VERSION ""

NS_ :

BS_:

BU_: TCM HCM IPMA_ADAS PSCM ABS_ESC TCCM TCM_DSL PCM_HEV PCM ECM_HEVDSL ECM_HEV ECM_Diesel ECM SIMA_DLCS BCMD_IPDB VDM CMR_DSMC SOBDMC_HPCM CHCM GWM _delete AWD_DLCM GENERIC TSTR

BO_ 611 Driveline_Data_1: 8 PCM
 SG_ AwdTerrMdeChng_D_Rdy : 58|3@0+ (1,0) [0|7] "SED"  GWM
 SG_ AwdTerrMde_D_Actl : 50|3@0+ (1,0) [0|7] "SED"  GWM
 SG_ AwdSys_D_Stat : 27|2@0+ (1,0) [0|3] "SED"  GWM,ECM,ECM_Diesel,ECM_HEVDSL,PCM,PCM_HEV
 SG_ SelDrvMdeAwd_D_Stat : 33|2@0+ (1,0) [0|3] "SED"  GWM,ABS_ESC
 SG_ AwdStat_D_RqDsply : 63|5@0+ (1,0) [0|31] "SED"  PCM_HEV,PCM,ABS_ESC,AWD_DLCM,TCM,TCM_DSL,GWM
 SG_ AwdLck_D_Stat : 31|4@0+ (1,0) [0|15] "SED"  ABS_ESC,PSCM,TCM,TCM_DSL,GWM,PCM
 SG_ AwdSrvcRqd_B_Rq : 0|1@0+ (1,0) [0|1] "SED"  TCM,ABS_ESC,PCM,PCM_HEV,TCM_DSL,GWM
 SG_ AwdDrvMde_D_Stat : 38|3@0+ (1,0) [0|7] "SED"  GWM,PSCM
 SG_ NtrlTowAvail_B_Stat : 4|1@0+ (1,0) [0|1] "SED"  GWM
 SG_ AwdLck_Tq_Rq : 15|12@0+ (1,0) [0|4093] "Nm"  PCM_HEV,PCM,ABS_ESC,GWM,SOBDMC_HPCM
 SG_ TrnAout_Tq_RqMx : 47|13@0+ (1,-1250) [-1250|6941] "Nm"  GWM,ECM,ECM_Diesel,ECM_HEVDSL,PCM,PCM_HEV
 SG_ AwdOffRoadMode_D_Stats : 25|2@0+ (1,0) [0|3] "SED"  IPMA_ADAS,GWM,ABS_ESC
 SG_ AwdLoLamp_D_RqDsply : 35|2@0+ (1,0) [0|3] "SED"  GWM
 SG_ AwdHiLamp_D_RqDsply : 19|2@0+ (1,0) [0|3] "SED"  GWM,ABS_ESC
 SG_ AwdAutoLamp_D_RqDsply : 17|2@0+ (1,0) [0|3] "SED"  GWM,ABS_ESC
 SG_ Awd2wdLamp_D_RqDsply : 2|2@0+ (1,0) [0|3] "SED"  GWM
 SG_ AwdRnge_D_Actl : 7|3@0+ (1,0) [0|7] "SED"  TCM,ECM,ECM_Diesel,ECM_HEVDSL,PCM,PCM_HEV,TCM_DSL,ABS_ESC,PSCM,SOBDMC_HPCM,VDM,GWM,CHCM,AWD_DLCM,IPMA_ADAS

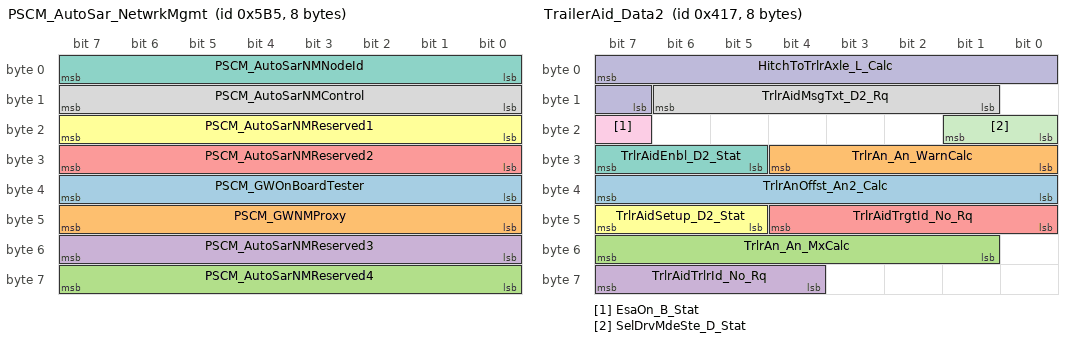
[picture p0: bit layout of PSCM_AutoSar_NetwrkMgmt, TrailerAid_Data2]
BO_ 1461 PSCM_AutoSar_NetwrkMgmt: 8 PSCM
 SG_ PSCM_GWOnBoardTester : 39|8@0+ (1,0) [0|255] "unitless"  HCM,GENERIC,ABS_ESC
 SG_ PSCM_GWNMProxy : 47|8@0+ (1,0) [0|255] "unitless"  HCM,GENERIC,ABS_ESC
 SG_ PSCM_AutoSarNMReserved4 : 63|8@0+ (1,0) [0|255] "unitless"  HCM,GENERIC,ABS_ESC
 SG_ PSCM_AutoSarNMReserved3 : 55|8@0+ (1,0) [0|255] "unitless"  HCM,GENERIC,ABS_ESC
 SG_ PSCM_AutoSarNMReserved2 : 31|8@0+ (1,0) [0|255] "unitless"  HCM,ABS_ESC,GENERIC
 SG_ PSCM_AutoSarNMReserved1 : 23|8@0+ (1,0) [0|255] "unitless"  HCM,ABS_ESC,GENERIC
 SG_ PSCM_AutoSarNMNodeId : 7|8@0+ (1,0) [0|255] "unitless"  HCM,ABS_ESC,GENERIC
 SG_ PSCM_AutoSarNMControl : 15|8@0+ (1,0) [0|255] "unitless"  HCM,ABS_ESC,GENERIC

BO_ 1047 TrailerAid_Data2: 8 PSCM
 SG_ TrlrAnOffst_An2_Calc : 39|8@0+ (0.5,-64) [-64|63.5] "degrees"  IPMA_ADAS
 SG_ TrlrAn_An_WarnCalc : 28|5@0+ (1,0) [0|31] "degrees"  IPMA_ADAS
 SG_ TrlrAn_An_MxCalc : 55|7@0+ (1,0) [0|127] "degrees"  IPMA_ADAS
 SG_ TrlrAidTrlrId_No_Rq : 63|4@0+ (1,0) [0|15] "unitless"  GWM
 SG_ TrlrAidTrgtId_No_Rq : 44|5@0+ (1,0) [0|31] "unitless"  IPMA_ADAS
 SG_ TrlrAidSetup_D2_Stat : 47|3@0+ (1,0) [0|7] "SED"  IPMA_ADAS
 SG_ TrlrAidEnbl_D2_Stat : 31|3@0+ (1,0) [0|7] "SED"  ECM_HEV,IPMA_ADAS,GWM,ECM,PCM,ABS_ESC,ECM_Diesel,ECM_HEVDSL,PCM_HEV
 SG_ TrlrAidMsgTxt_D2_Rq : 14|6@0+ (1,0) [0|63] "SED"  IPMA_ADAS,GWM,ABS_ESC
 SG_ EsaOn_B_Stat : 23|1@0+ (1,0) [0|1] "SED"  GWM
 SG_ HitchToTrlrAxle_L_Calc : 7|9@0+ (0.0254,0) [0|12.9794] "meter"  IPMA_ADAS
 SG_ SelDrvMdeSte_D_Stat : 17|2@0+ (1,0) [0|3] "SED"  ABS_ESC

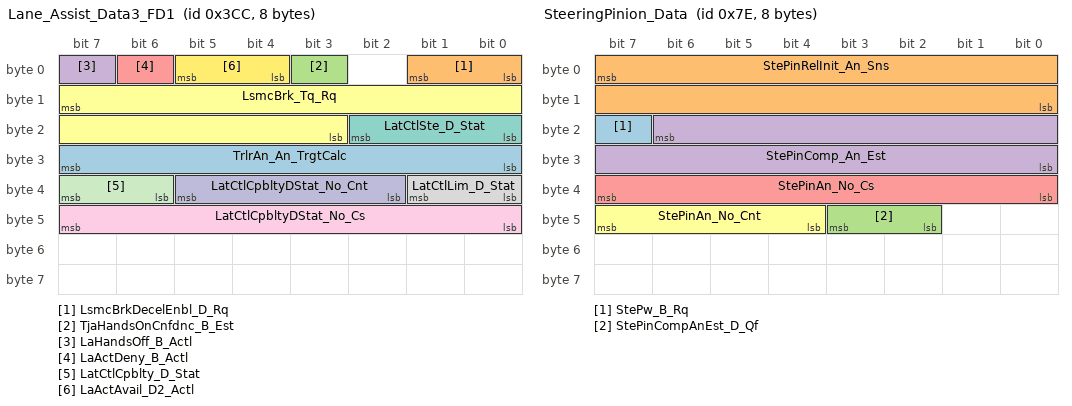
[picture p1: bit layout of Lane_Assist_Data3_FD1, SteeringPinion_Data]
BO_ 972 Lane_Assist_Data3_FD1: 8 PSCM
 SG_ TrlrAn_An_TrgtCalc : 31|8@0+ (1,-128) [-128|127] "degrees"  GWM,IPMA_ADAS
 SG_ LsmcBrkDecelEnbl_D_Rq : 1|2@0+ (1,0) [0|3] "SED"  GWM,ABS_ESC
 SG_ TjaHandsOnCnfdnc_B_Est : 3|1@0+ (1,0) [0|1] "SED"  GWM,IPMA_ADAS
 SG_ LaHandsOff_B_Actl : 7|1@0+ (1,0) [0|1] "SED"  IPMA_ADAS,GWM
 SG_ LaActDeny_B_Actl : 6|1@0+ (1,0) [0|1] "SED"  IPMA_ADAS,GWM
 SG_ LsmcBrk_Tq_Rq : 15|13@0+ (4,0) [0|32764] "Nm"  GWM,ABS_ESC
 SG_ LatCtlSte_D_Stat : 18|3@0+ (1,0) [0|7] "SED"  IPMA_ADAS,GWM
 SG_ LatCtlLim_D_Stat : 33|2@0+ (1,0) [0|3] "SED"  IPMA_ADAS,GWM
 SG_ LatCtlCpbltyDStat_No_Cs : 47|8@0+ (1,0) [0|255] "Unitless"  GWM,IPMA_ADAS
 SG_ LatCtlCpbltyDStat_No_Cnt : 37|4@0+ (1,0) [0|15] "Unitless"  GWM,IPMA_ADAS
 SG_ LatCtlCpblty_D_Stat : 39|2@0+ (1,0) [0|3] "SED"  GWM,IPMA_ADAS
 SG_ LaActAvail_D2_Actl : 5|2@0+ (1,0) [0|3] "SED"  IPMA_ADAS,GWM

BO_ 130 EPAS_INFO: 8 PSCM
 SG_ TrlrHitchLamp_D_Rqst : 24|1@0+ (1,0) [0|1] "SED"  IPMA_ADAS,GWM
 SG_ VehVTrlrAid_B_Rq : 25|1@0+ (1,0) [0|1] "SED"  ECM_HEV,ECM,ECM_Diesel,ECM_HEVDSL,PCM,PCM_HEV
 SG_ SteEffort_D_Stat : 52|3@0+ (1,0) [0|7] "SED"  GWM
 SG_ Veh_V_RqMxTrlrAid : 63|8@0+ (0.1,0) [0|25.5] "km/h"  ECM_HEV,ECM,ECM_Diesel,ECM_HEVDSL,PCM,PCM_HEV
 SG_ DrvSteActv_B_Stat : 10|1@0+ (1,0) [0|1] "SED"  ABS_ESC
 SG_ DrvSte_Tq_Actl : 47|8@0+ (0.0625,-8) [-8|7.8125] "Nm"  ABS_ESC
 SG_ SteMdule_D_Stat : 55|3@0+ (1,0) [0|7] "SED"  GWM
 SG_ SteMdule_U_Meas : 39|8@0+ (0.05,6) [6|18.7] "Volts"  GWM
 SG_ SteMdule_I_Est : 21|12@0+ (0.05,-64) [-64|140.7] "Amps"  GWM
 SG_ EPAS_Failure : 9|2@0+ (1,0) [0|3] "SED"  IPMA_ADAS,GWM
 SG_ SteeringColumnTorque : 7|8@0+ (0.0625,-8) [-8|7.8125] "Nm"  IPMA_ADAS,ABS_ESC
 SG_ SAPPAngleControlStat6 : 15|1@0+ (1,0) [0|1] "SED"  IPMA_ADAS
 SG_ SAPPAngleControlStat5 : 14|1@0+ (1,0) [0|1] "SED"  IPMA_ADAS
 SG_ SAPPAngleControlStat4 : 13|1@0+ (1,0) [0|1] "SED"  IPMA_ADAS
 SG_ SAPPAngleControlStat3 : 12|1@0+ (1,0) [0|1] "SED"  IPMA_ADAS
 SG_ SAPPAngleControlStat2 : 11|1@0+ (1,0) [0|1] "SED"  IPMA_ADAS
 SG_ SAPPAngleControlStat1 : 23|2@0+ (1,0) [0|3] "SED"  IPMA_ADAS

BO_ 126 SteeringPinion_Data: 8 PSCM
 SG_ StePw_B_Rq : 23|1@0+ (1,0) [0|1] "SED"  GWM,ECM,ECM_Diesel,ECM_HEV,ECM_HEVDSL,PCM,PCM_HEV
 SG_ StePinRelInit_An_Sns : 7|16@0+ (0.1,-3200) [-3200|3353.3] "degrees"  VDM,IPMA_ADAS,GWM,ECM,ECM_Diesel,ECM_HEV,ECM_HEVDSL,PCM,PCM_HEV,ABS_ESC,TCCM,AWD_DLCM
 SG_ StePinCompAnEst_D_Qf : 43|2@0+ (1,0) [0|3] "SED"  CMR_DSMC,TCM,VDM,SOBDMC_HPCM,HCM,IPMA_ADAS,TCM_DSL,ECM,ECM_Diesel,ECM_HEV,ECM_HEVDSL,PCM,PCM_HEV,ABS_ESC,TCCM,AWD_DLCM,GWM
 SG_ StePinComp_An_Est : 22|15@0+ (0.1,-1600) [-1600|1676.7] "degrees"  CMR_DSMC,TCM,VDM,SOBDMC_HPCM,HCM,IPMA_ADAS,TCM_DSL,ECM,ECM_Diesel,ECM_HEV,ECM_HEVDSL,PCM,PCM_HEV,ABS_ESC,TCCM,AWD_DLCM,GWM
 SG_ StePinAn_No_Cs : 39|8@0+ (1,0) [0|255] "Unitless"  VDM,ABS_ESC,TCCM,GWM,ECM,ECM_Diesel,ECM_HEVDSL,PCM,PCM_HEV,AWD_DLCM
 SG_ StePinAn_No_Cnt : 47|4@0+ (1,0) [0|15] "unitless"  VDM,TCCM,GWM,ECM,ECM_Diesel,ECM_HEVDSL,PCM,PCM_HEV,ABS_ESC,AWD_DLCM

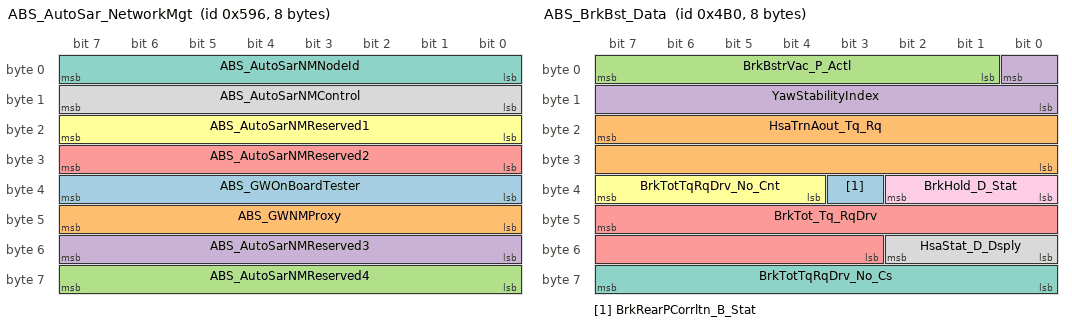
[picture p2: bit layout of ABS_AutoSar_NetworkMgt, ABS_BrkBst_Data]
BO_ 1430 ABS_AutoSar_NetworkMgt: 8 ABS_ESC
 SG_ ABS_GWOnBoardTester : 39|8@0+ (1,0) [0|255] "unitless"  HCM,GENERIC
 SG_ ABS_GWNMProxy : 47|8@0+ (1,0) [0|255] "unitless"  HCM,GENERIC
 SG_ ABS_AutoSarNMReserved4 : 63|8@0+ (1,0) [0|255] "unitless"  HCM,GENERIC
 SG_ ABS_AutoSarNMReserved3 : 55|8@0+ (1,0) [0|255] "unitless"  HCM,GENERIC
 SG_ ABS_AutoSarNMReserved2 : 31|8@0+ (1,0) [0|255] "unitless"  HCM,GENERIC
 SG_ ABS_AutoSarNMReserved1 : 23|8@0+ (1,0) [0|255] "unitless"  HCM,GENERIC
 SG_ ABS_AutoSarNMNodeId : 7|8@0+ (1,0) [0|255] "unitless"  HCM,GENERIC
 SG_ ABS_AutoSarNMControl : 15|8@0+ (1,0) [0|255] "unitless"  HCM,GENERIC

BO_ 1200 ABS_BrkBst_Data: 8 ABS_ESC
 SG_ BrkRearPCorrltn_B_Stat : 35|1@0+ (1,0) [0|1] "SED"  GWM
 SG_ HsaTrnAout_Tq_Rq : 23|16@0+ (4,-131072) [-131072|131060] "Nm"  TCM,TCM_DSL,GWM
 SG_ BrkBstrVac_P_Actl : 7|7@0+ (8,0) [0|1008] "Millibar"  ECM,ECM_Diesel,ECM_HEV,ECM_HEVDSL,PCM,PCM_HEV,GWM
 SG_ YawStabilityIndex : 0|9@0+ (1,-256) [-256|255] "%"  IPMA_ADAS,PSCM,GWM,VDM,CHCM
 SG_ BrkTot_Tq_RqDrv : 47|13@0+ (4,0) [0|32760] "Nm"  SOBDMC_HPCM,TCM,IPMA_ADAS,ECM,ECM_Diesel,ECM_HEV,ECM_HEVDSL,PCM,PCM_HEV,TCM_DSL,GWM,TCCM,PSCM,AWD_DLCM
 SG_ BrkTotTqRqDrv_No_Cnt : 39|4@0+ (1,0) [0|15] "unitless"  ECM,ECM_Diesel,ECM_HEV,ECM_HEVDSL,PCM,PCM_HEV,GWM
 SG_ BrkTotTqRqDrv_No_Cs : 63|8@0+ (1,0) [0|255] "unitless"  ECM,ECM_Diesel,ECM_HEV,ECM_HEVDSL,PCM,PCM_HEV,GWM
 SG_ HsaStat_D_Dsply : 50|3@0+ (1,0) [0|7] "SED"  GWM
 SG_ BrkHold_D_Stat : 34|3@0+ (1,0) [0|7] "SED"  ECM,ECM_Diesel,ECM_HEV,ECM_HEVDSL,IPMA_ADAS,PCM,PCM_HEV,SOBDMC_HPCM,GWM,TCM_DSL

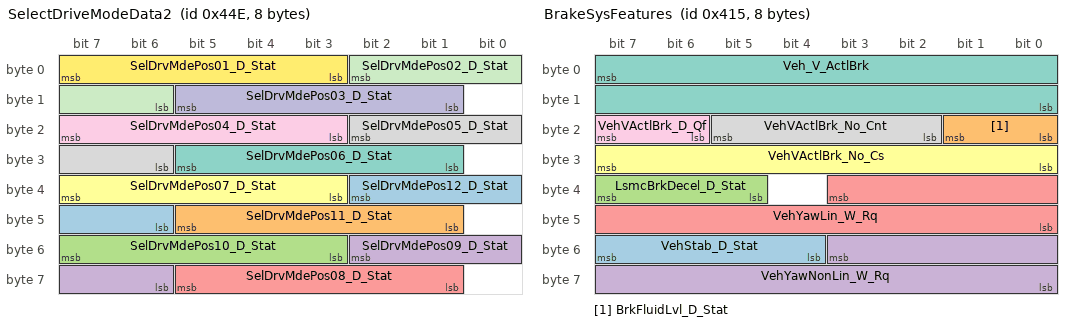
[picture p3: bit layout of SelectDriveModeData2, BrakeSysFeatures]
BO_ 1102 SelectDriveModeData2: 8 ABS_ESC
 SG_ SelDrvMdePos12_D_Stat : 34|5@0+ (1,0) [0|31] "SED"  GWM
 SG_ SelDrvMdePos11_D_Stat : 45|5@0+ (1,0) [0|31] "SED"  GWM
 SG_ SelDrvMdePos10_D_Stat : 55|5@0+ (1,0) [0|31] "SED"  GWM
 SG_ SelDrvMdePos09_D_Stat : 50|5@0+ (1,0) [0|31] "SED"  GWM
 SG_ SelDrvMdePos08_D_Stat : 61|5@0+ (1,0) [0|31] "SED"  GWM
 SG_ SelDrvMdePos07_D_Stat : 39|5@0+ (1,0) [0|31] "SED"  GWM
 SG_ SelDrvMdePos06_D_Stat : 29|5@0+ (1,0) [0|31] "SED"  GWM
 SG_ SelDrvMdePos05_D_Stat : 18|5@0+ (1,0) [0|31] "SED"  GWM
 SG_ SelDrvMdePos04_D_Stat : 23|5@0+ (1,0) [0|31] "SED"  GWM
 SG_ SelDrvMdePos03_D_Stat : 13|5@0+ (1,0) [0|31] "SED"  GWM
 SG_ SelDrvMdePos02_D_Stat : 2|5@0+ (1,0) [0|31] "SED"  GWM
 SG_ SelDrvMdePos01_D_Stat : 7|5@0+ (1,0) [0|31] "SED"  GWM

BO_ 1056 SelectDriveModeData: 8 ABS_ESC
 SG_ AutoEpbButtnOn_B_Stat : 48|1@0+ (1,0) [0|1] "SED"  GWM
 SG_ VehVActlBrk_No_Corr : 7|8@0+ (0.001,0.9) [0.9|1.153] "unitless"  ECM,ECM_Diesel,ECM_HEV,PCM,PCM_HEV,GWM
 SG_ AutoEpbMsgTxt_D_Rq : 58|3@0+ (1,0) [0|7] "SED"  GWM
 SG_ SelDrvMdePos12_B_Avail : 54|1@0+ (1,0) [0|1] "SED"  GWM
 SG_ SelDrvMdePos11_B_Avail : 55|1@0+ (1,0) [0|1] "SED"  GWM
 SG_ SelDrvMdePos10_B_Avail : 40|1@0+ (1,0) [0|1] "SED"  GWM
 SG_ SelDrvMdePos09_B_Avail : 41|1@0+ (1,0) [0|1] "SED"  GWM
 SG_ SelDrvMdePos08_B_Avail : 42|1@0+ (1,0) [0|1] "SED"  GWM
 SG_ SelDrvMdePos07_B_Avail : 43|1@0+ (1,0) [0|1] "SED"  GWM
 SG_ SelDrvMdePos06_B_Avail : 44|1@0+ (1,0) [0|1] "SED"  GWM
 SG_ SelDrvMdePos05_B_Avail : 45|1@0+ (1,0) [0|1] "SED"  GWM
 SG_ SelDrvMdePos04_B_Avail : 46|1@0+ (1,0) [0|1] "SED"  GWM
 SG_ SelDrvMdePos03_B_Avail : 47|1@0+ (1,0) [0|1] "SED"  GWM
 SG_ SelDrvMdePos02_B_Avail : 32|1@0+ (1,0) [0|1] "SED"  GWM
 SG_ SelDrvMdePos01_B_Avail : 24|1@0+ (1,0) [0|1] "SED"  GWM
 SG_ ActvDrvMde_D2_Stat : 53|5@0+ (1,0) [0|31] "SED"  IPMA_ADAS,GWM
 SG_ SelDrvMde_D2_Rq : 63|5@0+ (1,0) [0|31] "SED"  GWM
 SG_ SelDrvMdePt_D_Rq : 31|5@0+ (1,0) [0|31] "SED"  SOBDMC_HPCM,ECM,ECM_Diesel,ECM_HEV,ECM_HEVDSL,PCM,PCM_HEV,GWM,TCCM
 SG_ SelDrvMdeMsgTxt_D_Rq : 19|4@0+ (1,0) [0|15] "SED"  AWD_DLCM,GWM
 SG_ SelDrvMde_D_Stat : 26|2@0+ (1,0) [0|3] "SED"  GWM
 SG_ AwdMde_D_RqBrk : 35|3@0+ (1,0) [0|7] "SED"  GWM,TCCM
 SG_ AutoEpbDsply_D_Stat : 37|2@0+ (1,0) [0|3] "SED"  GWM
 SG_ SelDrvMdeMsgTxt2_D_Rq : 23|4@0+ (1,0) [0|15] "SED"  GWM
 SG_ SelDrvMdeHmi03_D_Rq : 12|5@0+ (1,0) [0|31] "SED"  GWM

BO_ 1054 BrakeSysFeatures_3: 8 ABS_ESC
 SG_ RbaBrk_D_Stat : 63|2@0+ (1,0) [0|3] "SED"  IPMA_ADAS,GWM
 SG_ SelDrvMdeChassis2_D_Rq : 45|5@0+ (1,0) [0|31] "SED"  PSCM,GWM
 SG_ BrkBstrLoLampOn_B_Rq : 24|1@0+ (1,0) [0|1] "SED"  GWM
 SG_ TrailCtl_D_Stat : 55|3@0+ (1,0) [0|7] "SED"  SOBDMC_HPCM,TCM,ECM,ECM_Diesel,ECM_HEV,ECM_HEVDSL,PCM,TCM_DSL,GWM,AWD_DLCM,TCCM
 SG_ TrailCtlMsgTxt_D_Rq : 52|4@0+ (1,0) [0|15] "SED"  GWM
 SG_ BrkPadMsgTxt_D_Rq : 31|2@0+ (1,0) [0|3] "SED"  GWM
 SG_ BrkBstrVac_D_Stat : 18|2@0+ (1,0) [0|3] "SED"  ECM_HEV,ECM,ECM_Diesel,ECM_HEVDSL,PCM,PCM_HEV,GWM
 SG_ DrvSlipCtlOffLamp_D_Rq : 23|2@0+ (1,0) [0|3] "SED"  GWM
 SG_ DrvSlipCtlMdeMsg_D_Rq : 13|5@0+ (1,0) [0|31] "SED"  GWM
 SG_ HdcOn_B_Ind : 16|1@0+ (1,0) [0|1] "SED"  GWM
 SG_ AutoHoldMsgTxt_D_Rq : 4|4@0+ (1,0) [0|15] "SED"  GWM
 SG_ CtaBrk_D_Stat : 47|2@0+ (1,0) [0|3] "SED"  GWM,IPMA_ADAS
 SG_ SelDrvMdeAwd_D_Rq : 29|5@0+ (1,0) [0|31] "SED"  ECM_HEV,TCCM,GWM,PCM,AWD_DLCM
 SG_ AutoHoldSwMde_B_Ind : 0|1@0+ (1,0) [0|1] "SED"  GWM
 SG_ AutoHoldMde_D_Ind : 15|2@0+ (1,0) [0|3] "SED"  GWM
 SG_ BrkMdeInhbt_B_RqDsply : 8|1@0+ (1,0) [0|1] "SED"  GWM
 SG_ BrkLineLck_D_Stat : 21|3@0+ (1,0) [0|7] "SED"  GWM,TCM,TCM_DSL
 SG_ SelDrvMdeChassis_D_Rq : 39|5@0+ (1,0) [0|31] "SED"  PSCM,GWM,VDM,CHCM
 SG_ ApaBrk_D_Stat : 34|2@0+ (1,0) [0|3] "SED"  ECM,ECM_Diesel,ECM_HEV,ECM_HEVDSL,IPMA_ADAS,PCM,PCM_HEV,GWM
 SG_ SelDrvMdeChassis3_D_Rq : 61|5@0+ (1,0) [0|31] "SED"  CHCM,GWM
 SG_ TrailOnePdlTqLm_B_Actl : 56|1@0+ (1,0) [0|1] "SED"  ECM_HEV,ECM_Diesel,PCM,GWM
 SG_ OnePdlDrvDeny_B_Stat : 40|1@0+ (1,0) [0|1] "SED"  ECM_HEV,PCM_HEV,GWM,ECM,PCM
 SG_ BrkDrvMde_D_Stat : 7|3@0+ (1,0) [0|7] "SED"  GWM
 SG_ AirDamUp_B_RqBrk : 32|1@0+ (1,0) [0|1] "SED"  ECM_Diesel,ECM_HEV,ECM_HEVDSL,PCM,PCM_HEV,GWM
 SG_ FrontDiffElckrOpen_B_Rq : 48|1@0+ (1,0) [0|1] "SED"  AWD_DLCM,GWM

BO_ 1046 BrakeSysFeatures_2: 8 ABS_ESC
 SG_ PrkBrkDynmc_D_Allw : 39|2@0+ (1,0) [0|3] "SED"  GWM
 SG_ BrkPrkBrkDynmc_B_Actl : 24|1@0+ (1,0) [0|1] "SED"  GWM
 SG_ ReserveTracCtlPtActv : 28|1@0+ (1,0) [0|1] "SED"  GENERIC,GWM
 SG_ HsaMde_D_Mem : 33|2@0+ (1,0) [0|3] "SED"  GWM
 SG_ BrkBstrVac_B_Rq : 27|1@0+ (1,0) [0|1] "Discrete"  ECM_HEV,SOBDMC_HPCM,ECM,ECM_Diesel,ECM_HEVDSL,PCM,PCM_HEV,GWM
 SG_ HdcMde_D_Actl : 31|3@0+ (1,0) [0|7] "SED"  SOBDMC_HPCM,TCM,ECM,ECM_Diesel,ECM_HEVDSL,PCM,PCM_HEV,TCM_DSL,GWM,AWD_DLCM
 SG_ RearDiffLck_Tq2_RqMx : 51|12@0+ (4,0) [0|16376] "Nm"  ECM,ECM_Diesel,ECM_HEV,ECM_HEVDSL,TCCM,GWM,PCM,AWD_DLCM
 SG_ TRLR_SWAY_EVNT_IN_PROG : 25|1@0+ (1,0) [0|1] "SED"  GWM
 SG_ TRLR_SWAY_CONFIG_STAT : 26|1@0+ (1,0) [0|1] "SED"  GWM
 SG_ TCMode : 15|1@0+ (1,0) [0|1] "SED"  SOBDMC_HPCM,TCM,IPMA_ADAS,ECM,ECM_Diesel,ECM_HEV,ECM_HEVDSL,PCM,PCM_HEV,TCM_DSL,PSCM,VDM,GWM,AWD_DLCM
 SG_ DrvSlipCtlLamp_D_Rq : 42|2@0+ (1,0) [0|3] "SED"  IPMA_ADAS,ECM,ECM_Diesel,ECM_HEV,ECM_HEVDSL,PCM,PCM_HEV,GWM,VDM,AWD_DLCM
 SG_ Abs_B_Falt : 5|1@0+ (1,0) [0|1] "SED"  TCM,SOBDMC_HPCM,ECM,ECM_Diesel,ECM_HEV,ECM_HEVDSL,PCM,PCM_HEV,TCM_DSL,GWM
 SG_ DrvSlipCtlMde_D_Ind : 44|2@0+ (1,0) [0|3] "SED"  TCM,SOBDMC_HPCM,IPMA_ADAS,ECM,ECM_Diesel,ECM_HEV,ECM_HEVDSL,PCM,PCM_HEV,TCM_DSL,PSCM,GWM,AWD_DLCM,TCCM
 SG_ DrvAntiLckLamp_D_Rq : 55|2@0+ (1,0) [0|3] "SED"  TCM,ECM,ECM_Diesel,ECM_HEV,ECM_HEVDSL,TCM_DSL,GWM,IPMA_ADAS
 SG_ BpedMove_No_Cnt : 3|4@0+ (1,0) [0|15] "Unitless"  SOBDMC_HPCM,ECM,ECM_Diesel,ECM_HEV,ECM_HEVDSL,PCM,PCM_HEV,GWM
 SG_ StabCtlBrk_B_Avail : 4|1@0+ (1,0) [0|1] "SED"  PCM,PCM_HEV,TCM,ECM,ECM_Diesel,ECM_HEV,ECM_HEVDSL,TCM_DSL,TCCM,GWM,VDM,CHCM,AWD_DLCM
 SG_ DrvHdcWarnInfo_D_Rq : 35|2@0+ (1,0) [0|3] "SED"  TCM,ECM,ECM_Diesel,ECM_HEV,ECM_HEVDSL,TCM_DSL,GWM
 SG_ DrvHdcMsg_D_Rq : 10|3@0+ (1,0) [0|7] "SED"  TCM,ECM,ECM_Diesel,ECM_HEV,ECM_HEVDSL,TCM_DSL,GWM
 SG_ DrvHdcLampInfo_D_Rq : 12|2@0+ (1,0) [0|3] "SED"  TCM,ECM,ECM_Diesel,ECM_HEV,ECM_HEVDSL,TCM_DSL,GWM
 SG_ BpedMove_D_Actl : 7|2@0+ (1,0) [0|3] "SED"  SOBDMC_HPCM,ECM,ECM_Diesel,ECM_HEV,ECM_HEVDSL,PCM,PCM_HEV,GWM
 SG_ ChimeBrk_B_Rq : 14|1@0+ (1,0) [0|1] "SED"  TCM,ECM,ECM_Diesel,ECM_HEV,ECM_HEVDSL,TCM_DSL,GWM
 SG_ BrkLamp_B_Rq : 13|1@0+ (1,0) [0|1] "SED"  TCM,ECM,ECM_Diesel,ECM_HEV,ECM_HEVDSL,TCM_DSL,GWM
 SG_ HILL_DESC_MC : 47|3@0+ (1,0) [0|7] "SED"  TCM,ECM,ECM_Diesel,ECM_HEV,ECM_HEVDSL,TCM_DSL,GWM
 SG_ BpedDiffLckTq_No_Cs : 23|8@0+ (1,0) [0|255] "Unitless"  SOBDMC_HPCM,GWM
 SG_ RearDiffElckrOpen_B_Rq : 40|1@0+ (1,0) [0|1] "SED"  SOBDMC_HPCM,GWM,AWD_DLCM,TCCM

BO_ 1045 BrakeSysFeatures: 8 ABS_ESC
 SG_ VehStab_D_Stat : 55|4@0+ (1,0) [0|15] "SED"  SOBDMC_HPCM,PCM_HEV,PCM,ECM,ECM_Diesel,ECM_HEV,ECM_HEVDSL,TCCM,GWM,HCM,AWD_DLCM,CHCM
 SG_ BrkFluidLvl_D_Stat : 17|2@0+ (1,0) [0|3] "SED"  GWM
 SG_ LsmcBrkDecel_D_Stat : 39|3@0+ (1,0) [0|7] "SED"  PSCM,GWM
 SG_ VehYawNonLin_W_Rq : 51|12@0+ (0.03663,-75) [-75|74.92659] "deg/s"  SOBDMC_HPCM,ECM,ECM_Diesel,ECM_HEV,ECM_HEVDSL,PCM,PCM_HEV,GWM,AWD_DLCM,CHCM
 SG_ VehYawLin_W_Rq : 35|12@0+ (0.03663,-75) [-75|74.92659] "deg/s"  SOBDMC_HPCM,ECM,ECM_Diesel,ECM_HEV,ECM_HEVDSL,PCM,PCM_HEV,GWM,AWD_DLCM,CHCM
 SG_ VehVActlBrk_No_Cs : 31|8@0+ (1,0) [0|255] "Unitless"  VDM,TCM,SOBDMC_HPCM,ECM,ECM_Diesel,ECM_HEV,ECM_HEVDSL,PCM,PCM_HEV,PSCM,TCM_DSL,GWM,CHCM,TCCM,AWD_DLCM,CMR_DSMC,IPMA_ADAS
 SG_ Veh_V_ActlBrk : 7|16@0+ (0.01,0) [0|655.35] "kph"  VDM,TCM,SOBDMC_HPCM,IPMA_ADAS,ECM,ECM_Diesel,ECM_HEV,ECM_HEVDSL,PCM,PCM_HEV,PSCM,TCM_DSL,GWM,TCCM,CHCM,AWD_DLCM,CMR_DSMC
 SG_ VehVActlBrk_No_Cnt : 21|4@0+ (1,0) [0|15] "Unitless"  VDM,TCM,SOBDMC_HPCM,ECM,ECM_Diesel,ECM_HEV,ECM_HEVDSL,PCM,PCM_HEV,PSCM,TCM_DSL,GWM,CHCM,TCCM,AWD_DLCM,CMR_DSMC,IPMA_ADAS
 SG_ VehVActlBrk_D_Qf : 23|2@0+ (1,0) [0|3] "SED"  TCM,SOBDMC_HPCM,IPMA_ADAS,ECM,ECM_Diesel,ECM_HEV,ECM_HEVDSL,PCM,PCM_HEV,PSCM,TCM_DSL,GWM,TCCM,CHCM,AWD_DLCM,CMR_DSMC,VDM

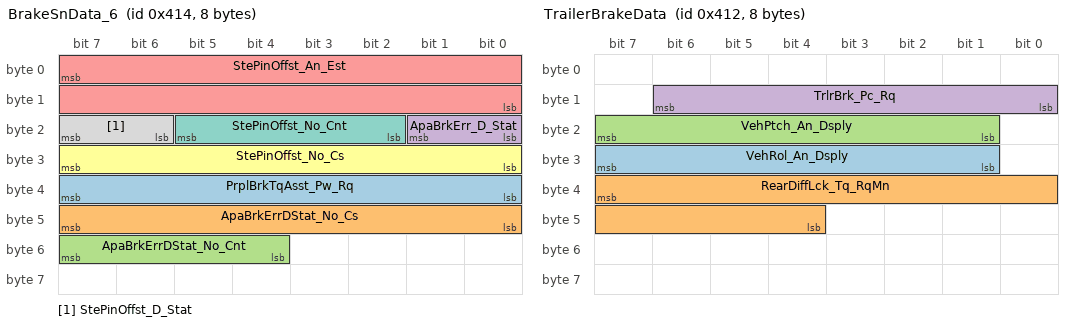
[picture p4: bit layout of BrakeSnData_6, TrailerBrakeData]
BO_ 1044 BrakeSnData_6: 8 ABS_ESC
 SG_ PrplBrkTqAsst_Pw_Rq : 39|8@0+ (100,0) [0|25500] "watts"  SOBDMC_HPCM,GWM
 SG_ ApaBrkErrDStat_No_Cs : 47|8@0+ (1,0) [0|255] "Unitless"  ECM_HEV,PCM,SOBDMC_HPCM,GWM
 SG_ ApaBrkErrDStat_No_Cnt : 55|4@0+ (1,0) [0|15] "Unitless"  ECM_HEV,PCM,SOBDMC_HPCM,GWM
 SG_ ApaBrkErr_D_Stat : 17|2@0+ (1,0) [0|3] "SED"  GWM,SOBDMC_HPCM,PCM,ECM_HEV
 SG_ StePinOffst_An_Est : 7|16@0+ (0.1,-3200) [-3200|3353.3] "degrees"  GWM,PSCM
 SG_ StePinOffst_No_Cs : 31|8@0+ (1,0) [0|255] "Unitless"  GWM,PSCM
 SG_ StePinOffst_No_Cnt : 21|4@0+ (1,0) [0|15] "unitless"  GWM,PSCM
 SG_ StePinOffst_D_Stat : 23|2@0+ (1,0) [0|3] "SED"  GWM,PSCM

BO_ 1042 TrailerBrakeData: 8 ABS_ESC
 SG_ VehRol_An_Dsply : 31|7@0+ (1,-64) [-64|61] "degrees"  GWM
 SG_ RearDiffLck_Tq_RqMn : 39|12@0+ (4,0) [0|16376] "Nm"  GWM,ECM,ECM_Diesel,ECM_HEV,ECM_HEVDSL,TCCM,PCM
 SG_ VehPtch_An_Dsply : 23|7@0+ (1,-64) [-64|61] "degrees"  GWM,TCCM
 SG_ TrlrBrk_Pc_Rq : 14|7@0+ (1,0) [0|127] "percent"  GWM

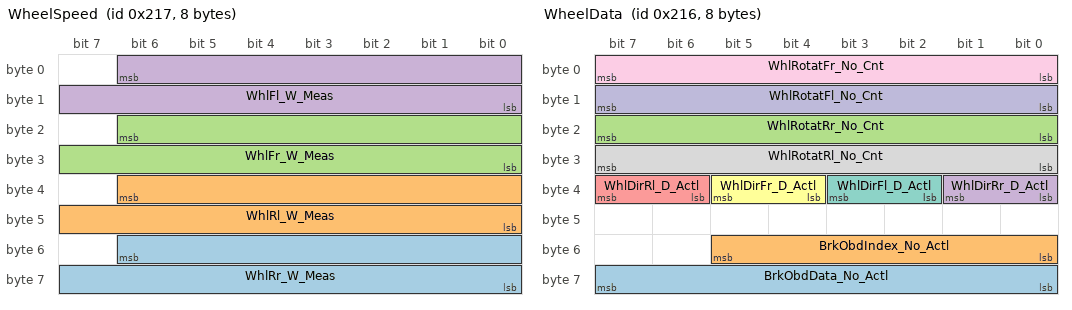
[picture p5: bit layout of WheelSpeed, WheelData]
BO_ 535 WheelSpeed: 8 ABS_ESC
 SG_ WhlRr_W_Meas : 54|15@0+ (0.01,0) [0|327.65] "rad/s"  TCM,CHCM,VDM,SOBDMC_HPCM,IPMA_ADAS,GWM,ECM,ECM_Diesel,ECM_HEV,ECM_HEVDSL,PCM,PCM_HEV,PSCM,TCCM,TCM_DSL,AWD_DLCM
 SG_ WhlRl_W_Meas : 38|15@0+ (0.01,0) [0|327.65] "rad/s"  TCM,CHCM,VDM,SOBDMC_HPCM,IPMA_ADAS,GWM,ECM,ECM_Diesel,ECM_HEV,ECM_HEVDSL,PCM,PCM_HEV,PSCM,TCCM,TCM_DSL,AWD_DLCM
 SG_ WhlFr_W_Meas : 22|15@0+ (0.01,0) [0|327.65] "rad/s"  TCM,CHCM,VDM,SOBDMC_HPCM,IPMA_ADAS,GWM,ECM,ECM_Diesel,ECM_HEV,ECM_HEVDSL,PCM,PCM_HEV,PSCM,TCCM,TCM_DSL,AWD_DLCM
 SG_ WhlFl_W_Meas : 6|15@0+ (0.01,0) [0|327.65] "rad/s"  TCM,CHCM,VDM,SOBDMC_HPCM,IPMA_ADAS,GWM,ECM,ECM_Diesel,ECM_HEV,ECM_HEVDSL,PCM,PCM_HEV,PSCM,TCCM,TCM_DSL,AWD_DLCM

BO_ 534 WheelData: 8 ABS_ESC
 SG_ BrkObdData_No_Actl : 63|8@0+ (1,0) [0|255] "unitless"  SOBDMC_HPCM,GWM
 SG_ BrkObdIndex_No_Actl : 53|6@0+ (1,0) [0|63] "unitless"  SOBDMC_HPCM,GWM
 SG_ WhlRotatRr_No_Cnt : 23|8@0+ (1,0) [0|255] "Unitless"  TCM,IPMA_ADAS,GWM,PSCM,ECM,ECM_Diesel,ECM_HEVDSL,TCM_DSL
 SG_ WhlDirRr_D_Actl : 33|2@0+ (1,0) [0|3] "SED"  TCM,CHCM,IPMA_ADAS,GWM,ECM,ECM_Diesel,ECM_HEVDSL,PCM,PCM_HEV,PSCM,TCM_DSL,ECM_HEV
 SG_ WhlDirRl_D_Actl : 39|2@0+ (1,0) [0|3] "SED"  TCM,CHCM,IPMA_ADAS,GWM,PSCM,ECM,ECM_Diesel,ECM_HEVDSL,PCM,PCM_HEV,TCM_DSL,ECM_HEV
 SG_ WhlDirFr_D_Actl : 37|2@0+ (1,0) [0|3] "SED"  TCM,CHCM,IPMA_ADAS,GWM,ECM,ECM_Diesel,ECM_HEVDSL,PCM,PCM_HEV,PSCM,TCM_DSL,ECM_HEV
 SG_ WhlDirFl_D_Actl : 35|2@0+ (1,0) [0|3] "SED"  TCM,CHCM,IPMA_ADAS,GWM,ECM,ECM_Diesel,ECM_HEVDSL,PCM,PCM_HEV,PSCM,TCM_DSL,ECM_HEV
 SG_ WhlRotatRl_No_Cnt : 31|8@0+ (1,0) [0|255] "Unitless"  TCM,IPMA_ADAS,GWM,PSCM,ECM,ECM_Diesel,ECM_HEVDSL,TCM_DSL
 SG_ WhlRotatFr_No_Cnt : 7|8@0+ (1,0) [0|255] "Unitless"  TCM,IPMA_ADAS,GWM,PSCM,ECM,ECM_Diesel,ECM_HEVDSL,TCM_DSL
 SG_ WhlRotatFl_No_Cnt : 15|8@0+ (1,0) [0|255] "Unitless"  TCM,IPMA_ADAS,GWM,PSCM,ECM,ECM_Diesel,ECM_HEVDSL,TCM_DSL

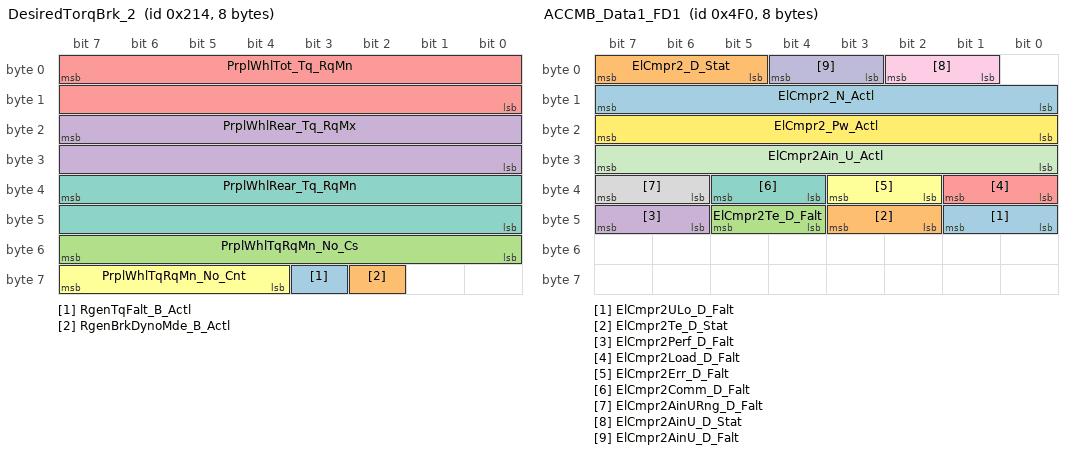
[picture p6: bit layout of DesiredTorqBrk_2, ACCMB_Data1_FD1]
BO_ 532 DesiredTorqBrk_2: 8 ABS_ESC
 SG_ RgenTqFalt_B_Actl : 59|1@0+ (1,0) [0|1] "SED"  SOBDMC_HPCM,GWM,PCM_HEV,ECM_HEVDSL
 SG_ RgenBrkDynoMde_B_Actl : 58|1@0+ (1,0) [0|1] "SED"  ECM_HEV,SOBDMC_HPCM,GWM,PCM_HEV
 SG_ PrplWhlTqRqMn_No_Cs : 55|8@0+ (1,0) [0|255] "Unitless"  SOBDMC_HPCM,GWM,ECM,ECM_Diesel,ECM_HEV,ECM_HEVDSL,PCM,PCM_HEV
 SG_ PrplWhlRear_Tq_RqMx : 23|16@0+ (4,-131072) [-131072|131068] "Nm"  GWM,ECM,ECM_Diesel,ECM_HEVDSL,PCM,PCM_HEV
 SG_ PrplWhlTot_Tq_RqMn : 7|16@0+ (4,-131072) [-131072|131068] "Nm"  SOBDMC_HPCM,GWM,ECM,ECM_Diesel,ECM_HEV,ECM_HEVDSL,PCM,PCM_HEV,AWD_DLCM
 SG_ PrplWhlTqRqMn_No_Cnt : 63|4@0+ (1,0) [0|15] "Unitless"  SOBDMC_HPCM,GWM,ECM,ECM_Diesel,ECM_HEV,ECM_HEVDSL,PCM,PCM_HEV
 SG_ PrplWhlRear_Tq_RqMn : 39|16@0+ (4,-131072) [-131072|131068] "Nm"  SOBDMC_HPCM,GWM,ECM,ECM_Diesel,ECM_HEVDSL,PCM,PCM_HEV

BO_ 1264 ACCMB_Data1_FD1: 8 ACCMB
 SG_ ElCmpr2ULo_D_Falt : 41|2@0+ (1,0) [0|3] "SED"  SOBDMC_HPCM
 SG_ ElCmpr2Te_D_Stat : 43|2@0+ (1,0) [0|3] "SED"  SOBDMC_HPCM
 SG_ ElCmpr2Te_D_Falt : 45|2@0+ (1,0) [0|3] "SED"  SOBDMC_HPCM
 SG_ ElCmpr2Perf_D_Falt : 47|2@0+ (1,0) [0|3] "SED"  SOBDMC_HPCM
 SG_ ElCmpr2Load_D_Falt : 33|2@0+ (1,0) [0|3] "SED"  SOBDMC_HPCM
 SG_ ElCmpr2Err_D_Falt : 35|2@0+ (1,0) [0|3] "SED"  SOBDMC_HPCM
 SG_ ElCmpr2Comm_D_Falt : 37|2@0+ (1,0) [0|3] "SED"  SOBDMC_HPCM
 SG_ ElCmpr2AinURng_D_Falt : 39|2@0+ (1,0) [0|3] "SED"  SOBDMC_HPCM
 SG_ ElCmpr2AinU_D_Stat : 2|2@0+ (1,0) [0|3] "SED"  SOBDMC_HPCM
 SG_ ElCmpr2AinU_D_Falt : 4|2@0+ (1,0) [0|3] "SED"  SOBDMC_HPCM
 SG_ ElCmpr2Ain_U_Actl : 31|8@0+ (2,0) [0|510] "volt"  SOBDMC_HPCM
 SG_ ElCmpr2_Pw_Actl : 23|8@0+ (40,0) [0|10160] "watts"  SOBDMC_HPCM
 SG_ ElCmpr2_N_Actl : 15|8@0+ (50,0) [0|12700] "RPM"  SOBDMC_HPCM
 SG_ ElCmpr2_D_Stat : 7|3@0+ (1,0) [0|7] "SED"  SOBDMC_HPCM

BO_ 531 DesiredTorqBrk: 8 ABS_ESC
 SG_ PrkBrkMsgTxt_D_Rq : 36|4@0+ (1,0) [0|15] "SED"  ECM,ECM_Diesel,ECM_HEV,ECM_HEVDSL,TCM,TCM_DSL,GWM
 SG_ VehStop_D_Stat : 28|2@0+ (1,0) [0|3] "SED"  IPMA_ADAS,GWM
 SG_ TracCtlPtActv_B_Actl : 31|1@0+ (1,0) [0|1] "SED"  SOBDMC_HPCM,TCM,IPMA_ADAS,TCCM,ECM,ECM_Diesel,ECM_HEV,ECM_HEVDSL,PCM,PCM_HEV,TCM_DSL,VDM,AWD_DLCM,GWM
 SG_ LscmbbMntr_B_Err : 17|1@0+ (1,0) [0|1] "SED"  GWM
 SG_ LscmbbBrkDis_B_Actl : 19|1@0+ (1,0) [0|1] "SED"  GWM
 SG_ LscmbbDeny_B_ActlBrk : 18|1@0+ (1,0) [0|1] "SED"  SOBDMC_HPCM,ECM,ECM_Diesel,ECM_HEVDSL,PCM,PCM_HEV,GWM
 SG_ VehicleStationary : 39|1@0+ (1,0) [0|1] "SED"  GWM,AWD_DLCM
 SG_ LscmbbBrkDecel_B_Actl : 20|1@0+ (1,0) [0|1] "SED"  GWM
 SG_ AbsActv_B_Actl : 45|1@0+ (1,0) [0|1] "SED"  TCM,SOBDMC_HPCM,IPMA_ADAS,ECM,ECM_Diesel,ECM_HEV,ECM_HEVDSL,PCM,PCM_HEV,TCM_DSL,PSCM,GWM,VDM,AWD_DLCM
 SG_ StabCtlBrkActv_B_Actl : 23|1@0+ (1,0) [0|1] "SED"  SOBDMC_HPCM,TCM,IPMA_ADAS,ECM_HEV,ECM_HEVDSL,PCM,PCM_HEV,TCM_DSL,PSCM,TCCM,ECM,ECM_Diesel,VDM,CHCM,GWM,AWD_DLCM
 SG_ CmbbBrkPrchg_B_Actl : 59|1@0+ (1,0) [0|1] "SED"  TCM,IPMA_ADAS,ECM,ECM_Diesel,ECM_HEV,ECM_HEVDSL,TCM_DSL,GWM
 SG_ CmbbBrkDecel_B_Actl : 58|1@0+ (1,0) [0|1] "SED"  TCM,IPMA_ADAS,ECM,ECM_Diesel,ECM_HEV,ECM_HEVDSL,TCM_DSL,GWM
 SG_ CmbbBaSensInc_B_Actl : 57|1@0+ (1,0) [0|1] "SED"  TCM,IPMA_ADAS,ECM,ECM_Diesel,ECM_HEV,ECM_HEVDSL,TCM_DSL,GWM
 SG_ AccBrkWarm_B_Actl : 63|1@0+ (1,0) [0|1] "SED"  TCM,IPMA_ADAS,ECM,ECM_Diesel,ECM_HEV,ECM_HEVDSL,TCM_DSL,GWM
 SG_ AccBrkTotTqMn_B_Actl : 62|1@0+ (1,0) [0|1] "SED"  TCM,IPMA_ADAS,ECM,ECM_Diesel,ECM_HEV,ECM_HEVDSL,TCM_DSL,GWM
 SG_ AccBrkPrchgActv_B_Actl : 61|1@0+ (1,0) [0|1] "SED"  TCM,IPMA_ADAS,ECM,ECM_Diesel,ECM_HEV,ECM_HEVDSL,TCM_DSL,GWM
 SG_ AccBrkDis_B_Actl : 44|1@0+ (1,0) [0|1] "SED"  TCM,IPMA_ADAS,ECM,ECM_Diesel,ECM_HEV,ECM_HEVDSL,TCM_DSL,GWM
 SG_ AccBrkDeny_B_Actl : 42|1@0+ (1,0) [0|1] "SED"  TCM,IPMA_ADAS,ECM,ECM_Diesel,ECM_HEV,ECM_HEVDSL,PCM,PCM_HEV,TCM_DSL,GWM
 SG_ AccBrkActv_B_Actl : 43|1@0+ (1,0) [0|1] "SED"  TCM,IPMA_ADAS,ECM,ECM_Diesel,ECM_HEV,ECM_HEVDSL,TCM_DSL,GWM
 SG_ PrplDrgCtlActv_B_Actl : 46|1@0+ (1,0) [0|1] "SED"  TCM,SOBDMC_HPCM,ECM,ECM_Diesel,ECM_HEV,ECM_HEVDSL,PCM,PCM_HEV,TCM_DSL,GWM
 SG_ PrplWhlTot_Tq_RqMx : 7|16@0+ (4,-131072) [-131072|131068] "Nm"  TCM,SOBDMC_HPCM,ECM,ECM_Diesel,ECM_HEV,ECM_HEVDSL,PCM,PCM_HEV,TCM_DSL,TCCM,GWM,AWD_DLCM
 SG_ LscmbbBaSensInc_B_Actl : 21|1@0+ (1,0) [0|1] "SED"  GWM
 SG_ CmbbBrkDis_B_Actl : 56|1@0+ (1,0) [0|1] "SED"  TCM,IPMA_ADAS,PSCM,ECM,ECM_Diesel,ECM_HEV,ECM_HEVDSL,TCM_DSL,GWM
 SG_ CmbbDeny_B_ActlBrk : 60|1@0+ (1,0) [0|1] "SED"  TCM,SOBDMC_HPCM,IPMA_ADAS,PSCM,ECM,ECM_Diesel,ECM_HEV,ECM_HEVDSL,GENERIC,PCM,PCM_HEV,TCM_DSL,GWM
 SG_ CcDis_B_Cmd : 47|1@0+ (1,0) [0|1] "SED"  TCM,ECM,ECM_Diesel,ECM_HEV,ECM_HEVDSL,PCM,PCM_HEV,TCM_DSL,GWM
 SG_ VehLongOvrGnd_A_Est : 41|10@0+ (0.035,-17.9) [-17.9|17.835] "m/s^2"  IPMA_ADAS,ECM,ECM_Diesel,ECM_HEV,ECM_HEVDSL,TCCM,GWM,SOBDMC_HPCM,VDM
 SG_ LscmbBrkPrchg_B_Actl : 16|1@0+ (1,0) [0|1] "SED"  GWM
 SG_ AccStopActv_B_ActlBrk : 22|1@0+ (1,0) [0|1] "SED"  TCM,IPMA_ADAS,ECM,ECM_Diesel,ECM_HEV,ECM_HEVDSL,PCM,PCM_HEV,TCM_DSL,GWM
 SG_ AccDis_B_ActlEpb : 32|1@0+ (1,0) [0|1] "SED"  TCM,IPMA_ADAS,ECM,ECM_Diesel,ECM_HEV,ECM_HEVDSL,TCM_DSL,GWM
 SG_ PrkBrkStatus : 26|3@0+ (1,0) [0|7] "SED"  TCM,SOBDMC_HPCM,IPMA_ADAS,ECM,ECM_Diesel,ECM_HEV,ECM_HEVDSL,PCM,PCM_HEV,TCM_DSL,GWM,AWD_DLCM
 SG_ PrkBrkYwLamp_D_Rq : 38|2@0+ (1,0) [0|3] "SED"  GWM,TCM_DSL,TCM,ECM_HEVDSL,ECM_HEV,ECM_Diesel,ECM
 SG_ PrkBrkRedLamp_D_Rq : 30|2@0+ (1,0) [0|3] "SED"  ECM,ECM_Diesel,ECM_HEV,ECM_HEVDSL,TCM,TCM_DSL,GWM

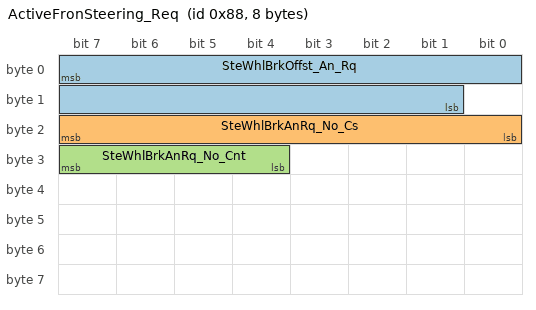
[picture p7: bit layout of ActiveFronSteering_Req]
BO_ 136 ActiveFronSteering_Req: 8 ABS_ESC
 SG_ SteWhlBrkOffst_An_Rq : 7|15@0+ (0.1,-1600) [-1600|1676.5] "degrees"  GWM
 SG_ SteWhlBrkAnRq_No_Cs : 23|8@0+ (1,0) [0|255] "Unitless"  GWM
 SG_ SteWhlBrkAnRq_No_Cnt : 31|4@0+ (1,0) [0|15] "Unitless"  GWM

BO_TX_BU_ 611 : AWD_DLCM,TCCM,SOBDMC_HPCM,ECM_HEV,ECM_Diesel,ECM,PCM;
BO_TX_BU_ 972 : GWM,PSCM;
BO_TX_BU_ 126 : GWM,PSCM;
CM_ BO_ 611 "Used on Applications with 4x4 supplied by Motorola.";
CM_ SG_ 611 AwdStat_D_RqDsply "Signal not transmitted on programs that do not have AWD.";
CM_ SG_ 611 AwdSrvcRqd_B_Rq "Signal not transmitted on programs that do not have AWD.";
CM_ SG_ 611 AwdLck_Tq_Rq "Signal not transmitted on programs that do not have AWD.";
CM_ BO_ 130 "drecker 10/23/09 Need SAPP in sync w/Strg Torque for proper PAM interpretation, else fault msg's displayed FP@20ms IPC needs EPAS_Failure for msg to driver.  Not map w/Lane Assist FP@30s FP), save bandwidth if feature not on vehicle ";
CM_ SG_ 130 VehVTrlrAid_B_Rq "VR session start- req. limit blower speed no more than X volts.  CC restriction on time msg. will be honored.Double Event msg1st event to request limit, 2nd event to release limit, No msg. CC Grammar v7.xls";
CM_ SG_ 130 SteMdule_U_Meas "DCR 1745  to update Tx from GWM to EP100ms. SteMdule_I_Est & SteMdule_U_Meas are used by BMS system & filtered. The filter uses standard periodic rate & changing to EP would adversely affect the filter.(jweinfur)";
CM_ SG_ 130 SteMdule_I_Est "DCR 1745  to update Tx from GWM to EP100ms. SteMdule_I_Est & SteMdule_U_Meas are used by BMS system & filtered. The filter uses standard periodic rate & changing to EP would adversely affect the filter.(jweinfur)";
CM_ SG_ 126 StePinRelInit_An_Sns "SASM will transmit these signals on vehicles with SASM and without PSCM.  SCCM will not Tx this signal when SASM is present.";
CM_ SG_ 126 StePinAn_No_Cs "Signal not transmitted on gas variants.";
CM_ SG_ 1200 BrkTot_Tq_RqDrv "DCR 1836 to update Tx from GWM to EP100ms rejected due MPS6 TCM requires BrkTot_Tq_RqDrv at 20ms (bshu1).";
CM_ SG_ 1046 TCMode "Signal data set to 0x0 for ABS only vehicle option content";
CM_ SG_ 1046 DrvAntiLckLamp_D_Rq "update value table v8.34, not align w/GSDB, need etracker.  ABS & IPC implemented as updated.";
CM_ SG_ 1044 StePinOffst_An_Est "SASM will transmit these signals on vehicles with SASM and without PSCM.  SCCM will not Tx this signal when SASM is present.";
CM_ SG_ 1044 StePinOffst_No_Cs "Signal not transmitted on gas variants.";
CM_ SG_ 534 BrkObdData_No_Actl "Signal not transmitted on gas, diesel and HEV.  Only supported on PHEV.";
CM_ SG_ 534 BrkObdIndex_No_Actl "Signal not transmitted on gas, diesel and HEV.  Only supported on PHEV.";
CM_ SG_ 534 WhlRotatRr_No_Cnt "DCR 1833 to update Tx from GWM to EP100ms. Wheel Count signals are used by complex algorithm to determine Tire Pressure by Location & can't change from 20msec. (jweinfur)";
CM_ SG_ 534 WhlRotatRl_No_Cnt "DCR 1833 to update Tx from GWM to EP100ms. Wheel Count signals are used by complex algorithm to determine Tire Pressure by Location & can't change from 20msec. (jweinfur)";
CM_ SG_ 534 WhlRotatFr_No_Cnt "DCR 1833 to update Tx from GWM to EP100ms. Wheel Count signals are used by complex algorithm to determine Tire Pressure by Location & can't change from 20msec. (jweinfur)";
CM_ SG_ 534 WhlRotatFl_No_Cnt "DCR 1833 to update Tx from GWM to EP100ms. Wheel Count signals are used by complex algorithm to determine Tire Pressure by Location & can't change from 20msec. (jweinfur)";
CM_ BO_ 532 "IC is NOT to use data in this message for displays, Used data from 415 instead.";
CM_ BO_ 531 "When PBM is present use 0x41B for PrkMsgTxt_D_Rq, PrkBrkRedLamp_D_Rq, PrkBrkYwLamp_D_Rq source signals otherwise ABS will source from 0x213.";
BA_DEF_ BO_  "VFrameFormat" ENUM  "StandardCAN","ExtendedCAN","reserved","reserved","reserved","reserved","reserved","reserved","reserved","reserved","reserved","reserved","reserved","reserved","StandardCAN_FD","ExtendedCAN_FD";
BA_DEF_ SG_  "GenSigSendType" ENUM  "Cyclic","OnWrite","vector_leerstring","OnChange","vector_leerstring","IfActive","vector_leerstring","NoSigSendType";
BA_DEF_ SG_  "GenSigInactiveValue" INT 0 100000;
BA_DEF_ SG_  "WakeupSignal" ENUM  "No","Yes";
BA_DEF_ SG_  "UsedOnPgmDBC" ENUM  "No","Yes";
BA_DEF_ SG_  "GenSigStartValueInteger" INT 0 1000000000;
BA_DEF_ SG_  "ContentDependant" ENUM  "No","Yes";
BA_DEF_ SG_  "MetaData" ENUM  "No","Yes";
BA_DEF_ SG_  "GenSigStartValue" HEX 0 268435455;
BA_DEF_ SG_  "U_CX727_MY2021_Rx" ENUM  "No","Yes";
BA_DEF_ SG_  "U_P702_MY2021_Rx" ENUM  "No","Yes";
BA_DEF_ SG_  "U_T6_MCA_MY2020_Rx" ENUM  "No","Yes";
BA_DEF_ SG_  "ECGUsedRxSignal" ENUM  "No","Yes";
BA_DEF_ SG_  "U_CD542_MY2021_Rx" ENUM  "No","Yes";
BA_DEF_ SG_  "U_U55X_MY2022_Rx" ENUM  "No","Yes";
BA_DEF_ SG_  "U_CD764_MY2022_Rx" ENUM  "No","Yes";
BA_DEF_ SG_  "U_CDX706_MY2023_Rx" ENUM  "No","Yes";
BA_DEF_ SG_  "U_CX727_MY2021_Tx" ENUM  "No","Yes";
BA_DEF_ SG_  "U_P702_MY2021_Tx" ENUM  "No","Yes";
BA_DEF_ SG_  "U_T6_MCA_MY2020_Tx" ENUM  "No","Yes";
BA_DEF_ SG_  "ECGUsedTxSignal" ENUM  "No","Yes";
BA_DEF_ SG_  "U_CD542_MY2021_Tx" ENUM  "No","Yes";
BA_DEF_ SG_  "U_U55X_MY2022_Tx" ENUM  "No","Yes";
BA_DEF_ SG_  "U_CD764_MY2022_Tx" ENUM  "No","Yes";
BA_DEF_ SG_  "U_CDX706_MY2023_Tx" ENUM  "No","Yes";
BA_DEF_ BO_  "GenMsgILSupport" ENUM  "No","Yes";
BA_DEF_ BO_  "DiagResponse" ENUM  "No","Yes";
BA_DEF_ BO_  "DiagRequest" ENUM  "No","Yes";
BA_DEF_ BO_  "TpTxIndex" INT 0 536870911;
BA_DEF_ BO_  "DiagState" ENUM  "No","Yes";
BA_DEF_ BO_  "TpApplType" STRING ;
BA_DEF_ BO_  "NmAsrMessage" ENUM  "No","Yes";
BA_DEF_ BO_  "ProgBWConditional" STRING ;
BA_DEF_ BO_  "SCP_AuthInfoTxLength" INT 0 512;
BA_DEF_ BO_  "SCP_FreshnessValueTxLength" INT 0 512;
BA_DEF_ BO_  "SCP_FreshnessValueLength" INT 0 512;
BA_DEF_ BO_  "OvtpPushApplication" ENUM  "FALSE","TRUE";
BA_DEF_ BO_  "GenMsgSendType" ENUM  "FixedPeriodic","Event","EnabledPeriodic","NotUsed","NotUsed","EventPeriodic","NotUsed","NotUsed","NoMsgSendType";
BA_DEF_ BO_  "GenMsgCycleTime" INT 0 100000;
BA_DEF_ BO_  "GenMsgDelayTime" INT 0 1000;
BA_DEF_ BO_  "GenMsgNrOfRepetition" INT 0 100;
BA_DEF_ BO_  "GenMsgStartDelayTime" INT 0 10000;
BA_DEF_ BO_  "EventRateOfChange" INT 10 10000;
BA_DEF_ BO_  "FrameGatewayId" HEX 0 1407;
BA_DEF_ BO_  "NetworkInitialization" ENUM  "No","Yes";
BA_DEF_ BO_  "FrameGatewayNetwork" STRING ;
BA_DEF_ BO_  "FrameRouting" STRING ;
BA_DEF_DEF_  "VFrameFormat" "ExtendedCAN_FD";
BA_DEF_DEF_  "GenSigSendType" "NoSigSendType";
BA_DEF_DEF_  "GenSigInactiveValue" 0;
BA_DEF_DEF_  "WakeupSignal" "No";
BA_DEF_DEF_  "UsedOnPgmDBC" "Yes";
BA_DEF_DEF_  "GenSigStartValueInteger" 0;
BA_DEF_DEF_  "ContentDependant" "No";
BA_DEF_DEF_  "MetaData" "No";
BA_DEF_DEF_  "GenSigStartValue" 0;
BA_DEF_DEF_  "U_CX727_MY2021_Rx" "No";
BA_DEF_DEF_  "U_P702_MY2021_Rx" "No";
BA_DEF_DEF_  "U_T6_MCA_MY2020_Rx" "No";
BA_DEF_DEF_  "ECGUsedRxSignal" "No";
BA_DEF_DEF_  "U_CD542_MY2021_Rx" "No";
BA_DEF_DEF_  "U_U55X_MY2022_Rx" "No";
BA_DEF_DEF_  "U_CD764_MY2022_Rx" "No";
BA_DEF_DEF_  "U_CDX706_MY2023_Rx" "No";
BA_DEF_DEF_  "U_CX727_MY2021_Tx" "No";
BA_DEF_DEF_  "U_P702_MY2021_Tx" "No";
BA_DEF_DEF_  "U_T6_MCA_MY2020_Tx" "No";
BA_DEF_DEF_  "ECGUsedTxSignal" "No";
BA_DEF_DEF_  "U_CD542_MY2021_Tx" "No";
BA_DEF_DEF_  "U_U55X_MY2022_Tx" "No";
BA_DEF_DEF_  "U_CD764_MY2022_Tx" "No";
BA_DEF_DEF_  "U_CDX706_MY2023_Tx" "No";
BA_DEF_DEF_  "GenMsgILSupport" "Yes";
BA_DEF_DEF_  "DiagResponse" "No";
BA_DEF_DEF_  "DiagRequest" "No";
BA_DEF_DEF_  "TpTxIndex" 0;
BA_DEF_DEF_  "DiagState" "No";
BA_DEF_DEF_  "TpApplType" "";
BA_DEF_DEF_  "NmAsrMessage" "No";
BA_DEF_DEF_  "ProgBWConditional" "NONE";
BA_DEF_DEF_  "SCP_AuthInfoTxLength" 53;
BA_DEF_DEF_  "SCP_FreshnessValueTxLength" 11;
BA_DEF_DEF_  "SCP_FreshnessValueLength" 64;
BA_DEF_DEF_  "OvtpPushApplication" "FALSE";
BA_DEF_DEF_  "GenMsgSendType" "NoMsgSendType";
BA_DEF_DEF_  "GenMsgCycleTime" 0;
BA_DEF_DEF_  "GenMsgDelayTime" 20;
BA_DEF_DEF_  "GenMsgNrOfRepetition" 1;
BA_DEF_DEF_  "GenMsgStartDelayTime" 0;
BA_DEF_DEF_  "EventRateOfChange" 10000;
BA_DEF_DEF_  "FrameGatewayId" 0;
BA_DEF_DEF_  "NetworkInitialization" "Yes";
BA_DEF_DEF_  "FrameGatewayNetwork" "NONE";
BA_DEF_DEF_  "FrameRouting" "";
BA_ "GenMsgSendType" BO_ 1264 0;
BA_ "GenMsgCycleTime" BO_ 1264 200;
BA_ "GenMsgSendType" BO_ 611 0;
BA_ "GenMsgCycleTime" BO_ 611 100;
BA_ "VFrameFormat" BO_ 611 14;
BA_ "GenMsgILSupport" BO_ 1461 0;
BA_ "NmAsrMessage" BO_ 1461 1;
BA_ "GenMsgSendType" BO_ 1461 0;
BA_ "GenMsgCycleTime" BO_ 1461 1000;
BA_ "NetworkInitialization" BO_ 1461 0;
BA_ "VFrameFormat" BO_ 1461 14;
BA_ "GenMsgSendType" BO_ 1047 5;
BA_ "GenMsgCycleTime" BO_ 1047 1000;
BA_ "VFrameFormat" BO_ 1047 14;
BA_ "GenMsgSendType" BO_ 972 0;
BA_ "GenMsgCycleTime" BO_ 972 30;
BA_ "GenMsgDelayTime" BO_ 972 10;
BA_ "VFrameFormat" BO_ 972 14;
BA_ "GenMsgSendType" BO_ 130 0;
BA_ "GenMsgCycleTime" BO_ 130 20;
BA_ "GenMsgDelayTime" BO_ 130 10;
BA_ "VFrameFormat" BO_ 130 14;
BA_ "GenMsgSendType" BO_ 126 0;
BA_ "GenMsgCycleTime" BO_ 126 10;
BA_ "GenMsgDelayTime" BO_ 126 0;
BA_ "VFrameFormat" BO_ 126 14;
BA_ "GenMsgILSupport" BO_ 1430 0;
BA_ "NmAsrMessage" BO_ 1430 1;
BA_ "GenMsgSendType" BO_ 1430 0;
BA_ "GenMsgCycleTime" BO_ 1430 1000;
BA_ "NetworkInitialization" BO_ 1430 0;
BA_ "VFrameFormat" BO_ 1430 14;
BA_ "GenMsgSendType" BO_ 1200 0;
BA_ "GenMsgCycleTime" BO_ 1200 20;
BA_ "GenMsgDelayTime" BO_ 1200 10;
BA_ "VFrameFormat" BO_ 1200 14;
BA_ "GenMsgSendType" BO_ 1102 5;
BA_ "GenMsgCycleTime" BO_ 1102 100000;
BA_ "GenMsgStartDelayTime" BO_ 1102 1130;
BA_ "VFrameFormat" BO_ 1102 14;
BA_ "GenMsgSendType" BO_ 1056 5;
BA_ "GenMsgCycleTime" BO_ 1056 1000;
BA_ "VFrameFormat" BO_ 1056 14;
BA_ "GenMsgSendType" BO_ 1054 5;
BA_ "GenMsgCycleTime" BO_ 1054 1000;
BA_ "VFrameFormat" BO_ 1054 14;
BA_ "GenMsgSendType" BO_ 1046 0;
BA_ "GenMsgCycleTime" BO_ 1046 100;
BA_ "VFrameFormat" BO_ 1046 14;
BA_ "GenMsgSendType" BO_ 1045 0;
BA_ "GenMsgCycleTime" BO_ 1045 20;
BA_ "GenMsgDelayTime" BO_ 1045 10;
BA_ "VFrameFormat" BO_ 1045 14;
BA_ "GenMsgSendType" BO_ 1044 0;
BA_ "GenMsgCycleTime" BO_ 1044 100;
BA_ "VFrameFormat" BO_ 1044 14;
BA_ "GenMsgSendType" BO_ 1042 0;
BA_ "GenMsgCycleTime" BO_ 1042 50;
BA_ "VFrameFormat" BO_ 1042 14;
BA_ "GenMsgSendType" BO_ 535 0;
BA_ "GenMsgCycleTime" BO_ 535 10;
BA_ "GenMsgDelayTime" BO_ 535 0;
BA_ "VFrameFormat" BO_ 535 14;
BA_ "GenMsgSendType" BO_ 534 0;
BA_ "GenMsgCycleTime" BO_ 534 20;
BA_ "GenMsgDelayTime" BO_ 534 10;
BA_ "VFrameFormat" BO_ 534 14;
BA_ "GenMsgSendType" BO_ 532 0;
BA_ "GenMsgCycleTime" BO_ 532 20;
BA_ "GenMsgDelayTime" BO_ 532 10;
BA_ "VFrameFormat" BO_ 532 14;
BA_ "FrameGatewayId" BO_ 1264 1264;
BA_ "FrameGatewayNetwork" BO_ 1264 "HS1_CAN";
BA_ "FrameRouting" BO_ 1264 "HS1_CAN,0x4F0;";
BA_ "VFrameFormat" BO_ 1264 14;
BA_ "GenMsgSendType" BO_ 531 0;
BA_ "GenMsgCycleTime" BO_ 531 20;
BA_ "GenMsgDelayTime" BO_ 531 10;
BA_ "VFrameFormat" BO_ 531 14;
BA_ "GenMsgSendType" BO_ 136 0;
BA_ "GenMsgCycleTime" BO_ 136 10;
BA_ "GenMsgDelayTime" BO_ 136 0;
BA_ "VFrameFormat" BO_ 136 14;
BA_ "U_T6_MCA_MY2020_Tx" SG_ 611 AwdTerrMdeChng_D_Rdy 1;
BA_ "U_T6_MCA_MY2020_Tx" SG_ 611 AwdTerrMde_D_Actl 1;
BA_ "U_P702_MY2021_Rx" SG_ 611 AwdSys_D_Stat 1;
BA_ "U_T6_MCA_MY2020_Rx" SG_ 611 AwdSys_D_Stat 1;
BA_ "U_U55X_MY2022_Rx" SG_ 611 AwdSys_D_Stat 1;
BA_ "U_CDX706_MY2023_Rx" SG_ 611 AwdSys_D_Stat 1;
BA_ "U_P702_MY2021_Tx" SG_ 611 AwdSys_D_Stat 1;
BA_ "U_T6_MCA_MY2020_Tx" SG_ 611 AwdSys_D_Stat 1;
BA_ "U_U55X_MY2022_Tx" SG_ 611 AwdSys_D_Stat 1;
BA_ "U_T6_MCA_MY2020_Rx" SG_ 611 SelDrvMdeAwd_D_Stat 1;
BA_ "U_P702_MY2021_Tx" SG_ 611 SelDrvMdeAwd_D_Stat 1;
BA_ "U_T6_MCA_MY2020_Tx" SG_ 611 SelDrvMdeAwd_D_Stat 1;
BA_ "ContentDependant" SG_ 611 AwdStat_D_RqDsply 1;
BA_ "U_P702_MY2021_Rx" SG_ 611 AwdStat_D_RqDsply 1;
BA_ "U_T6_MCA_MY2020_Rx" SG_ 611 AwdStat_D_RqDsply 1;
BA_ "U_U55X_MY2022_Rx" SG_ 611 AwdStat_D_RqDsply 1;
BA_ "U_CDX706_MY2023_Rx" SG_ 611 AwdStat_D_RqDsply 1;
BA_ "U_CX727_MY2021_Tx" SG_ 611 AwdStat_D_RqDsply 1;
BA_ "U_P702_MY2021_Tx" SG_ 611 AwdStat_D_RqDsply 1;
BA_ "U_T6_MCA_MY2020_Tx" SG_ 611 AwdStat_D_RqDsply 1;
BA_ "U_U55X_MY2022_Tx" SG_ 611 AwdStat_D_RqDsply 1;
BA_ "U_CX727_MY2021_Rx" SG_ 611 AwdLck_D_Stat 1;
BA_ "U_P702_MY2021_Rx" SG_ 611 AwdLck_D_Stat 1;
BA_ "U_T6_MCA_MY2020_Rx" SG_ 611 AwdLck_D_Stat 1;
BA_ "U_CD542_MY2021_Rx" SG_ 611 AwdLck_D_Stat 1;
BA_ "U_U55X_MY2022_Rx" SG_ 611 AwdLck_D_Stat 1;
BA_ "U_CD764_MY2022_Rx" SG_ 611 AwdLck_D_Stat 1;
BA_ "U_CDX706_MY2023_Rx" SG_ 611 AwdLck_D_Stat 1;
BA_ "U_CX727_MY2021_Tx" SG_ 611 AwdLck_D_Stat 1;
BA_ "U_P702_MY2021_Tx" SG_ 611 AwdLck_D_Stat 1;
BA_ "U_T6_MCA_MY2020_Tx" SG_ 611 AwdLck_D_Stat 1;
BA_ "U_U55X_MY2022_Tx" SG_ 611 AwdLck_D_Stat 1;
BA_ "ContentDependant" SG_ 611 AwdSrvcRqd_B_Rq 1;
BA_ "U_P702_MY2021_Rx" SG_ 611 AwdSrvcRqd_B_Rq 1;
BA_ "U_T6_MCA_MY2020_Rx" SG_ 611 AwdSrvcRqd_B_Rq 1;
BA_ "U_U55X_MY2022_Rx" SG_ 611 AwdSrvcRqd_B_Rq 1;
BA_ "U_CDX706_MY2023_Rx" SG_ 611 AwdSrvcRqd_B_Rq 1;
BA_ "U_CX727_MY2021_Tx" SG_ 611 AwdSrvcRqd_B_Rq 1;
BA_ "U_P702_MY2021_Tx" SG_ 611 AwdSrvcRqd_B_Rq 1;
BA_ "U_T6_MCA_MY2020_Tx" SG_ 611 AwdSrvcRqd_B_Rq 1;
BA_ "U_U55X_MY2022_Tx" SG_ 611 AwdSrvcRqd_B_Rq 1;
BA_ "U_P702_MY2021_Tx" SG_ 611 NtrlTowAvail_B_Stat 1;
BA_ "U_T6_MCA_MY2020_Tx" SG_ 611 NtrlTowAvail_B_Stat 1;
BA_ "U_U55X_MY2022_Tx" SG_ 611 NtrlTowAvail_B_Stat 1;
BA_ "ContentDependant" SG_ 611 AwdLck_Tq_Rq 1;
BA_ "U_P702_MY2021_Rx" SG_ 611 AwdLck_Tq_Rq 1;
BA_ "U_T6_MCA_MY2020_Rx" SG_ 611 AwdLck_Tq_Rq 1;
BA_ "U_U55X_MY2022_Rx" SG_ 611 AwdLck_Tq_Rq 1;
BA_ "U_CDX706_MY2023_Rx" SG_ 611 AwdLck_Tq_Rq 1;
BA_ "U_CX727_MY2021_Tx" SG_ 611 AwdLck_Tq_Rq 1;
BA_ "U_P702_MY2021_Tx" SG_ 611 AwdLck_Tq_Rq 1;
BA_ "U_T6_MCA_MY2020_Tx" SG_ 611 AwdLck_Tq_Rq 1;
BA_ "U_U55X_MY2022_Tx" SG_ 611 AwdLck_Tq_Rq 1;
BA_ "GenSigStartValueInteger" SG_ 611 TrnAout_Tq_RqMx 8191;
BA_ "GenSigStartValue" SG_ 611 TrnAout_Tq_RqMx 8191;
BA_ "U_P702_MY2021_Rx" SG_ 611 TrnAout_Tq_RqMx 1;
BA_ "U_T6_MCA_MY2020_Rx" SG_ 611 TrnAout_Tq_RqMx 1;
BA_ "U_U55X_MY2022_Rx" SG_ 611 TrnAout_Tq_RqMx 1;
BA_ "U_CDX706_MY2023_Rx" SG_ 611 TrnAout_Tq_RqMx 1;
BA_ "U_P702_MY2021_Tx" SG_ 611 TrnAout_Tq_RqMx 1;
BA_ "U_U55X_MY2022_Tx" SG_ 611 TrnAout_Tq_RqMx 1;
BA_ "U_T6_MCA_MY2020_Rx" SG_ 611 AwdOffRoadMode_D_Stats 1;
BA_ "U_CD542_MY2021_Rx" SG_ 611 AwdOffRoadMode_D_Stats 1;
BA_ "U_U55X_MY2022_Rx" SG_ 611 AwdOffRoadMode_D_Stats 1;
BA_ "U_CD764_MY2022_Rx" SG_ 611 AwdOffRoadMode_D_Stats 1;
BA_ "U_CDX706_MY2023_Rx" SG_ 611 AwdOffRoadMode_D_Stats 1;
BA_ "U_P702_MY2021_Tx" SG_ 611 AwdOffRoadMode_D_Stats 1;
BA_ "U_T6_MCA_MY2020_Tx" SG_ 611 AwdOffRoadMode_D_Stats 1;
BA_ "U_U55X_MY2022_Tx" SG_ 611 AwdOffRoadMode_D_Stats 1;
BA_ "U_P702_MY2021_Tx" SG_ 611 AwdLoLamp_D_RqDsply 1;
BA_ "U_T6_MCA_MY2020_Tx" SG_ 611 AwdLoLamp_D_RqDsply 1;
BA_ "U_U55X_MY2022_Tx" SG_ 611 AwdLoLamp_D_RqDsply 1;
BA_ "U_P702_MY2021_Rx" SG_ 611 AwdHiLamp_D_RqDsply 1;
BA_ "U_T6_MCA_MY2020_Rx" SG_ 611 AwdHiLamp_D_RqDsply 1;
BA_ "U_U55X_MY2022_Rx" SG_ 611 AwdHiLamp_D_RqDsply 1;
BA_ "U_CDX706_MY2023_Rx" SG_ 611 AwdHiLamp_D_RqDsply 1;
BA_ "U_P702_MY2021_Tx" SG_ 611 AwdHiLamp_D_RqDsply 1;
BA_ "U_T6_MCA_MY2020_Tx" SG_ 611 AwdHiLamp_D_RqDsply 1;
BA_ "U_U55X_MY2022_Tx" SG_ 611 AwdHiLamp_D_RqDsply 1;
BA_ "U_P702_MY2021_Rx" SG_ 611 AwdAutoLamp_D_RqDsply 1;
BA_ "U_T6_MCA_MY2020_Rx" SG_ 611 AwdAutoLamp_D_RqDsply 1;
BA_ "U_U55X_MY2022_Rx" SG_ 611 AwdAutoLamp_D_RqDsply 1;
BA_ "U_CDX706_MY2023_Rx" SG_ 611 AwdAutoLamp_D_RqDsply 1;
BA_ "U_P702_MY2021_Tx" SG_ 611 AwdAutoLamp_D_RqDsply 1;
BA_ "U_T6_MCA_MY2020_Tx" SG_ 611 AwdAutoLamp_D_RqDsply 1;
BA_ "U_U55X_MY2022_Tx" SG_ 611 AwdAutoLamp_D_RqDsply 1;
BA_ "U_P702_MY2021_Tx" SG_ 611 Awd2wdLamp_D_RqDsply 1;
BA_ "U_T6_MCA_MY2020_Tx" SG_ 611 Awd2wdLamp_D_RqDsply 1;
BA_ "U_U55X_MY2022_Tx" SG_ 611 Awd2wdLamp_D_RqDsply 1;
BA_ "GenSigStartValueInteger" SG_ 611 AwdRnge_D_Actl 7;
BA_ "GenSigStartValue" SG_ 611 AwdRnge_D_Actl 7;
BA_ "U_P702_MY2021_Rx" SG_ 611 AwdRnge_D_Actl 1;
BA_ "U_T6_MCA_MY2020_Rx" SG_ 611 AwdRnge_D_Actl 1;
BA_ "ECGUsedRxSignal" SG_ 611 AwdRnge_D_Actl 1;
BA_ "U_CD542_MY2021_Rx" SG_ 611 AwdRnge_D_Actl 1;
BA_ "U_U55X_MY2022_Rx" SG_ 611 AwdRnge_D_Actl 1;
BA_ "U_CD764_MY2022_Rx" SG_ 611 AwdRnge_D_Actl 1;
BA_ "U_CDX706_MY2023_Rx" SG_ 611 AwdRnge_D_Actl 1;
BA_ "U_P702_MY2021_Tx" SG_ 611 AwdRnge_D_Actl 1;
BA_ "U_T6_MCA_MY2020_Tx" SG_ 611 AwdRnge_D_Actl 1;
BA_ "U_U55X_MY2022_Tx" SG_ 611 AwdRnge_D_Actl 1;
BA_ "GenSigStartValueInteger" SG_ 1461 PSCM_GWOnBoardTester 255;
BA_ "ContentDependant" SG_ 1461 PSCM_GWOnBoardTester 1;
BA_ "GenSigStartValue" SG_ 1461 PSCM_GWOnBoardTester 255;
BA_ "U_P702_MY2021_Rx" SG_ 1461 PSCM_GWOnBoardTester 1;
BA_ "U_T6_MCA_MY2020_Rx" SG_ 1461 PSCM_GWOnBoardTester 1;
BA_ "U_CD542_MY2021_Rx" SG_ 1461 PSCM_GWOnBoardTester 1;
BA_ "U_U55X_MY2022_Rx" SG_ 1461 PSCM_GWOnBoardTester 1;
BA_ "U_CD764_MY2022_Rx" SG_ 1461 PSCM_GWOnBoardTester 1;
BA_ "U_CDX706_MY2023_Rx" SG_ 1461 PSCM_GWOnBoardTester 1;
BA_ "U_CX727_MY2021_Tx" SG_ 1461 PSCM_GWOnBoardTester 1;
BA_ "U_P702_MY2021_Tx" SG_ 1461 PSCM_GWOnBoardTester 1;
BA_ "U_T6_MCA_MY2020_Tx" SG_ 1461 PSCM_GWOnBoardTester 1;
BA_ "U_CD542_MY2021_Tx" SG_ 1461 PSCM_GWOnBoardTester 1;
BA_ "U_U55X_MY2022_Tx" SG_ 1461 PSCM_GWOnBoardTester 1;
BA_ "U_CD764_MY2022_Tx" SG_ 1461 PSCM_GWOnBoardTester 1;
BA_ "U_CDX706_MY2023_Tx" SG_ 1461 PSCM_GWOnBoardTester 1;
BA_ "GenSigStartValueInteger" SG_ 1461 PSCM_GWNMProxy 255;
BA_ "ContentDependant" SG_ 1461 PSCM_GWNMProxy 1;
BA_ "GenSigStartValue" SG_ 1461 PSCM_GWNMProxy 255;
BA_ "U_P702_MY2021_Rx" SG_ 1461 PSCM_GWNMProxy 1;
BA_ "U_T6_MCA_MY2020_Rx" SG_ 1461 PSCM_GWNMProxy 1;
BA_ "U_CD542_MY2021_Rx" SG_ 1461 PSCM_GWNMProxy 1;
BA_ "U_U55X_MY2022_Rx" SG_ 1461 PSCM_GWNMProxy 1;
BA_ "U_CD764_MY2022_Rx" SG_ 1461 PSCM_GWNMProxy 1;
BA_ "U_CDX706_MY2023_Rx" SG_ 1461 PSCM_GWNMProxy 1;
BA_ "U_CX727_MY2021_Tx" SG_ 1461 PSCM_GWNMProxy 1;
BA_ "U_P702_MY2021_Tx" SG_ 1461 PSCM_GWNMProxy 1;
BA_ "U_T6_MCA_MY2020_Tx" SG_ 1461 PSCM_GWNMProxy 1;
BA_ "U_CD542_MY2021_Tx" SG_ 1461 PSCM_GWNMProxy 1;
BA_ "U_U55X_MY2022_Tx" SG_ 1461 PSCM_GWNMProxy 1;
BA_ "U_CD764_MY2022_Tx" SG_ 1461 PSCM_GWNMProxy 1;
BA_ "U_CDX706_MY2023_Tx" SG_ 1461 PSCM_GWNMProxy 1;
BA_ "GenSigStartValueInteger" SG_ 1461 PSCM_AutoSarNMReserved4 255;
BA_ "ContentDependant" SG_ 1461 PSCM_AutoSarNMReserved4 1;
BA_ "GenSigStartValue" SG_ 1461 PSCM_AutoSarNMReserved4 255;
BA_ "U_P702_MY2021_Rx" SG_ 1461 PSCM_AutoSarNMReserved4 1;
BA_ "U_T6_MCA_MY2020_Rx" SG_ 1461 PSCM_AutoSarNMReserved4 1;
BA_ "U_CD542_MY2021_Rx" SG_ 1461 PSCM_AutoSarNMReserved4 1;
BA_ "U_U55X_MY2022_Rx" SG_ 1461 PSCM_AutoSarNMReserved4 1;
BA_ "U_CD764_MY2022_Rx" SG_ 1461 PSCM_AutoSarNMReserved4 1;
BA_ "U_CDX706_MY2023_Rx" SG_ 1461 PSCM_AutoSarNMReserved4 1;
BA_ "U_CX727_MY2021_Tx" SG_ 1461 PSCM_AutoSarNMReserved4 1;
BA_ "U_P702_MY2021_Tx" SG_ 1461 PSCM_AutoSarNMReserved4 1;
BA_ "U_T6_MCA_MY2020_Tx" SG_ 1461 PSCM_AutoSarNMReserved4 1;
BA_ "U_CD542_MY2021_Tx" SG_ 1461 PSCM_AutoSarNMReserved4 1;
BA_ "U_U55X_MY2022_Tx" SG_ 1461 PSCM_AutoSarNMReserved4 1;
BA_ "U_CD764_MY2022_Tx" SG_ 1461 PSCM_AutoSarNMReserved4 1;
BA_ "U_CDX706_MY2023_Tx" SG_ 1461 PSCM_AutoSarNMReserved4 1;
BA_ "GenSigStartValueInteger" SG_ 1461 PSCM_AutoSarNMReserved3 255;
BA_ "ContentDependant" SG_ 1461 PSCM_AutoSarNMReserved3 1;
BA_ "GenSigStartValue" SG_ 1461 PSCM_AutoSarNMReserved3 255;
BA_ "U_P702_MY2021_Rx" SG_ 1461 PSCM_AutoSarNMReserved3 1;
BA_ "U_T6_MCA_MY2020_Rx" SG_ 1461 PSCM_AutoSarNMReserved3 1;
BA_ "U_CD542_MY2021_Rx" SG_ 1461 PSCM_AutoSarNMReserved3 1;
BA_ "U_U55X_MY2022_Rx" SG_ 1461 PSCM_AutoSarNMReserved3 1;
BA_ "U_CD764_MY2022_Rx" SG_ 1461 PSCM_AutoSarNMReserved3 1;
BA_ "U_CDX706_MY2023_Rx" SG_ 1461 PSCM_AutoSarNMReserved3 1;
BA_ "U_CX727_MY2021_Tx" SG_ 1461 PSCM_AutoSarNMReserved3 1;
BA_ "U_P702_MY2021_Tx" SG_ 1461 PSCM_AutoSarNMReserved3 1;
BA_ "U_T6_MCA_MY2020_Tx" SG_ 1461 PSCM_AutoSarNMReserved3 1;
BA_ "U_CD542_MY2021_Tx" SG_ 1461 PSCM_AutoSarNMReserved3 1;
BA_ "U_U55X_MY2022_Tx" SG_ 1461 PSCM_AutoSarNMReserved3 1;
BA_ "U_CD764_MY2022_Tx" SG_ 1461 PSCM_AutoSarNMReserved3 1;
BA_ "U_CDX706_MY2023_Tx" SG_ 1461 PSCM_AutoSarNMReserved3 1;
BA_ "GenSigStartValueInteger" SG_ 1461 PSCM_AutoSarNMReserved2 255;
BA_ "ContentDependant" SG_ 1461 PSCM_AutoSarNMReserved2 1;
BA_ "GenSigStartValue" SG_ 1461 PSCM_AutoSarNMReserved2 255;
BA_ "U_T6_MCA_MY2020_Rx" SG_ 1461 PSCM_AutoSarNMReserved2 1;
BA_ "U_CD542_MY2021_Rx" SG_ 1461 PSCM_AutoSarNMReserved2 1;
BA_ "U_U55X_MY2022_Rx" SG_ 1461 PSCM_AutoSarNMReserved2 1;
BA_ "U_CD764_MY2022_Rx" SG_ 1461 PSCM_AutoSarNMReserved2 1;
BA_ "U_CDX706_MY2023_Rx" SG_ 1461 PSCM_AutoSarNMReserved2 1;
BA_ "U_CX727_MY2021_Tx" SG_ 1461 PSCM_AutoSarNMReserved2 1;
BA_ "U_P702_MY2021_Tx" SG_ 1461 PSCM_AutoSarNMReserved2 1;
BA_ "U_T6_MCA_MY2020_Tx" SG_ 1461 PSCM_AutoSarNMReserved2 1;
BA_ "U_CD542_MY2021_Tx" SG_ 1461 PSCM_AutoSarNMReserved2 1;
BA_ "U_U55X_MY2022_Tx" SG_ 1461 PSCM_AutoSarNMReserved2 1;
BA_ "U_CD764_MY2022_Tx" SG_ 1461 PSCM_AutoSarNMReserved2 1;
BA_ "U_CDX706_MY2023_Tx" SG_ 1461 PSCM_AutoSarNMReserved2 1;
BA_ "GenSigStartValueInteger" SG_ 1461 PSCM_AutoSarNMReserved1 255;
BA_ "ContentDependant" SG_ 1461 PSCM_AutoSarNMReserved1 1;
BA_ "GenSigStartValue" SG_ 1461 PSCM_AutoSarNMReserved1 255;
BA_ "U_T6_MCA_MY2020_Rx" SG_ 1461 PSCM_AutoSarNMReserved1 1;
BA_ "U_CD542_MY2021_Rx" SG_ 1461 PSCM_AutoSarNMReserved1 1;
BA_ "U_U55X_MY2022_Rx" SG_ 1461 PSCM_AutoSarNMReserved1 1;
BA_ "U_CD764_MY2022_Rx" SG_ 1461 PSCM_AutoSarNMReserved1 1;
BA_ "U_CDX706_MY2023_Rx" SG_ 1461 PSCM_AutoSarNMReserved1 1;
BA_ "U_CX727_MY2021_Tx" SG_ 1461 PSCM_AutoSarNMReserved1 1;
BA_ "U_P702_MY2021_Tx" SG_ 1461 PSCM_AutoSarNMReserved1 1;
BA_ "U_T6_MCA_MY2020_Tx" SG_ 1461 PSCM_AutoSarNMReserved1 1;
BA_ "U_CD542_MY2021_Tx" SG_ 1461 PSCM_AutoSarNMReserved1 1;
BA_ "U_U55X_MY2022_Tx" SG_ 1461 PSCM_AutoSarNMReserved1 1;
BA_ "U_CD764_MY2022_Tx" SG_ 1461 PSCM_AutoSarNMReserved1 1;
BA_ "U_CDX706_MY2023_Tx" SG_ 1461 PSCM_AutoSarNMReserved1 1;
BA_ "GenSigStartValueInteger" SG_ 1461 PSCM_AutoSarNMNodeId 181;
BA_ "ContentDependant" SG_ 1461 PSCM_AutoSarNMNodeId 1;
BA_ "GenSigStartValue" SG_ 1461 PSCM_AutoSarNMNodeId 181;
BA_ "U_T6_MCA_MY2020_Rx" SG_ 1461 PSCM_AutoSarNMNodeId 1;
BA_ "U_CD542_MY2021_Rx" SG_ 1461 PSCM_AutoSarNMNodeId 1;
BA_ "U_U55X_MY2022_Rx" SG_ 1461 PSCM_AutoSarNMNodeId 1;
BA_ "U_CD764_MY2022_Rx" SG_ 1461 PSCM_AutoSarNMNodeId 1;
BA_ "U_CDX706_MY2023_Rx" SG_ 1461 PSCM_AutoSarNMNodeId 1;
BA_ "U_CX727_MY2021_Tx" SG_ 1461 PSCM_AutoSarNMNodeId 1;
BA_ "U_P702_MY2021_Tx" SG_ 1461 PSCM_AutoSarNMNodeId 1;
BA_ "U_T6_MCA_MY2020_Tx" SG_ 1461 PSCM_AutoSarNMNodeId 1;
BA_ "U_CD542_MY2021_Tx" SG_ 1461 PSCM_AutoSarNMNodeId 1;
BA_ "U_U55X_MY2022_Tx" SG_ 1461 PSCM_AutoSarNMNodeId 1;
BA_ "U_CD764_MY2022_Tx" SG_ 1461 PSCM_AutoSarNMNodeId 1;
BA_ "U_CDX706_MY2023_Tx" SG_ 1461 PSCM_AutoSarNMNodeId 1;
BA_ "ContentDependant" SG_ 1461 PSCM_AutoSarNMControl 1;
BA_ "U_T6_MCA_MY2020_Rx" SG_ 1461 PSCM_AutoSarNMControl 1;
BA_ "U_CD542_MY2021_Rx" SG_ 1461 PSCM_AutoSarNMControl 1;
BA_ "U_U55X_MY2022_Rx" SG_ 1461 PSCM_AutoSarNMControl 1;
BA_ "U_CD764_MY2022_Rx" SG_ 1461 PSCM_AutoSarNMControl 1;
BA_ "U_CDX706_MY2023_Rx" SG_ 1461 PSCM_AutoSarNMControl 1;
BA_ "U_CX727_MY2021_Tx" SG_ 1461 PSCM_AutoSarNMControl 1;
BA_ "U_P702_MY2021_Tx" SG_ 1461 PSCM_AutoSarNMControl 1;
BA_ "U_T6_MCA_MY2020_Tx" SG_ 1461 PSCM_AutoSarNMControl 1;
BA_ "U_CD542_MY2021_Tx" SG_ 1461 PSCM_AutoSarNMControl 1;
BA_ "U_U55X_MY2022_Tx" SG_ 1461 PSCM_AutoSarNMControl 1;
BA_ "U_CD764_MY2022_Tx" SG_ 1461 PSCM_AutoSarNMControl 1;
BA_ "U_CDX706_MY2023_Tx" SG_ 1461 PSCM_AutoSarNMControl 1;
BA_ "GenSigStartValueInteger" SG_ 1047 TrlrAnOffst_An2_Calc 128;
BA_ "U_T6_MCA_MY2020_Rx" SG_ 1047 TrlrAnOffst_An2_Calc 1;
BA_ "U_CD542_MY2021_Rx" SG_ 1047 TrlrAnOffst_An2_Calc 1;
BA_ "U_U55X_MY2022_Rx" SG_ 1047 TrlrAnOffst_An2_Calc 1;
BA_ "U_CD764_MY2022_Rx" SG_ 1047 TrlrAnOffst_An2_Calc 1;
BA_ "U_CDX706_MY2023_Rx" SG_ 1047 TrlrAnOffst_An2_Calc 1;
BA_ "U_P702_MY2021_Tx" SG_ 1047 TrlrAnOffst_An2_Calc 1;
BA_ "U_T6_MCA_MY2020_Tx" SG_ 1047 TrlrAnOffst_An2_Calc 1;
BA_ "U_T6_MCA_MY2020_Rx" SG_ 1047 TrlrAn_An_WarnCalc 1;
BA_ "U_CD542_MY2021_Rx" SG_ 1047 TrlrAn_An_WarnCalc 1;
BA_ "U_U55X_MY2022_Rx" SG_ 1047 TrlrAn_An_WarnCalc 1;
BA_ "U_CD764_MY2022_Rx" SG_ 1047 TrlrAn_An_WarnCalc 1;
BA_ "U_CDX706_MY2023_Rx" SG_ 1047 TrlrAn_An_WarnCalc 1;
BA_ "U_P702_MY2021_Tx" SG_ 1047 TrlrAn_An_WarnCalc 1;
BA_ "U_T6_MCA_MY2020_Tx" SG_ 1047 TrlrAn_An_WarnCalc 1;
BA_ "U_T6_MCA_MY2020_Rx" SG_ 1047 TrlrAn_An_MxCalc 1;
BA_ "U_CD542_MY2021_Rx" SG_ 1047 TrlrAn_An_MxCalc 1;
BA_ "U_U55X_MY2022_Rx" SG_ 1047 TrlrAn_An_MxCalc 1;
BA_ "U_CD764_MY2022_Rx" SG_ 1047 TrlrAn_An_MxCalc 1;
BA_ "U_CDX706_MY2023_Rx" SG_ 1047 TrlrAn_An_MxCalc 1;
BA_ "U_P702_MY2021_Tx" SG_ 1047 TrlrAn_An_MxCalc 1;
BA_ "U_T6_MCA_MY2020_Tx" SG_ 1047 TrlrAn_An_MxCalc 1;
BA_ "U_P702_MY2021_Tx" SG_ 1047 TrlrAidTrlrId_No_Rq 1;
BA_ "U_T6_MCA_MY2020_Tx" SG_ 1047 TrlrAidTrlrId_No_Rq 1;
BA_ "U_T6_MCA_MY2020_Rx" SG_ 1047 TrlrAidTrgtId_No_Rq 1;
BA_ "U_CD542_MY2021_Rx" SG_ 1047 TrlrAidTrgtId_No_Rq 1;
BA_ "U_U55X_MY2022_Rx" SG_ 1047 TrlrAidTrgtId_No_Rq 1;
BA_ "U_CD764_MY2022_Rx" SG_ 1047 TrlrAidTrgtId_No_Rq 1;
BA_ "U_CDX706_MY2023_Rx" SG_ 1047 TrlrAidTrgtId_No_Rq 1;
BA_ "U_P702_MY2021_Tx" SG_ 1047 TrlrAidTrgtId_No_Rq 1;
BA_ "U_T6_MCA_MY2020_Tx" SG_ 1047 TrlrAidTrgtId_No_Rq 1;
BA_ "U_T6_MCA_MY2020_Rx" SG_ 1047 TrlrAidSetup_D2_Stat 1;
BA_ "U_CD542_MY2021_Rx" SG_ 1047 TrlrAidSetup_D2_Stat 1;
BA_ "U_U55X_MY2022_Rx" SG_ 1047 TrlrAidSetup_D2_Stat 1;
BA_ "U_CD764_MY2022_Rx" SG_ 1047 TrlrAidSetup_D2_Stat 1;
BA_ "U_CDX706_MY2023_Rx" SG_ 1047 TrlrAidSetup_D2_Stat 1;
BA_ "U_P702_MY2021_Tx" SG_ 1047 TrlrAidSetup_D2_Stat 1;
BA_ "U_T6_MCA_MY2020_Tx" SG_ 1047 TrlrAidSetup_D2_Stat 1;
BA_ "GenSigSendType" SG_ 1047 TrlrAidEnbl_D2_Stat 3;
BA_ "U_P702_MY2021_Rx" SG_ 1047 TrlrAidEnbl_D2_Stat 1;
BA_ "U_T6_MCA_MY2020_Rx" SG_ 1047 TrlrAidEnbl_D2_Stat 1;
BA_ "U_CD542_MY2021_Rx" SG_ 1047 TrlrAidEnbl_D2_Stat 1;
BA_ "U_U55X_MY2022_Rx" SG_ 1047 TrlrAidEnbl_D2_Stat 1;
BA_ "U_CD764_MY2022_Rx" SG_ 1047 TrlrAidEnbl_D2_Stat 1;
BA_ "U_CDX706_MY2023_Rx" SG_ 1047 TrlrAidEnbl_D2_Stat 1;
BA_ "U_P702_MY2021_Tx" SG_ 1047 TrlrAidEnbl_D2_Stat 1;
BA_ "U_T6_MCA_MY2020_Tx" SG_ 1047 TrlrAidEnbl_D2_Stat 1;
BA_ "GenSigSendType" SG_ 1047 TrlrAidMsgTxt_D2_Rq 3;
BA_ "U_P702_MY2021_Rx" SG_ 1047 TrlrAidMsgTxt_D2_Rq 1;
BA_ "U_T6_MCA_MY2020_Rx" SG_ 1047 TrlrAidMsgTxt_D2_Rq 1;
BA_ "U_CD542_MY2021_Rx" SG_ 1047 TrlrAidMsgTxt_D2_Rq 1;
BA_ "U_U55X_MY2022_Rx" SG_ 1047 TrlrAidMsgTxt_D2_Rq 1;
BA_ "U_CD764_MY2022_Rx" SG_ 1047 TrlrAidMsgTxt_D2_Rq 1;
BA_ "U_CDX706_MY2023_Rx" SG_ 1047 TrlrAidMsgTxt_D2_Rq 1;
BA_ "U_P702_MY2021_Tx" SG_ 1047 TrlrAidMsgTxt_D2_Rq 1;
BA_ "U_T6_MCA_MY2020_Tx" SG_ 1047 TrlrAidMsgTxt_D2_Rq 1;
BA_ "GenSigSendType" SG_ 1047 EsaOn_B_Stat 3;
BA_ "GenSigStartValueInteger" SG_ 1047 EsaOn_B_Stat 1;
BA_ "GenSigStartValue" SG_ 1047 EsaOn_B_Stat 1;
BA_ "U_CX727_MY2021_Tx" SG_ 1047 EsaOn_B_Stat 1;
BA_ "U_P702_MY2021_Tx" SG_ 1047 EsaOn_B_Stat 1;
BA_ "U_T6_MCA_MY2020_Tx" SG_ 1047 EsaOn_B_Stat 1;
BA_ "U_CD542_MY2021_Tx" SG_ 1047 EsaOn_B_Stat 1;
BA_ "U_CD764_MY2022_Tx" SG_ 1047 EsaOn_B_Stat 1;
BA_ "U_CDX706_MY2023_Tx" SG_ 1047 EsaOn_B_Stat 1;
BA_ "U_T6_MCA_MY2020_Rx" SG_ 1047 HitchToTrlrAxle_L_Calc 1;
BA_ "U_CD542_MY2021_Rx" SG_ 1047 HitchToTrlrAxle_L_Calc 1;
BA_ "U_U55X_MY2022_Rx" SG_ 1047 HitchToTrlrAxle_L_Calc 1;
BA_ "U_CD764_MY2022_Rx" SG_ 1047 HitchToTrlrAxle_L_Calc 1;
BA_ "U_CDX706_MY2023_Rx" SG_ 1047 HitchToTrlrAxle_L_Calc 1;
BA_ "U_P702_MY2021_Tx" SG_ 1047 HitchToTrlrAxle_L_Calc 1;
BA_ "U_T6_MCA_MY2020_Tx" SG_ 1047 HitchToTrlrAxle_L_Calc 1;
BA_ "GenSigSendType" SG_ 1047 SelDrvMdeSte_D_Stat 3;
BA_ "U_CX727_MY2021_Rx" SG_ 1047 SelDrvMdeSte_D_Stat 1;
BA_ "U_P702_MY2021_Rx" SG_ 1047 SelDrvMdeSte_D_Stat 1;
BA_ "U_T6_MCA_MY2020_Rx" SG_ 1047 SelDrvMdeSte_D_Stat 1;
BA_ "U_CD542_MY2021_Rx" SG_ 1047 SelDrvMdeSte_D_Stat 1;
BA_ "U_U55X_MY2022_Rx" SG_ 1047 SelDrvMdeSte_D_Stat 1;
BA_ "U_CD764_MY2022_Rx" SG_ 1047 SelDrvMdeSte_D_Stat 1;
BA_ "U_CDX706_MY2023_Rx" SG_ 1047 SelDrvMdeSte_D_Stat 1;
BA_ "U_CX727_MY2021_Tx" SG_ 1047 SelDrvMdeSte_D_Stat 1;
BA_ "U_P702_MY2021_Tx" SG_ 1047 SelDrvMdeSte_D_Stat 1;
BA_ "U_T6_MCA_MY2020_Tx" SG_ 1047 SelDrvMdeSte_D_Stat 1;
BA_ "U_CD542_MY2021_Tx" SG_ 1047 SelDrvMdeSte_D_Stat 1;
BA_ "U_CD764_MY2022_Tx" SG_ 1047 SelDrvMdeSte_D_Stat 1;
BA_ "U_CDX706_MY2023_Tx" SG_ 1047 SelDrvMdeSte_D_Stat 1;
BA_ "GenSigStartValueInteger" SG_ 972 TrlrAn_An_TrgtCalc 128;
BA_ "U_T6_MCA_MY2020_Rx" SG_ 972 TrlrAn_An_TrgtCalc 1;
BA_ "U_CD542_MY2021_Rx" SG_ 972 TrlrAn_An_TrgtCalc 1;
BA_ "U_U55X_MY2022_Rx" SG_ 972 TrlrAn_An_TrgtCalc 1;
BA_ "U_CD764_MY2022_Rx" SG_ 972 TrlrAn_An_TrgtCalc 1;
BA_ "U_CDX706_MY2023_Rx" SG_ 972 TrlrAn_An_TrgtCalc 1;
BA_ "U_P702_MY2021_Tx" SG_ 972 TrlrAn_An_TrgtCalc 1;
BA_ "U_T6_MCA_MY2020_Tx" SG_ 972 TrlrAn_An_TrgtCalc 1;
BA_ "U_U55X_MY2022_Tx" SG_ 972 TrlrAn_An_TrgtCalc 1;
BA_ "U_P702_MY2021_Rx" SG_ 972 LsmcBrkDecelEnbl_D_Rq 1;
BA_ "U_T6_MCA_MY2020_Rx" SG_ 972 LsmcBrkDecelEnbl_D_Rq 1;
BA_ "U_U55X_MY2022_Rx" SG_ 972 LsmcBrkDecelEnbl_D_Rq 1;
BA_ "U_P702_MY2021_Tx" SG_ 972 LsmcBrkDecelEnbl_D_Rq 1;
BA_ "U_T6_MCA_MY2020_Tx" SG_ 972 LsmcBrkDecelEnbl_D_Rq 1;
BA_ "U_U55X_MY2022_Tx" SG_ 972 LsmcBrkDecelEnbl_D_Rq 1;
BA_ "GenSigStartValueInteger" SG_ 972 TjaHandsOnCnfdnc_B_Est 1;
BA_ "GenSigStartValue" SG_ 972 TjaHandsOnCnfdnc_B_Est 1;
BA_ "U_T6_MCA_MY2020_Rx" SG_ 972 TjaHandsOnCnfdnc_B_Est 1;
BA_ "U_CD542_MY2021_Rx" SG_ 972 TjaHandsOnCnfdnc_B_Est 1;
BA_ "U_U55X_MY2022_Rx" SG_ 972 TjaHandsOnCnfdnc_B_Est 1;
BA_ "U_CD764_MY2022_Rx" SG_ 972 TjaHandsOnCnfdnc_B_Est 1;
BA_ "U_CDX706_MY2023_Rx" SG_ 972 TjaHandsOnCnfdnc_B_Est 1;
BA_ "U_CX727_MY2021_Tx" SG_ 972 TjaHandsOnCnfdnc_B_Est 1;
BA_ "U_P702_MY2021_Tx" SG_ 972 TjaHandsOnCnfdnc_B_Est 1;
BA_ "U_T6_MCA_MY2020_Tx" SG_ 972 TjaHandsOnCnfdnc_B_Est 1;
BA_ "U_CD542_MY2021_Tx" SG_ 972 TjaHandsOnCnfdnc_B_Est 1;
BA_ "U_U55X_MY2022_Tx" SG_ 972 TjaHandsOnCnfdnc_B_Est 1;
BA_ "U_CD764_MY2022_Tx" SG_ 972 TjaHandsOnCnfdnc_B_Est 1;
BA_ "U_CDX706_MY2023_Tx" SG_ 972 TjaHandsOnCnfdnc_B_Est 1;
BA_ "GenSigStartValueInteger" SG_ 972 LaHandsOff_B_Actl 1;
BA_ "GenSigStartValue" SG_ 972 LaHandsOff_B_Actl 1;
BA_ "U_T6_MCA_MY2020_Rx" SG_ 972 LaHandsOff_B_Actl 1;
BA_ "U_CD542_MY2021_Rx" SG_ 972 LaHandsOff_B_Actl 1;
BA_ "U_U55X_MY2022_Rx" SG_ 972 LaHandsOff_B_Actl 1;
BA_ "U_CD764_MY2022_Rx" SG_ 972 LaHandsOff_B_Actl 1;
BA_ "U_CDX706_MY2023_Rx" SG_ 972 LaHandsOff_B_Actl 1;
BA_ "U_CX727_MY2021_Tx" SG_ 972 LaHandsOff_B_Actl 1;
BA_ "U_P702_MY2021_Tx" SG_ 972 LaHandsOff_B_Actl 1;
BA_ "U_T6_MCA_MY2020_Tx" SG_ 972 LaHandsOff_B_Actl 1;
BA_ "U_CD542_MY2021_Tx" SG_ 972 LaHandsOff_B_Actl 1;
BA_ "U_U55X_MY2022_Tx" SG_ 972 LaHandsOff_B_Actl 1;
BA_ "U_CD764_MY2022_Tx" SG_ 972 LaHandsOff_B_Actl 1;
BA_ "U_CDX706_MY2023_Tx" SG_ 972 LaHandsOff_B_Actl 1;
BA_ "U_T6_MCA_MY2020_Rx" SG_ 972 LaActDeny_B_Actl 1;
BA_ "U_CD542_MY2021_Rx" SG_ 972 LaActDeny_B_Actl 1;
BA_ "U_U55X_MY2022_Rx" SG_ 972 LaActDeny_B_Actl 1;
BA_ "U_CD764_MY2022_Rx" SG_ 972 LaActDeny_B_Actl 1;
BA_ "U_CDX706_MY2023_Rx" SG_ 972 LaActDeny_B_Actl 1;
BA_ "U_CX727_MY2021_Tx" SG_ 972 LaActDeny_B_Actl 1;
BA_ "U_P702_MY2021_Tx" SG_ 972 LaActDeny_B_Actl 1;
BA_ "U_T6_MCA_MY2020_Tx" SG_ 972 LaActDeny_B_Actl 1;
BA_ "U_CD542_MY2021_Tx" SG_ 972 LaActDeny_B_Actl 1;
BA_ "U_U55X_MY2022_Tx" SG_ 972 LaActDeny_B_Actl 1;
BA_ "U_CD764_MY2022_Tx" SG_ 972 LaActDeny_B_Actl 1;
BA_ "U_CDX706_MY2023_Tx" SG_ 972 LaActDeny_B_Actl 1;
BA_ "U_P702_MY2021_Rx" SG_ 972 LsmcBrk_Tq_Rq 1;
BA_ "U_T6_MCA_MY2020_Rx" SG_ 972 LsmcBrk_Tq_Rq 1;
BA_ "U_U55X_MY2022_Rx" SG_ 972 LsmcBrk_Tq_Rq 1;
BA_ "U_P702_MY2021_Tx" SG_ 972 LsmcBrk_Tq_Rq 1;
BA_ "U_T6_MCA_MY2020_Tx" SG_ 972 LsmcBrk_Tq_Rq 1;
BA_ "U_U55X_MY2022_Tx" SG_ 972 LsmcBrk_Tq_Rq 1;
BA_ "U_T6_MCA_MY2020_Rx" SG_ 972 LatCtlSte_D_Stat 1;
BA_ "U_CD542_MY2021_Rx" SG_ 972 LatCtlSte_D_Stat 1;
BA_ "U_U55X_MY2022_Rx" SG_ 972 LatCtlSte_D_Stat 1;
BA_ "U_CD764_MY2022_Rx" SG_ 972 LatCtlSte_D_Stat 1;
BA_ "U_CDX706_MY2023_Rx" SG_ 972 LatCtlSte_D_Stat 1;
BA_ "U_T6_MCA_MY2020_Tx" SG_ 972 LatCtlSte_D_Stat 1;
BA_ "U_CD542_MY2021_Tx" SG_ 972 LatCtlSte_D_Stat 1;
BA_ "U_U55X_MY2022_Tx" SG_ 972 LatCtlSte_D_Stat 1;
BA_ "U_CD764_MY2022_Tx" SG_ 972 LatCtlSte_D_Stat 1;
BA_ "U_CDX706_MY2023_Tx" SG_ 972 LatCtlSte_D_Stat 1;
BA_ "U_T6_MCA_MY2020_Rx" SG_ 972 LatCtlLim_D_Stat 1;
BA_ "U_CD542_MY2021_Rx" SG_ 972 LatCtlLim_D_Stat 1;
BA_ "U_U55X_MY2022_Rx" SG_ 972 LatCtlLim_D_Stat 1;
BA_ "U_CD764_MY2022_Rx" SG_ 972 LatCtlLim_D_Stat 1;
BA_ "U_CDX706_MY2023_Rx" SG_ 972 LatCtlLim_D_Stat 1;
BA_ "U_T6_MCA_MY2020_Tx" SG_ 972 LatCtlLim_D_Stat 1;
BA_ "U_CD542_MY2021_Tx" SG_ 972 LatCtlLim_D_Stat 1;
BA_ "U_U55X_MY2022_Tx" SG_ 972 LatCtlLim_D_Stat 1;
BA_ "U_CD764_MY2022_Tx" SG_ 972 LatCtlLim_D_Stat 1;
BA_ "U_CDX706_MY2023_Tx" SG_ 972 LatCtlLim_D_Stat 1;
BA_ "MetaData" SG_ 972 LatCtlCpbltyDStat_No_Cs 1;
BA_ "U_T6_MCA_MY2020_Rx" SG_ 972 LatCtlCpbltyDStat_No_Cs 1;
BA_ "U_CD542_MY2021_Rx" SG_ 972 LatCtlCpbltyDStat_No_Cs 1;
BA_ "U_U55X_MY2022_Rx" SG_ 972 LatCtlCpbltyDStat_No_Cs 1;
BA_ "U_CD764_MY2022_Rx" SG_ 972 LatCtlCpbltyDStat_No_Cs 1;
BA_ "U_CDX706_MY2023_Rx" SG_ 972 LatCtlCpbltyDStat_No_Cs 1;
BA_ "U_T6_MCA_MY2020_Tx" SG_ 972 LatCtlCpbltyDStat_No_Cs 1;
BA_ "U_U55X_MY2022_Tx" SG_ 972 LatCtlCpbltyDStat_No_Cs 1;
BA_ "U_CD764_MY2022_Tx" SG_ 972 LatCtlCpbltyDStat_No_Cs 1;
BA_ "U_CDX706_MY2023_Tx" SG_ 972 LatCtlCpbltyDStat_No_Cs 1;
BA_ "MetaData" SG_ 972 LatCtlCpbltyDStat_No_Cnt 1;
BA_ "U_T6_MCA_MY2020_Rx" SG_ 972 LatCtlCpbltyDStat_No_Cnt 1;
BA_ "U_CD542_MY2021_Rx" SG_ 972 LatCtlCpbltyDStat_No_Cnt 1;
BA_ "U_U55X_MY2022_Rx" SG_ 972 LatCtlCpbltyDStat_No_Cnt 1;
BA_ "U_CD764_MY2022_Rx" SG_ 972 LatCtlCpbltyDStat_No_Cnt 1;
BA_ "U_CDX706_MY2023_Rx" SG_ 972 LatCtlCpbltyDStat_No_Cnt 1;
BA_ "U_T6_MCA_MY2020_Tx" SG_ 972 LatCtlCpbltyDStat_No_Cnt 1;
BA_ "U_U55X_MY2022_Tx" SG_ 972 LatCtlCpbltyDStat_No_Cnt 1;
BA_ "U_CD764_MY2022_Tx" SG_ 972 LatCtlCpbltyDStat_No_Cnt 1;
BA_ "U_CDX706_MY2023_Tx" SG_ 972 LatCtlCpbltyDStat_No_Cnt 1;
BA_ "U_T6_MCA_MY2020_Rx" SG_ 972 LatCtlCpblty_D_Stat 1;
BA_ "U_CD542_MY2021_Rx" SG_ 972 LatCtlCpblty_D_Stat 1;
BA_ "U_U55X_MY2022_Rx" SG_ 972 LatCtlCpblty_D_Stat 1;
BA_ "U_CD764_MY2022_Rx" SG_ 972 LatCtlCpblty_D_Stat 1;
BA_ "U_CDX706_MY2023_Rx" SG_ 972 LatCtlCpblty_D_Stat 1;
BA_ "U_T6_MCA_MY2020_Tx" SG_ 972 LatCtlCpblty_D_Stat 1;
BA_ "U_U55X_MY2022_Tx" SG_ 972 LatCtlCpblty_D_Stat 1;
BA_ "U_CD764_MY2022_Tx" SG_ 972 LatCtlCpblty_D_Stat 1;
BA_ "U_CDX706_MY2023_Tx" SG_ 972 LatCtlCpblty_D_Stat 1;
BA_ "U_CDX706_MY2023_Rx" SG_ 972 LaActAvail_D2_Actl 1;
BA_ "U_CDX706_MY2023_Tx" SG_ 972 LaActAvail_D2_Actl 1;
BA_ "U_T6_MCA_MY2020_Rx" SG_ 130 TrlrHitchLamp_D_Rqst 1;
BA_ "U_CD542_MY2021_Rx" SG_ 130 TrlrHitchLamp_D_Rqst 1;
BA_ "U_U55X_MY2022_Rx" SG_ 130 TrlrHitchLamp_D_Rqst 1;
BA_ "U_CD764_MY2022_Rx" SG_ 130 TrlrHitchLamp_D_Rqst 1;
BA_ "U_CDX706_MY2023_Rx" SG_ 130 TrlrHitchLamp_D_Rqst 1;
BA_ "U_P702_MY2021_Tx" SG_ 130 TrlrHitchLamp_D_Rqst 1;
BA_ "U_T6_MCA_MY2020_Tx" SG_ 130 TrlrHitchLamp_D_Rqst 1;
BA_ "U_U55X_MY2022_Tx" SG_ 130 TrlrHitchLamp_D_Rqst 1;
BA_ "U_P702_MY2021_Rx" SG_ 130 VehVTrlrAid_B_Rq 1;
BA_ "U_T6_MCA_MY2020_Rx" SG_ 130 VehVTrlrAid_B_Rq 1;
BA_ "U_U55X_MY2022_Rx" SG_ 130 VehVTrlrAid_B_Rq 1;
BA_ "U_P702_MY2021_Tx" SG_ 130 VehVTrlrAid_B_Rq 1;
BA_ "U_T6_MCA_MY2020_Tx" SG_ 130 VehVTrlrAid_B_Rq 1;
BA_ "U_U55X_MY2022_Tx" SG_ 130 VehVTrlrAid_B_Rq 1;
BA_ "U_U55X_MY2022_Tx" SG_ 130 SteEffort_D_Stat 1;
BA_ "GenSigStartValueInteger" SG_ 130 Veh_V_RqMxTrlrAid 255;
BA_ "GenSigStartValue" SG_ 130 Veh_V_RqMxTrlrAid 255;
BA_ "U_P702_MY2021_Rx" SG_ 130 Veh_V_RqMxTrlrAid 1;
BA_ "U_T6_MCA_MY2020_Rx" SG_ 130 Veh_V_RqMxTrlrAid 1;
BA_ "U_U55X_MY2022_Rx" SG_ 130 Veh_V_RqMxTrlrAid 1;
BA_ "U_P702_MY2021_Tx" SG_ 130 Veh_V_RqMxTrlrAid 1;
BA_ "U_T6_MCA_MY2020_Tx" SG_ 130 Veh_V_RqMxTrlrAid 1;
BA_ "U_U55X_MY2022_Tx" SG_ 130 Veh_V_RqMxTrlrAid 1;
BA_ "U_P702_MY2021_Rx" SG_ 130 DrvSteActv_B_Stat 1;
BA_ "U_T6_MCA_MY2020_Rx" SG_ 130 DrvSteActv_B_Stat 1;
BA_ "U_U55X_MY2022_Rx" SG_ 130 DrvSteActv_B_Stat 1;
BA_ "U_CDX706_MY2023_Rx" SG_ 130 DrvSteActv_B_Stat 1;
BA_ "U_P702_MY2021_Tx" SG_ 130 DrvSteActv_B_Stat 1;
BA_ "U_T6_MCA_MY2020_Tx" SG_ 130 DrvSteActv_B_Stat 1;
BA_ "U_U55X_MY2022_Tx" SG_ 130 DrvSteActv_B_Stat 1;
BA_ "GenSigStartValueInteger" SG_ 130 DrvSte_Tq_Actl 128;
BA_ "U_P702_MY2021_Rx" SG_ 130 DrvSte_Tq_Actl 1;
BA_ "U_T6_MCA_MY2020_Rx" SG_ 130 DrvSte_Tq_Actl 1;
BA_ "U_U55X_MY2022_Rx" SG_ 130 DrvSte_Tq_Actl 1;
BA_ "U_CDX706_MY2023_Rx" SG_ 130 DrvSte_Tq_Actl 1;
BA_ "U_P702_MY2021_Tx" SG_ 130 DrvSte_Tq_Actl 1;
BA_ "U_T6_MCA_MY2020_Tx" SG_ 130 DrvSte_Tq_Actl 1;
BA_ "U_U55X_MY2022_Tx" SG_ 130 DrvSte_Tq_Actl 1;
BA_ "U_CX727_MY2021_Tx" SG_ 130 SteMdule_D_Stat 1;
BA_ "U_P702_MY2021_Tx" SG_ 130 SteMdule_D_Stat 1;
BA_ "U_T6_MCA_MY2020_Tx" SG_ 130 SteMdule_D_Stat 1;
BA_ "U_CD542_MY2021_Tx" SG_ 130 SteMdule_D_Stat 1;
BA_ "U_U55X_MY2022_Tx" SG_ 130 SteMdule_D_Stat 1;
BA_ "U_CD764_MY2022_Tx" SG_ 130 SteMdule_D_Stat 1;
BA_ "U_CDX706_MY2023_Tx" SG_ 130 SteMdule_D_Stat 1;
BA_ "GenSigStartValueInteger" SG_ 130 SteMdule_U_Meas 255;
BA_ "GenSigStartValue" SG_ 130 SteMdule_U_Meas 255;
BA_ "U_CX727_MY2021_Tx" SG_ 130 SteMdule_U_Meas 1;
BA_ "U_P702_MY2021_Tx" SG_ 130 SteMdule_U_Meas 1;
BA_ "U_T6_MCA_MY2020_Tx" SG_ 130 SteMdule_U_Meas 1;
BA_ "U_CD542_MY2021_Tx" SG_ 130 SteMdule_U_Meas 1;
BA_ "U_U55X_MY2022_Tx" SG_ 130 SteMdule_U_Meas 1;
BA_ "U_CD764_MY2022_Tx" SG_ 130 SteMdule_U_Meas 1;
BA_ "U_CDX706_MY2023_Tx" SG_ 130 SteMdule_U_Meas 1;
BA_ "GenSigStartValueInteger" SG_ 130 SteMdule_I_Est 4095;
BA_ "GenSigStartValue" SG_ 130 SteMdule_I_Est 4095;
BA_ "U_CX727_MY2021_Tx" SG_ 130 SteMdule_I_Est 1;
BA_ "U_P702_MY2021_Tx" SG_ 130 SteMdule_I_Est 1;
BA_ "U_T6_MCA_MY2020_Tx" SG_ 130 SteMdule_I_Est 1;
BA_ "U_CD542_MY2021_Tx" SG_ 130 SteMdule_I_Est 1;
BA_ "U_U55X_MY2022_Tx" SG_ 130 SteMdule_I_Est 1;
BA_ "U_CD764_MY2022_Tx" SG_ 130 SteMdule_I_Est 1;
BA_ "U_CDX706_MY2023_Tx" SG_ 130 SteMdule_I_Est 1;
BA_ "U_T6_MCA_MY2020_Rx" SG_ 130 EPAS_Failure 1;
BA_ "U_CD542_MY2021_Rx" SG_ 130 EPAS_Failure 1;
BA_ "U_U55X_MY2022_Rx" SG_ 130 EPAS_Failure 1;
BA_ "U_CD764_MY2022_Rx" SG_ 130 EPAS_Failure 1;
BA_ "U_CDX706_MY2023_Rx" SG_ 130 EPAS_Failure 1;
BA_ "U_CX727_MY2021_Tx" SG_ 130 EPAS_Failure 1;
BA_ "U_P702_MY2021_Tx" SG_ 130 EPAS_Failure 1;
BA_ "U_T6_MCA_MY2020_Tx" SG_ 130 EPAS_Failure 1;
BA_ "U_CD542_MY2021_Tx" SG_ 130 EPAS_Failure 1;
BA_ "U_U55X_MY2022_Tx" SG_ 130 EPAS_Failure 1;
BA_ "U_CD764_MY2022_Tx" SG_ 130 EPAS_Failure 1;
BA_ "U_CDX706_MY2023_Tx" SG_ 130 EPAS_Failure 1;
BA_ "GenSigStartValueInteger" SG_ 130 SteeringColumnTorque 254;
BA_ "GenSigStartValue" SG_ 130 SteeringColumnTorque 254;
BA_ "U_CX727_MY2021_Rx" SG_ 130 SteeringColumnTorque 1;
BA_ "U_P702_MY2021_Rx" SG_ 130 SteeringColumnTorque 1;
BA_ "U_T6_MCA_MY2020_Rx" SG_ 130 SteeringColumnTorque 1;
BA_ "U_CD542_MY2021_Rx" SG_ 130 SteeringColumnTorque 1;
BA_ "U_U55X_MY2022_Rx" SG_ 130 SteeringColumnTorque 1;
BA_ "U_CD764_MY2022_Rx" SG_ 130 SteeringColumnTorque 1;
BA_ "U_CDX706_MY2023_Rx" SG_ 130 SteeringColumnTorque 1;
BA_ "U_CX727_MY2021_Tx" SG_ 130 SteeringColumnTorque 1;
BA_ "U_P702_MY2021_Tx" SG_ 130 SteeringColumnTorque 1;
BA_ "U_T6_MCA_MY2020_Tx" SG_ 130 SteeringColumnTorque 1;
BA_ "U_CD542_MY2021_Tx" SG_ 130 SteeringColumnTorque 1;
BA_ "U_U55X_MY2022_Tx" SG_ 130 SteeringColumnTorque 1;
BA_ "U_CD764_MY2022_Tx" SG_ 130 SteeringColumnTorque 1;
BA_ "U_CDX706_MY2023_Tx" SG_ 130 SteeringColumnTorque 1;
BA_ "U_T6_MCA_MY2020_Rx" SG_ 130 SAPPAngleControlStat6 1;
BA_ "U_CD542_MY2021_Rx" SG_ 130 SAPPAngleControlStat6 1;
BA_ "U_U55X_MY2022_Rx" SG_ 130 SAPPAngleControlStat6 1;
BA_ "U_CD764_MY2022_Rx" SG_ 130 SAPPAngleControlStat6 1;
BA_ "U_CDX706_MY2023_Rx" SG_ 130 SAPPAngleControlStat6 1;
BA_ "U_CX727_MY2021_Tx" SG_ 130 SAPPAngleControlStat6 1;
BA_ "U_P702_MY2021_Tx" SG_ 130 SAPPAngleControlStat6 1;
BA_ "U_T6_MCA_MY2020_Tx" SG_ 130 SAPPAngleControlStat6 1;
BA_ "U_CD542_MY2021_Tx" SG_ 130 SAPPAngleControlStat6 1;
BA_ "U_U55X_MY2022_Tx" SG_ 130 SAPPAngleControlStat6 1;
BA_ "U_CD764_MY2022_Tx" SG_ 130 SAPPAngleControlStat6 1;
BA_ "U_CDX706_MY2023_Tx" SG_ 130 SAPPAngleControlStat6 1;
BA_ "U_T6_MCA_MY2020_Rx" SG_ 130 SAPPAngleControlStat5 1;
BA_ "U_CD542_MY2021_Rx" SG_ 130 SAPPAngleControlStat5 1;
BA_ "U_U55X_MY2022_Rx" SG_ 130 SAPPAngleControlStat5 1;
BA_ "U_CD764_MY2022_Rx" SG_ 130 SAPPAngleControlStat5 1;
BA_ "U_CDX706_MY2023_Rx" SG_ 130 SAPPAngleControlStat5 1;
BA_ "U_CX727_MY2021_Tx" SG_ 130 SAPPAngleControlStat5 1;
BA_ "U_P702_MY2021_Tx" SG_ 130 SAPPAngleControlStat5 1;
BA_ "U_T6_MCA_MY2020_Tx" SG_ 130 SAPPAngleControlStat5 1;
BA_ "U_CD542_MY2021_Tx" SG_ 130 SAPPAngleControlStat5 1;
BA_ "U_U55X_MY2022_Tx" SG_ 130 SAPPAngleControlStat5 1;
BA_ "U_CD764_MY2022_Tx" SG_ 130 SAPPAngleControlStat5 1;
BA_ "U_CDX706_MY2023_Tx" SG_ 130 SAPPAngleControlStat5 1;
BA_ "U_T6_MCA_MY2020_Rx" SG_ 130 SAPPAngleControlStat4 1;
BA_ "U_CD542_MY2021_Rx" SG_ 130 SAPPAngleControlStat4 1;
BA_ "U_U55X_MY2022_Rx" SG_ 130 SAPPAngleControlStat4 1;
BA_ "U_CD764_MY2022_Rx" SG_ 130 SAPPAngleControlStat4 1;
BA_ "U_CDX706_MY2023_Rx" SG_ 130 SAPPAngleControlStat4 1;
BA_ "U_CX727_MY2021_Tx" SG_ 130 SAPPAngleControlStat4 1;
BA_ "U_P702_MY2021_Tx" SG_ 130 SAPPAngleControlStat4 1;
BA_ "U_T6_MCA_MY2020_Tx" SG_ 130 SAPPAngleControlStat4 1;
BA_ "U_CD542_MY2021_Tx" SG_ 130 SAPPAngleControlStat4 1;
BA_ "U_U55X_MY2022_Tx" SG_ 130 SAPPAngleControlStat4 1;
BA_ "U_CD764_MY2022_Tx" SG_ 130 SAPPAngleControlStat4 1;
BA_ "U_CDX706_MY2023_Tx" SG_ 130 SAPPAngleControlStat4 1;
BA_ "U_T6_MCA_MY2020_Rx" SG_ 130 SAPPAngleControlStat3 1;
BA_ "U_CD542_MY2021_Rx" SG_ 130 SAPPAngleControlStat3 1;
BA_ "U_U55X_MY2022_Rx" SG_ 130 SAPPAngleControlStat3 1;
BA_ "U_CD764_MY2022_Rx" SG_ 130 SAPPAngleControlStat3 1;
BA_ "U_CDX706_MY2023_Rx" SG_ 130 SAPPAngleControlStat3 1;
BA_ "U_CX727_MY2021_Tx" SG_ 130 SAPPAngleControlStat3 1;
BA_ "U_P702_MY2021_Tx" SG_ 130 SAPPAngleControlStat3 1;
BA_ "U_T6_MCA_MY2020_Tx" SG_ 130 SAPPAngleControlStat3 1;
BA_ "U_CD542_MY2021_Tx" SG_ 130 SAPPAngleControlStat3 1;
BA_ "U_U55X_MY2022_Tx" SG_ 130 SAPPAngleControlStat3 1;
BA_ "U_CD764_MY2022_Tx" SG_ 130 SAPPAngleControlStat3 1;
BA_ "U_CDX706_MY2023_Tx" SG_ 130 SAPPAngleControlStat3 1;
BA_ "U_T6_MCA_MY2020_Rx" SG_ 130 SAPPAngleControlStat2 1;
BA_ "U_CD542_MY2021_Rx" SG_ 130 SAPPAngleControlStat2 1;
BA_ "U_U55X_MY2022_Rx" SG_ 130 SAPPAngleControlStat2 1;
BA_ "U_CD764_MY2022_Rx" SG_ 130 SAPPAngleControlStat2 1;
BA_ "U_CDX706_MY2023_Rx" SG_ 130 SAPPAngleControlStat2 1;
BA_ "U_CX727_MY2021_Tx" SG_ 130 SAPPAngleControlStat2 1;
BA_ "U_P702_MY2021_Tx" SG_ 130 SAPPAngleControlStat2 1;
BA_ "U_T6_MCA_MY2020_Tx" SG_ 130 SAPPAngleControlStat2 1;
BA_ "U_CD542_MY2021_Tx" SG_ 130 SAPPAngleControlStat2 1;
BA_ "U_U55X_MY2022_Tx" SG_ 130 SAPPAngleControlStat2 1;
BA_ "U_CD764_MY2022_Tx" SG_ 130 SAPPAngleControlStat2 1;
BA_ "U_CDX706_MY2023_Tx" SG_ 130 SAPPAngleControlStat2 1;
BA_ "U_T6_MCA_MY2020_Rx" SG_ 130 SAPPAngleControlStat1 1;
BA_ "U_CD542_MY2021_Rx" SG_ 130 SAPPAngleControlStat1 1;
BA_ "U_U55X_MY2022_Rx" SG_ 130 SAPPAngleControlStat1 1;
BA_ "U_CD764_MY2022_Rx" SG_ 130 SAPPAngleControlStat1 1;
BA_ "U_CDX706_MY2023_Rx" SG_ 130 SAPPAngleControlStat1 1;
BA_ "U_CX727_MY2021_Tx" SG_ 130 SAPPAngleControlStat1 1;
BA_ "U_P702_MY2021_Tx" SG_ 130 SAPPAngleControlStat1 1;
BA_ "U_T6_MCA_MY2020_Tx" SG_ 130 SAPPAngleControlStat1 1;
BA_ "U_CD542_MY2021_Tx" SG_ 130 SAPPAngleControlStat1 1;
BA_ "U_U55X_MY2022_Tx" SG_ 130 SAPPAngleControlStat1 1;
BA_ "U_CD764_MY2022_Tx" SG_ 130 SAPPAngleControlStat1 1;
BA_ "U_CDX706_MY2023_Tx" SG_ 130 SAPPAngleControlStat1 1;
BA_ "U_CX727_MY2021_Rx" SG_ 126 StePw_B_Rq 1;
BA_ "U_P702_MY2021_Rx" SG_ 126 StePw_B_Rq 1;
BA_ "U_T6_MCA_MY2020_Rx" SG_ 126 StePw_B_Rq 1;
BA_ "U_CD542_MY2021_Rx" SG_ 126 StePw_B_Rq 1;
BA_ "U_U55X_MY2022_Rx" SG_ 126 StePw_B_Rq 1;
BA_ "U_CD764_MY2022_Rx" SG_ 126 StePw_B_Rq 1;
BA_ "U_CDX706_MY2023_Rx" SG_ 126 StePw_B_Rq 1;
BA_ "U_P702_MY2021_Tx" SG_ 126 StePw_B_Rq 1;
BA_ "U_T6_MCA_MY2020_Tx" SG_ 126 StePw_B_Rq 1;
BA_ "U_CD542_MY2021_Tx" SG_ 126 StePw_B_Rq 1;
BA_ "U_U55X_MY2022_Tx" SG_ 126 StePw_B_Rq 1;
BA_ "U_CD764_MY2022_Tx" SG_ 126 StePw_B_Rq 1;
BA_ "U_CDX706_MY2023_Tx" SG_ 126 StePw_B_Rq 1;
BA_ "GenSigStartValueInteger" SG_ 126 StePinRelInit_An_Sns 65535;
BA_ "ContentDependant" SG_ 126 StePinRelInit_An_Sns 1;
BA_ "GenSigStartValue" SG_ 126 StePinRelInit_An_Sns 65535;
BA_ "U_CX727_MY2021_Rx" SG_ 126 StePinRelInit_An_Sns 1;
BA_ "U_P702_MY2021_Rx" SG_ 126 StePinRelInit_An_Sns 1;
BA_ "U_T6_MCA_MY2020_Rx" SG_ 126 StePinRelInit_An_Sns 1;
BA_ "U_CD542_MY2021_Rx" SG_ 126 StePinRelInit_An_Sns 1;
BA_ "U_U55X_MY2022_Rx" SG_ 126 StePinRelInit_An_Sns 1;
BA_ "U_CD764_MY2022_Rx" SG_ 126 StePinRelInit_An_Sns 1;
BA_ "U_CDX706_MY2023_Rx" SG_ 126 StePinRelInit_An_Sns 1;
BA_ "U_CX727_MY2021_Tx" SG_ 126 StePinRelInit_An_Sns 1;
BA_ "U_P702_MY2021_Tx" SG_ 126 StePinRelInit_An_Sns 1;
BA_ "U_T6_MCA_MY2020_Tx" SG_ 126 StePinRelInit_An_Sns 1;
BA_ "U_CD542_MY2021_Tx" SG_ 126 StePinRelInit_An_Sns 1;
BA_ "U_U55X_MY2022_Tx" SG_ 126 StePinRelInit_An_Sns 1;
BA_ "U_CD764_MY2022_Tx" SG_ 126 StePinRelInit_An_Sns 1;
BA_ "U_CDX706_MY2023_Tx" SG_ 126 StePinRelInit_An_Sns 1;
BA_ "GenSigStartValueInteger" SG_ 126 StePinCompAnEst_D_Qf 1;
BA_ "MetaData" SG_ 126 StePinCompAnEst_D_Qf 1;
BA_ "GenSigStartValue" SG_ 126 StePinCompAnEst_D_Qf 1;
BA_ "U_CX727_MY2021_Rx" SG_ 126 StePinCompAnEst_D_Qf 1;
BA_ "U_P702_MY2021_Rx" SG_ 126 StePinCompAnEst_D_Qf 1;
BA_ "U_T6_MCA_MY2020_Rx" SG_ 126 StePinCompAnEst_D_Qf 1;
BA_ "ECGUsedRxSignal" SG_ 126 StePinCompAnEst_D_Qf 1;
BA_ "U_CD542_MY2021_Rx" SG_ 126 StePinCompAnEst_D_Qf 1;
BA_ "U_U55X_MY2022_Rx" SG_ 126 StePinCompAnEst_D_Qf 1;
BA_ "U_CD764_MY2022_Rx" SG_ 126 StePinCompAnEst_D_Qf 1;
BA_ "U_CDX706_MY2023_Rx" SG_ 126 StePinCompAnEst_D_Qf 1;
BA_ "U_CX727_MY2021_Tx" SG_ 126 StePinCompAnEst_D_Qf 1;
BA_ "U_P702_MY2021_Tx" SG_ 126 StePinCompAnEst_D_Qf 1;
BA_ "U_T6_MCA_MY2020_Tx" SG_ 126 StePinCompAnEst_D_Qf 1;
BA_ "U_CD542_MY2021_Tx" SG_ 126 StePinCompAnEst_D_Qf 1;
BA_ "U_U55X_MY2022_Tx" SG_ 126 StePinCompAnEst_D_Qf 1;
BA_ "U_CD764_MY2022_Tx" SG_ 126 StePinCompAnEst_D_Qf 1;
BA_ "U_CDX706_MY2023_Tx" SG_ 126 StePinCompAnEst_D_Qf 1;
BA_ "GenSigStartValueInteger" SG_ 126 StePinComp_An_Est 16000;
BA_ "U_CX727_MY2021_Rx" SG_ 126 StePinComp_An_Est 1;
BA_ "U_P702_MY2021_Rx" SG_ 126 StePinComp_An_Est 1;
BA_ "U_T6_MCA_MY2020_Rx" SG_ 126 StePinComp_An_Est 1;
BA_ "ECGUsedRxSignal" SG_ 126 StePinComp_An_Est 1;
BA_ "U_CD542_MY2021_Rx" SG_ 126 StePinComp_An_Est 1;
BA_ "U_U55X_MY2022_Rx" SG_ 126 StePinComp_An_Est 1;
BA_ "U_CD764_MY2022_Rx" SG_ 126 StePinComp_An_Est 1;
BA_ "U_CDX706_MY2023_Rx" SG_ 126 StePinComp_An_Est 1;
BA_ "U_CX727_MY2021_Tx" SG_ 126 StePinComp_An_Est 1;
BA_ "U_P702_MY2021_Tx" SG_ 126 StePinComp_An_Est 1;
BA_ "U_T6_MCA_MY2020_Tx" SG_ 126 StePinComp_An_Est 1;
BA_ "U_CD542_MY2021_Tx" SG_ 126 StePinComp_An_Est 1;
BA_ "U_U55X_MY2022_Tx" SG_ 126 StePinComp_An_Est 1;
BA_ "U_CD764_MY2022_Tx" SG_ 126 StePinComp_An_Est 1;
BA_ "U_CDX706_MY2023_Tx" SG_ 126 StePinComp_An_Est 1;
BA_ "ContentDependant" SG_ 126 StePinAn_No_Cs 1;
BA_ "MetaData" SG_ 126 StePinAn_No_Cs 1;
BA_ "U_CX727_MY2021_Rx" SG_ 126 StePinAn_No_Cs 1;
BA_ "U_P702_MY2021_Rx" SG_ 126 StePinAn_No_Cs 1;
BA_ "U_T6_MCA_MY2020_Rx" SG_ 126 StePinAn_No_Cs 1;
BA_ "U_CD542_MY2021_Rx" SG_ 126 StePinAn_No_Cs 1;
BA_ "U_U55X_MY2022_Rx" SG_ 126 StePinAn_No_Cs 1;
BA_ "U_CD764_MY2022_Rx" SG_ 126 StePinAn_No_Cs 1;
BA_ "U_CDX706_MY2023_Rx" SG_ 126 StePinAn_No_Cs 1;
BA_ "U_CX727_MY2021_Tx" SG_ 126 StePinAn_No_Cs 1;
BA_ "U_P702_MY2021_Tx" SG_ 126 StePinAn_No_Cs 1;
BA_ "U_T6_MCA_MY2020_Tx" SG_ 126 StePinAn_No_Cs 1;
BA_ "U_CD542_MY2021_Tx" SG_ 126 StePinAn_No_Cs 1;
BA_ "U_U55X_MY2022_Tx" SG_ 126 StePinAn_No_Cs 1;
BA_ "U_CD764_MY2022_Tx" SG_ 126 StePinAn_No_Cs 1;
BA_ "U_CDX706_MY2023_Tx" SG_ 126 StePinAn_No_Cs 1;
BA_ "MetaData" SG_ 126 StePinAn_No_Cnt 1;
BA_ "U_CX727_MY2021_Rx" SG_ 126 StePinAn_No_Cnt 1;
BA_ "U_P702_MY2021_Rx" SG_ 126 StePinAn_No_Cnt 1;
BA_ "U_T6_MCA_MY2020_Rx" SG_ 126 StePinAn_No_Cnt 1;
BA_ "U_CD542_MY2021_Rx" SG_ 126 StePinAn_No_Cnt 1;
BA_ "U_U55X_MY2022_Rx" SG_ 126 StePinAn_No_Cnt 1;
BA_ "U_CD764_MY2022_Rx" SG_ 126 StePinAn_No_Cnt 1;
BA_ "U_CDX706_MY2023_Rx" SG_ 126 StePinAn_No_Cnt 1;
BA_ "U_CX727_MY2021_Tx" SG_ 126 StePinAn_No_Cnt 1;
BA_ "U_P702_MY2021_Tx" SG_ 126 StePinAn_No_Cnt 1;
BA_ "U_T6_MCA_MY2020_Tx" SG_ 126 StePinAn_No_Cnt 1;
BA_ "U_CD542_MY2021_Tx" SG_ 126 StePinAn_No_Cnt 1;
BA_ "U_U55X_MY2022_Tx" SG_ 126 StePinAn_No_Cnt 1;
BA_ "U_CD764_MY2022_Tx" SG_ 126 StePinAn_No_Cnt 1;
BA_ "U_CDX706_MY2023_Tx" SG_ 126 StePinAn_No_Cnt 1;
BA_ "GenSigStartValueInteger" SG_ 1430 ABS_GWOnBoardTester 255;
BA_ "ContentDependant" SG_ 1430 ABS_GWOnBoardTester 1;
BA_ "GenSigStartValue" SG_ 1430 ABS_GWOnBoardTester 255;
BA_ "U_CX727_MY2021_Tx" SG_ 1430 ABS_GWOnBoardTester 1;
BA_ "U_P702_MY2021_Tx" SG_ 1430 ABS_GWOnBoardTester 1;
BA_ "U_T6_MCA_MY2020_Tx" SG_ 1430 ABS_GWOnBoardTester 1;
BA_ "U_CD542_MY2021_Tx" SG_ 1430 ABS_GWOnBoardTester 1;
BA_ "U_U55X_MY2022_Tx" SG_ 1430 ABS_GWOnBoardTester 1;
BA_ "U_CD764_MY2022_Tx" SG_ 1430 ABS_GWOnBoardTester 1;
BA_ "U_CDX706_MY2023_Tx" SG_ 1430 ABS_GWOnBoardTester 1;
BA_ "GenSigStartValueInteger" SG_ 1430 ABS_GWNMProxy 255;
BA_ "ContentDependant" SG_ 1430 ABS_GWNMProxy 1;
BA_ "GenSigStartValue" SG_ 1430 ABS_GWNMProxy 255;
BA_ "U_CX727_MY2021_Tx" SG_ 1430 ABS_GWNMProxy 1;
BA_ "U_P702_MY2021_Tx" SG_ 1430 ABS_GWNMProxy 1;
BA_ "U_T6_MCA_MY2020_Tx" SG_ 1430 ABS_GWNMProxy 1;
BA_ "U_CD542_MY2021_Tx" SG_ 1430 ABS_GWNMProxy 1;
BA_ "U_U55X_MY2022_Tx" SG_ 1430 ABS_GWNMProxy 1;
BA_ "U_CD764_MY2022_Tx" SG_ 1430 ABS_GWNMProxy 1;
BA_ "U_CDX706_MY2023_Tx" SG_ 1430 ABS_GWNMProxy 1;
BA_ "GenSigStartValueInteger" SG_ 1430 ABS_AutoSarNMReserved4 255;
BA_ "ContentDependant" SG_ 1430 ABS_AutoSarNMReserved4 1;
BA_ "GenSigStartValue" SG_ 1430 ABS_AutoSarNMReserved4 255;
BA_ "U_CX727_MY2021_Tx" SG_ 1430 ABS_AutoSarNMReserved4 1;
BA_ "U_P702_MY2021_Tx" SG_ 1430 ABS_AutoSarNMReserved4 1;
BA_ "U_T6_MCA_MY2020_Tx" SG_ 1430 ABS_AutoSarNMReserved4 1;
BA_ "U_CD542_MY2021_Tx" SG_ 1430 ABS_AutoSarNMReserved4 1;
BA_ "U_U55X_MY2022_Tx" SG_ 1430 ABS_AutoSarNMReserved4 1;
BA_ "U_CD764_MY2022_Tx" SG_ 1430 ABS_AutoSarNMReserved4 1;
BA_ "U_CDX706_MY2023_Tx" SG_ 1430 ABS_AutoSarNMReserved4 1;
BA_ "GenSigStartValueInteger" SG_ 1430 ABS_AutoSarNMReserved3 255;
BA_ "ContentDependant" SG_ 1430 ABS_AutoSarNMReserved3 1;
BA_ "GenSigStartValue" SG_ 1430 ABS_AutoSarNMReserved3 255;
BA_ "U_CX727_MY2021_Tx" SG_ 1430 ABS_AutoSarNMReserved3 1;
BA_ "U_P702_MY2021_Tx" SG_ 1430 ABS_AutoSarNMReserved3 1;
BA_ "U_T6_MCA_MY2020_Tx" SG_ 1430 ABS_AutoSarNMReserved3 1;
BA_ "U_CD542_MY2021_Tx" SG_ 1430 ABS_AutoSarNMReserved3 1;
BA_ "U_U55X_MY2022_Tx" SG_ 1430 ABS_AutoSarNMReserved3 1;
BA_ "U_CD764_MY2022_Tx" SG_ 1430 ABS_AutoSarNMReserved3 1;
BA_ "U_CDX706_MY2023_Tx" SG_ 1430 ABS_AutoSarNMReserved3 1;
BA_ "GenSigStartValueInteger" SG_ 1430 ABS_AutoSarNMReserved2 255;
BA_ "ContentDependant" SG_ 1430 ABS_AutoSarNMReserved2 1;
BA_ "GenSigStartValue" SG_ 1430 ABS_AutoSarNMReserved2 255;
BA_ "U_CX727_MY2021_Tx" SG_ 1430 ABS_AutoSarNMReserved2 1;
BA_ "U_P702_MY2021_Tx" SG_ 1430 ABS_AutoSarNMReserved2 1;
BA_ "U_T6_MCA_MY2020_Tx" SG_ 1430 ABS_AutoSarNMReserved2 1;
BA_ "U_CD542_MY2021_Tx" SG_ 1430 ABS_AutoSarNMReserved2 1;
BA_ "U_U55X_MY2022_Tx" SG_ 1430 ABS_AutoSarNMReserved2 1;
BA_ "U_CD764_MY2022_Tx" SG_ 1430 ABS_AutoSarNMReserved2 1;
BA_ "U_CDX706_MY2023_Tx" SG_ 1430 ABS_AutoSarNMReserved2 1;
BA_ "GenSigStartValueInteger" SG_ 1430 ABS_AutoSarNMReserved1 255;
BA_ "ContentDependant" SG_ 1430 ABS_AutoSarNMReserved1 1;
BA_ "GenSigStartValue" SG_ 1430 ABS_AutoSarNMReserved1 255;
BA_ "U_CX727_MY2021_Tx" SG_ 1430 ABS_AutoSarNMReserved1 1;
BA_ "U_P702_MY2021_Tx" SG_ 1430 ABS_AutoSarNMReserved1 1;
BA_ "U_T6_MCA_MY2020_Tx" SG_ 1430 ABS_AutoSarNMReserved1 1;
BA_ "U_CD542_MY2021_Tx" SG_ 1430 ABS_AutoSarNMReserved1 1;
BA_ "U_U55X_MY2022_Tx" SG_ 1430 ABS_AutoSarNMReserved1 1;
BA_ "U_CD764_MY2022_Tx" SG_ 1430 ABS_AutoSarNMReserved1 1;
BA_ "U_CDX706_MY2023_Tx" SG_ 1430 ABS_AutoSarNMReserved1 1;
BA_ "GenSigStartValueInteger" SG_ 1430 ABS_AutoSarNMNodeId 150;
BA_ "ContentDependant" SG_ 1430 ABS_AutoSarNMNodeId 1;
BA_ "GenSigStartValue" SG_ 1430 ABS_AutoSarNMNodeId 150;
BA_ "U_CX727_MY2021_Tx" SG_ 1430 ABS_AutoSarNMNodeId 1;
BA_ "U_P702_MY2021_Tx" SG_ 1430 ABS_AutoSarNMNodeId 1;
BA_ "U_T6_MCA_MY2020_Tx" SG_ 1430 ABS_AutoSarNMNodeId 1;
BA_ "U_CD542_MY2021_Tx" SG_ 1430 ABS_AutoSarNMNodeId 1;
BA_ "U_U55X_MY2022_Tx" SG_ 1430 ABS_AutoSarNMNodeId 1;
BA_ "U_CD764_MY2022_Tx" SG_ 1430 ABS_AutoSarNMNodeId 1;
BA_ "U_CDX706_MY2023_Tx" SG_ 1430 ABS_AutoSarNMNodeId 1;
BA_ "ContentDependant" SG_ 1430 ABS_AutoSarNMControl 1;
BA_ "U_CX727_MY2021_Tx" SG_ 1430 ABS_AutoSarNMControl 1;
BA_ "U_P702_MY2021_Tx" SG_ 1430 ABS_AutoSarNMControl 1;
BA_ "U_T6_MCA_MY2020_Tx" SG_ 1430 ABS_AutoSarNMControl 1;
BA_ "U_CD542_MY2021_Tx" SG_ 1430 ABS_AutoSarNMControl 1;
BA_ "U_U55X_MY2022_Tx" SG_ 1430 ABS_AutoSarNMControl 1;
BA_ "U_CD764_MY2022_Tx" SG_ 1430 ABS_AutoSarNMControl 1;
BA_ "U_CDX706_MY2023_Tx" SG_ 1430 ABS_AutoSarNMControl 1;
BA_ "GenSigStartValueInteger" SG_ 1200 HsaTrnAout_Tq_Rq 32768;
BA_ "U_CX727_MY2021_Tx" SG_ 1200 HsaTrnAout_Tq_Rq 1;
BA_ "U_P702_MY2021_Tx" SG_ 1200 HsaTrnAout_Tq_Rq 1;
BA_ "U_T6_MCA_MY2020_Tx" SG_ 1200 HsaTrnAout_Tq_Rq 1;
BA_ "U_CD542_MY2021_Tx" SG_ 1200 HsaTrnAout_Tq_Rq 1;
BA_ "U_U55X_MY2022_Tx" SG_ 1200 HsaTrnAout_Tq_Rq 1;
BA_ "U_CD764_MY2022_Tx" SG_ 1200 HsaTrnAout_Tq_Rq 1;
BA_ "U_CDX706_MY2023_Tx" SG_ 1200 HsaTrnAout_Tq_Rq 1;
BA_ "GenSigStartValueInteger" SG_ 1200 BrkBstrVac_P_Actl 127;
BA_ "GenSigStartValue" SG_ 1200 BrkBstrVac_P_Actl 127;
BA_ "U_CX727_MY2021_Rx" SG_ 1200 BrkBstrVac_P_Actl 1;
BA_ "U_P702_MY2021_Rx" SG_ 1200 BrkBstrVac_P_Actl 1;
BA_ "U_T6_MCA_MY2020_Rx" SG_ 1200 BrkBstrVac_P_Actl 1;
BA_ "U_CD542_MY2021_Rx" SG_ 1200 BrkBstrVac_P_Actl 1;
BA_ "U_U55X_MY2022_Rx" SG_ 1200 BrkBstrVac_P_Actl 1;
BA_ "U_CD764_MY2022_Rx" SG_ 1200 BrkBstrVac_P_Actl 1;
BA_ "U_CDX706_MY2023_Rx" SG_ 1200 BrkBstrVac_P_Actl 1;
BA_ "U_CX727_MY2021_Tx" SG_ 1200 BrkBstrVac_P_Actl 1;
BA_ "U_P702_MY2021_Tx" SG_ 1200 BrkBstrVac_P_Actl 1;
BA_ "U_T6_MCA_MY2020_Tx" SG_ 1200 BrkBstrVac_P_Actl 1;
BA_ "U_CD542_MY2021_Tx" SG_ 1200 BrkBstrVac_P_Actl 1;
BA_ "U_U55X_MY2022_Tx" SG_ 1200 BrkBstrVac_P_Actl 1;
BA_ "U_CD764_MY2022_Tx" SG_ 1200 BrkBstrVac_P_Actl 1;
BA_ "U_CDX706_MY2023_Tx" SG_ 1200 BrkBstrVac_P_Actl 1;
BA_ "GenSigStartValueInteger" SG_ 1200 YawStabilityIndex 256;
BA_ "U_CX727_MY2021_Rx" SG_ 1200 YawStabilityIndex 1;
BA_ "U_P702_MY2021_Rx" SG_ 1200 YawStabilityIndex 1;
BA_ "U_T6_MCA_MY2020_Rx" SG_ 1200 YawStabilityIndex 1;
BA_ "U_CD542_MY2021_Rx" SG_ 1200 YawStabilityIndex 1;
BA_ "U_U55X_MY2022_Rx" SG_ 1200 YawStabilityIndex 1;
BA_ "U_CD764_MY2022_Rx" SG_ 1200 YawStabilityIndex 1;
BA_ "U_CDX706_MY2023_Rx" SG_ 1200 YawStabilityIndex 1;
BA_ "U_CX727_MY2021_Tx" SG_ 1200 YawStabilityIndex 1;
BA_ "U_P702_MY2021_Tx" SG_ 1200 YawStabilityIndex 1;
BA_ "U_T6_MCA_MY2020_Tx" SG_ 1200 YawStabilityIndex 1;
BA_ "U_CD542_MY2021_Tx" SG_ 1200 YawStabilityIndex 1;
BA_ "U_U55X_MY2022_Tx" SG_ 1200 YawStabilityIndex 1;
BA_ "U_CD764_MY2022_Tx" SG_ 1200 YawStabilityIndex 1;
BA_ "U_CDX706_MY2023_Tx" SG_ 1200 YawStabilityIndex 1;
BA_ "U_CX727_MY2021_Rx" SG_ 1200 BrkTot_Tq_RqDrv 1;
BA_ "U_P702_MY2021_Rx" SG_ 1200 BrkTot_Tq_RqDrv 1;
BA_ "U_T6_MCA_MY2020_Rx" SG_ 1200 BrkTot_Tq_RqDrv 1;
BA_ "U_CD542_MY2021_Rx" SG_ 1200 BrkTot_Tq_RqDrv 1;
BA_ "U_U55X_MY2022_Rx" SG_ 1200 BrkTot_Tq_RqDrv 1;
BA_ "U_CD764_MY2022_Rx" SG_ 1200 BrkTot_Tq_RqDrv 1;
BA_ "U_CDX706_MY2023_Rx" SG_ 1200 BrkTot_Tq_RqDrv 1;
BA_ "U_CX727_MY2021_Tx" SG_ 1200 BrkTot_Tq_RqDrv 1;
BA_ "U_P702_MY2021_Tx" SG_ 1200 BrkTot_Tq_RqDrv 1;
BA_ "U_T6_MCA_MY2020_Tx" SG_ 1200 BrkTot_Tq_RqDrv 1;
BA_ "U_CD542_MY2021_Tx" SG_ 1200 BrkTot_Tq_RqDrv 1;
BA_ "U_U55X_MY2022_Tx" SG_ 1200 BrkTot_Tq_RqDrv 1;
BA_ "U_CD764_MY2022_Tx" SG_ 1200 BrkTot_Tq_RqDrv 1;
BA_ "U_CDX706_MY2023_Tx" SG_ 1200 BrkTot_Tq_RqDrv 1;
BA_ "MetaData" SG_ 1200 BrkTotTqRqDrv_No_Cnt 1;
BA_ "U_CX727_MY2021_Rx" SG_ 1200 BrkTotTqRqDrv_No_Cnt 1;
BA_ "U_P702_MY2021_Rx" SG_ 1200 BrkTotTqRqDrv_No_Cnt 1;
BA_ "U_T6_MCA_MY2020_Rx" SG_ 1200 BrkTotTqRqDrv_No_Cnt 1;
BA_ "U_CD542_MY2021_Rx" SG_ 1200 BrkTotTqRqDrv_No_Cnt 1;
BA_ "U_U55X_MY2022_Rx" SG_ 1200 BrkTotTqRqDrv_No_Cnt 1;
BA_ "U_CD764_MY2022_Rx" SG_ 1200 BrkTotTqRqDrv_No_Cnt 1;
BA_ "U_CDX706_MY2023_Rx" SG_ 1200 BrkTotTqRqDrv_No_Cnt 1;
BA_ "U_CX727_MY2021_Tx" SG_ 1200 BrkTotTqRqDrv_No_Cnt 1;
BA_ "U_P702_MY2021_Tx" SG_ 1200 BrkTotTqRqDrv_No_Cnt 1;
BA_ "U_T6_MCA_MY2020_Tx" SG_ 1200 BrkTotTqRqDrv_No_Cnt 1;
BA_ "U_CD542_MY2021_Tx" SG_ 1200 BrkTotTqRqDrv_No_Cnt 1;
BA_ "U_U55X_MY2022_Tx" SG_ 1200 BrkTotTqRqDrv_No_Cnt 1;
BA_ "U_CD764_MY2022_Tx" SG_ 1200 BrkTotTqRqDrv_No_Cnt 1;
BA_ "U_CDX706_MY2023_Tx" SG_ 1200 BrkTotTqRqDrv_No_Cnt 1;
BA_ "MetaData" SG_ 1200 BrkTotTqRqDrv_No_Cs 1;
BA_ "U_CX727_MY2021_Rx" SG_ 1200 BrkTotTqRqDrv_No_Cs 1;
BA_ "U_P702_MY2021_Rx" SG_ 1200 BrkTotTqRqDrv_No_Cs 1;
BA_ "U_T6_MCA_MY2020_Rx" SG_ 1200 BrkTotTqRqDrv_No_Cs 1;
BA_ "U_CD542_MY2021_Rx" SG_ 1200 BrkTotTqRqDrv_No_Cs 1;
BA_ "U_U55X_MY2022_Rx" SG_ 1200 BrkTotTqRqDrv_No_Cs 1;
BA_ "U_CD764_MY2022_Rx" SG_ 1200 BrkTotTqRqDrv_No_Cs 1;
BA_ "U_CDX706_MY2023_Rx" SG_ 1200 BrkTotTqRqDrv_No_Cs 1;
BA_ "U_CX727_MY2021_Tx" SG_ 1200 BrkTotTqRqDrv_No_Cs 1;
BA_ "U_P702_MY2021_Tx" SG_ 1200 BrkTotTqRqDrv_No_Cs 1;
BA_ "U_T6_MCA_MY2020_Tx" SG_ 1200 BrkTotTqRqDrv_No_Cs 1;
BA_ "U_CD542_MY2021_Tx" SG_ 1200 BrkTotTqRqDrv_No_Cs 1;
BA_ "U_U55X_MY2022_Tx" SG_ 1200 BrkTotTqRqDrv_No_Cs 1;
BA_ "U_CD764_MY2022_Tx" SG_ 1200 BrkTotTqRqDrv_No_Cs 1;
BA_ "U_CDX706_MY2023_Tx" SG_ 1200 BrkTotTqRqDrv_No_Cs 1;
BA_ "U_CX727_MY2021_Tx" SG_ 1200 HsaStat_D_Dsply 1;
BA_ "U_P702_MY2021_Tx" SG_ 1200 HsaStat_D_Dsply 1;
BA_ "U_T6_MCA_MY2020_Tx" SG_ 1200 HsaStat_D_Dsply 1;
BA_ "U_CD542_MY2021_Tx" SG_ 1200 HsaStat_D_Dsply 1;
BA_ "U_U55X_MY2022_Tx" SG_ 1200 HsaStat_D_Dsply 1;
BA_ "U_CD764_MY2022_Tx" SG_ 1200 HsaStat_D_Dsply 1;
BA_ "U_T6_MCA_MY2020_Rx" SG_ 1200 BrkHold_D_Stat 1;
BA_ "U_CD542_MY2021_Rx" SG_ 1200 BrkHold_D_Stat 1;
BA_ "U_U55X_MY2022_Rx" SG_ 1200 BrkHold_D_Stat 1;
BA_ "U_CD764_MY2022_Rx" SG_ 1200 BrkHold_D_Stat 1;
BA_ "U_CDX706_MY2023_Rx" SG_ 1200 BrkHold_D_Stat 1;
BA_ "U_T6_MCA_MY2020_Tx" SG_ 1200 BrkHold_D_Stat 1;
BA_ "U_CD542_MY2021_Tx" SG_ 1200 BrkHold_D_Stat 1;
BA_ "U_U55X_MY2022_Tx" SG_ 1200 BrkHold_D_Stat 1;
BA_ "U_CD764_MY2022_Tx" SG_ 1200 BrkHold_D_Stat 1;
BA_ "U_CDX706_MY2023_Tx" SG_ 1200 BrkHold_D_Stat 1;
BA_ "GenSigSendType" SG_ 1102 SelDrvMdePos12_D_Stat 3;
BA_ "GenSigStartValueInteger" SG_ 1102 SelDrvMdePos12_D_Stat 31;
BA_ "GenSigStartValue" SG_ 1102 SelDrvMdePos12_D_Stat 31;
BA_ "U_CX727_MY2021_Tx" SG_ 1102 SelDrvMdePos12_D_Stat 1;
BA_ "U_P702_MY2021_Tx" SG_ 1102 SelDrvMdePos12_D_Stat 1;
BA_ "U_T6_MCA_MY2020_Tx" SG_ 1102 SelDrvMdePos12_D_Stat 1;
BA_ "U_CD542_MY2021_Tx" SG_ 1102 SelDrvMdePos12_D_Stat 1;
BA_ "U_U55X_MY2022_Tx" SG_ 1102 SelDrvMdePos12_D_Stat 1;
BA_ "U_CD764_MY2022_Tx" SG_ 1102 SelDrvMdePos12_D_Stat 1;
BA_ "U_CDX706_MY2023_Tx" SG_ 1102 SelDrvMdePos12_D_Stat 1;
BA_ "GenSigSendType" SG_ 1102 SelDrvMdePos11_D_Stat 3;
BA_ "GenSigStartValueInteger" SG_ 1102 SelDrvMdePos11_D_Stat 31;
BA_ "GenSigStartValue" SG_ 1102 SelDrvMdePos11_D_Stat 31;
BA_ "U_CX727_MY2021_Tx" SG_ 1102 SelDrvMdePos11_D_Stat 1;
BA_ "U_P702_MY2021_Tx" SG_ 1102 SelDrvMdePos11_D_Stat 1;
BA_ "U_T6_MCA_MY2020_Tx" SG_ 1102 SelDrvMdePos11_D_Stat 1;
BA_ "U_CD542_MY2021_Tx" SG_ 1102 SelDrvMdePos11_D_Stat 1;
BA_ "U_U55X_MY2022_Tx" SG_ 1102 SelDrvMdePos11_D_Stat 1;
BA_ "U_CD764_MY2022_Tx" SG_ 1102 SelDrvMdePos11_D_Stat 1;
BA_ "U_CDX706_MY2023_Tx" SG_ 1102 SelDrvMdePos11_D_Stat 1;
BA_ "GenSigSendType" SG_ 1102 SelDrvMdePos10_D_Stat 3;
BA_ "GenSigStartValueInteger" SG_ 1102 SelDrvMdePos10_D_Stat 31;
BA_ "GenSigStartValue" SG_ 1102 SelDrvMdePos10_D_Stat 31;
BA_ "U_CX727_MY2021_Tx" SG_ 1102 SelDrvMdePos10_D_Stat 1;
BA_ "U_P702_MY2021_Tx" SG_ 1102 SelDrvMdePos10_D_Stat 1;
BA_ "U_T6_MCA_MY2020_Tx" SG_ 1102 SelDrvMdePos10_D_Stat 1;
BA_ "U_CD542_MY2021_Tx" SG_ 1102 SelDrvMdePos10_D_Stat 1;
BA_ "U_U55X_MY2022_Tx" SG_ 1102 SelDrvMdePos10_D_Stat 1;
BA_ "U_CD764_MY2022_Tx" SG_ 1102 SelDrvMdePos10_D_Stat 1;
BA_ "U_CDX706_MY2023_Tx" SG_ 1102 SelDrvMdePos10_D_Stat 1;
BA_ "GenSigSendType" SG_ 1102 SelDrvMdePos09_D_Stat 3;
BA_ "GenSigStartValueInteger" SG_ 1102 SelDrvMdePos09_D_Stat 31;
BA_ "GenSigStartValue" SG_ 1102 SelDrvMdePos09_D_Stat 31;
BA_ "U_CX727_MY2021_Tx" SG_ 1102 SelDrvMdePos09_D_Stat 1;
BA_ "U_P702_MY2021_Tx" SG_ 1102 SelDrvMdePos09_D_Stat 1;
BA_ "U_T6_MCA_MY2020_Tx" SG_ 1102 SelDrvMdePos09_D_Stat 1;
BA_ "U_CD542_MY2021_Tx" SG_ 1102 SelDrvMdePos09_D_Stat 1;
BA_ "U_U55X_MY2022_Tx" SG_ 1102 SelDrvMdePos09_D_Stat 1;
BA_ "U_CD764_MY2022_Tx" SG_ 1102 SelDrvMdePos09_D_Stat 1;
BA_ "U_CDX706_MY2023_Tx" SG_ 1102 SelDrvMdePos09_D_Stat 1;
BA_ "GenSigSendType" SG_ 1102 SelDrvMdePos08_D_Stat 3;
BA_ "GenSigStartValueInteger" SG_ 1102 SelDrvMdePos08_D_Stat 31;
BA_ "GenSigStartValue" SG_ 1102 SelDrvMdePos08_D_Stat 31;
BA_ "U_CX727_MY2021_Tx" SG_ 1102 SelDrvMdePos08_D_Stat 1;
BA_ "U_P702_MY2021_Tx" SG_ 1102 SelDrvMdePos08_D_Stat 1;
BA_ "U_T6_MCA_MY2020_Tx" SG_ 1102 SelDrvMdePos08_D_Stat 1;
BA_ "U_CD542_MY2021_Tx" SG_ 1102 SelDrvMdePos08_D_Stat 1;
BA_ "U_U55X_MY2022_Tx" SG_ 1102 SelDrvMdePos08_D_Stat 1;
BA_ "U_CD764_MY2022_Tx" SG_ 1102 SelDrvMdePos08_D_Stat 1;
BA_ "U_CDX706_MY2023_Tx" SG_ 1102 SelDrvMdePos08_D_Stat 1;
BA_ "GenSigSendType" SG_ 1102 SelDrvMdePos07_D_Stat 3;
BA_ "GenSigStartValueInteger" SG_ 1102 SelDrvMdePos07_D_Stat 31;
BA_ "GenSigStartValue" SG_ 1102 SelDrvMdePos07_D_Stat 31;
BA_ "U_CX727_MY2021_Tx" SG_ 1102 SelDrvMdePos07_D_Stat 1;
BA_ "U_P702_MY2021_Tx" SG_ 1102 SelDrvMdePos07_D_Stat 1;
BA_ "U_T6_MCA_MY2020_Tx" SG_ 1102 SelDrvMdePos07_D_Stat 1;
BA_ "U_CD542_MY2021_Tx" SG_ 1102 SelDrvMdePos07_D_Stat 1;
BA_ "U_U55X_MY2022_Tx" SG_ 1102 SelDrvMdePos07_D_Stat 1;
BA_ "U_CD764_MY2022_Tx" SG_ 1102 SelDrvMdePos07_D_Stat 1;
BA_ "U_CDX706_MY2023_Tx" SG_ 1102 SelDrvMdePos07_D_Stat 1;
BA_ "GenSigSendType" SG_ 1102 SelDrvMdePos06_D_Stat 3;
BA_ "GenSigStartValueInteger" SG_ 1102 SelDrvMdePos06_D_Stat 31;
BA_ "GenSigStartValue" SG_ 1102 SelDrvMdePos06_D_Stat 31;
BA_ "U_CX727_MY2021_Tx" SG_ 1102 SelDrvMdePos06_D_Stat 1;
BA_ "U_P702_MY2021_Tx" SG_ 1102 SelDrvMdePos06_D_Stat 1;
BA_ "U_T6_MCA_MY2020_Tx" SG_ 1102 SelDrvMdePos06_D_Stat 1;
BA_ "U_CD542_MY2021_Tx" SG_ 1102 SelDrvMdePos06_D_Stat 1;
BA_ "U_U55X_MY2022_Tx" SG_ 1102 SelDrvMdePos06_D_Stat 1;
BA_ "U_CD764_MY2022_Tx" SG_ 1102 SelDrvMdePos06_D_Stat 1;
BA_ "U_CDX706_MY2023_Tx" SG_ 1102 SelDrvMdePos06_D_Stat 1;
BA_ "GenSigSendType" SG_ 1102 SelDrvMdePos05_D_Stat 3;
BA_ "GenSigStartValueInteger" SG_ 1102 SelDrvMdePos05_D_Stat 31;
BA_ "GenSigStartValue" SG_ 1102 SelDrvMdePos05_D_Stat 31;
BA_ "U_CX727_MY2021_Tx" SG_ 1102 SelDrvMdePos05_D_Stat 1;
BA_ "U_P702_MY2021_Tx" SG_ 1102 SelDrvMdePos05_D_Stat 1;
BA_ "U_T6_MCA_MY2020_Tx" SG_ 1102 SelDrvMdePos05_D_Stat 1;
BA_ "U_CD542_MY2021_Tx" SG_ 1102 SelDrvMdePos05_D_Stat 1;
BA_ "U_U55X_MY2022_Tx" SG_ 1102 SelDrvMdePos05_D_Stat 1;
BA_ "U_CD764_MY2022_Tx" SG_ 1102 SelDrvMdePos05_D_Stat 1;
BA_ "U_CDX706_MY2023_Tx" SG_ 1102 SelDrvMdePos05_D_Stat 1;
BA_ "GenSigSendType" SG_ 1102 SelDrvMdePos04_D_Stat 3;
BA_ "GenSigStartValueInteger" SG_ 1102 SelDrvMdePos04_D_Stat 31;
BA_ "GenSigStartValue" SG_ 1102 SelDrvMdePos04_D_Stat 31;
BA_ "U_CX727_MY2021_Tx" SG_ 1102 SelDrvMdePos04_D_Stat 1;
BA_ "U_P702_MY2021_Tx" SG_ 1102 SelDrvMdePos04_D_Stat 1;
BA_ "U_T6_MCA_MY2020_Tx" SG_ 1102 SelDrvMdePos04_D_Stat 1;
BA_ "U_CD542_MY2021_Tx" SG_ 1102 SelDrvMdePos04_D_Stat 1;
BA_ "U_U55X_MY2022_Tx" SG_ 1102 SelDrvMdePos04_D_Stat 1;
BA_ "U_CD764_MY2022_Tx" SG_ 1102 SelDrvMdePos04_D_Stat 1;
BA_ "U_CDX706_MY2023_Tx" SG_ 1102 SelDrvMdePos04_D_Stat 1;
BA_ "GenSigSendType" SG_ 1102 SelDrvMdePos03_D_Stat 3;
BA_ "GenSigStartValueInteger" SG_ 1102 SelDrvMdePos03_D_Stat 31;
BA_ "GenSigStartValue" SG_ 1102 SelDrvMdePos03_D_Stat 31;
BA_ "U_CX727_MY2021_Tx" SG_ 1102 SelDrvMdePos03_D_Stat 1;
BA_ "U_P702_MY2021_Tx" SG_ 1102 SelDrvMdePos03_D_Stat 1;
BA_ "U_T6_MCA_MY2020_Tx" SG_ 1102 SelDrvMdePos03_D_Stat 1;
BA_ "U_CD542_MY2021_Tx" SG_ 1102 SelDrvMdePos03_D_Stat 1;
BA_ "U_U55X_MY2022_Tx" SG_ 1102 SelDrvMdePos03_D_Stat 1;
BA_ "U_CD764_MY2022_Tx" SG_ 1102 SelDrvMdePos03_D_Stat 1;
BA_ "U_CDX706_MY2023_Tx" SG_ 1102 SelDrvMdePos03_D_Stat 1;
BA_ "GenSigSendType" SG_ 1102 SelDrvMdePos02_D_Stat 3;
BA_ "GenSigStartValueInteger" SG_ 1102 SelDrvMdePos02_D_Stat 31;
BA_ "GenSigStartValue" SG_ 1102 SelDrvMdePos02_D_Stat 31;
BA_ "U_CX727_MY2021_Tx" SG_ 1102 SelDrvMdePos02_D_Stat 1;
BA_ "U_P702_MY2021_Tx" SG_ 1102 SelDrvMdePos02_D_Stat 1;
BA_ "U_T6_MCA_MY2020_Tx" SG_ 1102 SelDrvMdePos02_D_Stat 1;
BA_ "U_CD542_MY2021_Tx" SG_ 1102 SelDrvMdePos02_D_Stat 1;
BA_ "U_U55X_MY2022_Tx" SG_ 1102 SelDrvMdePos02_D_Stat 1;
BA_ "U_CD764_MY2022_Tx" SG_ 1102 SelDrvMdePos02_D_Stat 1;
BA_ "U_CDX706_MY2023_Tx" SG_ 1102 SelDrvMdePos02_D_Stat 1;
BA_ "GenSigSendType" SG_ 1102 SelDrvMdePos01_D_Stat 3;
BA_ "GenSigStartValueInteger" SG_ 1102 SelDrvMdePos01_D_Stat 31;
BA_ "GenSigStartValue" SG_ 1102 SelDrvMdePos01_D_Stat 31;
BA_ "U_CX727_MY2021_Tx" SG_ 1102 SelDrvMdePos01_D_Stat 1;
BA_ "U_P702_MY2021_Tx" SG_ 1102 SelDrvMdePos01_D_Stat 1;
BA_ "U_T6_MCA_MY2020_Tx" SG_ 1102 SelDrvMdePos01_D_Stat 1;
BA_ "U_CD542_MY2021_Tx" SG_ 1102 SelDrvMdePos01_D_Stat 1;
BA_ "U_U55X_MY2022_Tx" SG_ 1102 SelDrvMdePos01_D_Stat 1;
BA_ "U_CD764_MY2022_Tx" SG_ 1102 SelDrvMdePos01_D_Stat 1;
BA_ "U_CDX706_MY2023_Tx" SG_ 1102 SelDrvMdePos01_D_Stat 1;
BA_ "GenSigSendType" SG_ 1056 AutoEpbButtnOn_B_Stat 3;
BA_ "U_T6_MCA_MY2020_Tx" SG_ 1056 AutoEpbButtnOn_B_Stat 1;
BA_ "U_U55X_MY2022_Tx" SG_ 1056 AutoEpbButtnOn_B_Stat 1;
BA_ "GenSigStartValue" SG_ 1056 VehVActlBrk_No_Corr 254;
BA_ "U_CDX706_MY2023_Rx" SG_ 1056 VehVActlBrk_No_Corr 1;
BA_ "U_CDX706_MY2023_Tx" SG_ 1056 VehVActlBrk_No_Corr 1;
BA_ "GenSigSendType" SG_ 1056 AutoEpbMsgTxt_D_Rq 3;
BA_ "U_T6_MCA_MY2020_Tx" SG_ 1056 AutoEpbMsgTxt_D_Rq 1;
BA_ "U_U55X_MY2022_Tx" SG_ 1056 AutoEpbMsgTxt_D_Rq 1;
BA_ "GenSigSendType" SG_ 1056 SelDrvMdePos12_B_Avail 3;
BA_ "U_CX727_MY2021_Tx" SG_ 1056 SelDrvMdePos12_B_Avail 1;
BA_ "U_P702_MY2021_Tx" SG_ 1056 SelDrvMdePos12_B_Avail 1;
BA_ "U_T6_MCA_MY2020_Tx" SG_ 1056 SelDrvMdePos12_B_Avail 1;
BA_ "U_CD542_MY2021_Tx" SG_ 1056 SelDrvMdePos12_B_Avail 1;
BA_ "U_U55X_MY2022_Tx" SG_ 1056 SelDrvMdePos12_B_Avail 1;
BA_ "U_CD764_MY2022_Tx" SG_ 1056 SelDrvMdePos12_B_Avail 1;
BA_ "U_CDX706_MY2023_Tx" SG_ 1056 SelDrvMdePos12_B_Avail 1;
BA_ "GenSigSendType" SG_ 1056 SelDrvMdePos11_B_Avail 3;
BA_ "U_CX727_MY2021_Tx" SG_ 1056 SelDrvMdePos11_B_Avail 1;
BA_ "U_P702_MY2021_Tx" SG_ 1056 SelDrvMdePos11_B_Avail 1;
BA_ "U_T6_MCA_MY2020_Tx" SG_ 1056 SelDrvMdePos11_B_Avail 1;
BA_ "U_CD542_MY2021_Tx" SG_ 1056 SelDrvMdePos11_B_Avail 1;
BA_ "U_U55X_MY2022_Tx" SG_ 1056 SelDrvMdePos11_B_Avail 1;
BA_ "U_CD764_MY2022_Tx" SG_ 1056 SelDrvMdePos11_B_Avail 1;
BA_ "U_CDX706_MY2023_Tx" SG_ 1056 SelDrvMdePos11_B_Avail 1;
BA_ "GenSigSendType" SG_ 1056 SelDrvMdePos10_B_Avail 3;
BA_ "U_CX727_MY2021_Tx" SG_ 1056 SelDrvMdePos10_B_Avail 1;
BA_ "U_P702_MY2021_Tx" SG_ 1056 SelDrvMdePos10_B_Avail 1;
BA_ "U_T6_MCA_MY2020_Tx" SG_ 1056 SelDrvMdePos10_B_Avail 1;
BA_ "U_CD542_MY2021_Tx" SG_ 1056 SelDrvMdePos10_B_Avail 1;
BA_ "U_U55X_MY2022_Tx" SG_ 1056 SelDrvMdePos10_B_Avail 1;
BA_ "U_CD764_MY2022_Tx" SG_ 1056 SelDrvMdePos10_B_Avail 1;
BA_ "U_CDX706_MY2023_Tx" SG_ 1056 SelDrvMdePos10_B_Avail 1;
BA_ "GenSigSendType" SG_ 1056 SelDrvMdePos09_B_Avail 3;
BA_ "U_CX727_MY2021_Tx" SG_ 1056 SelDrvMdePos09_B_Avail 1;
BA_ "U_P702_MY2021_Tx" SG_ 1056 SelDrvMdePos09_B_Avail 1;
BA_ "U_T6_MCA_MY2020_Tx" SG_ 1056 SelDrvMdePos09_B_Avail 1;
BA_ "U_CD542_MY2021_Tx" SG_ 1056 SelDrvMdePos09_B_Avail 1;
BA_ "U_U55X_MY2022_Tx" SG_ 1056 SelDrvMdePos09_B_Avail 1;
BA_ "U_CD764_MY2022_Tx" SG_ 1056 SelDrvMdePos09_B_Avail 1;
BA_ "U_CDX706_MY2023_Tx" SG_ 1056 SelDrvMdePos09_B_Avail 1;
BA_ "GenSigSendType" SG_ 1056 SelDrvMdePos08_B_Avail 3;
BA_ "U_CX727_MY2021_Tx" SG_ 1056 SelDrvMdePos08_B_Avail 1;
BA_ "U_P702_MY2021_Tx" SG_ 1056 SelDrvMdePos08_B_Avail 1;
BA_ "U_T6_MCA_MY2020_Tx" SG_ 1056 SelDrvMdePos08_B_Avail 1;
BA_ "U_CD542_MY2021_Tx" SG_ 1056 SelDrvMdePos08_B_Avail 1;
BA_ "U_U55X_MY2022_Tx" SG_ 1056 SelDrvMdePos08_B_Avail 1;
BA_ "U_CD764_MY2022_Tx" SG_ 1056 SelDrvMdePos08_B_Avail 1;
BA_ "U_CDX706_MY2023_Tx" SG_ 1056 SelDrvMdePos08_B_Avail 1;
BA_ "GenSigSendType" SG_ 1056 SelDrvMdePos07_B_Avail 3;
BA_ "U_CX727_MY2021_Tx" SG_ 1056 SelDrvMdePos07_B_Avail 1;
BA_ "U_P702_MY2021_Tx" SG_ 1056 SelDrvMdePos07_B_Avail 1;
BA_ "U_T6_MCA_MY2020_Tx" SG_ 1056 SelDrvMdePos07_B_Avail 1;
BA_ "U_CD542_MY2021_Tx" SG_ 1056 SelDrvMdePos07_B_Avail 1;
BA_ "U_U55X_MY2022_Tx" SG_ 1056 SelDrvMdePos07_B_Avail 1;
BA_ "U_CD764_MY2022_Tx" SG_ 1056 SelDrvMdePos07_B_Avail 1;
BA_ "U_CDX706_MY2023_Tx" SG_ 1056 SelDrvMdePos07_B_Avail 1;
BA_ "GenSigSendType" SG_ 1056 SelDrvMdePos06_B_Avail 3;
BA_ "U_CX727_MY2021_Tx" SG_ 1056 SelDrvMdePos06_B_Avail 1;
BA_ "U_P702_MY2021_Tx" SG_ 1056 SelDrvMdePos06_B_Avail 1;
BA_ "U_T6_MCA_MY2020_Tx" SG_ 1056 SelDrvMdePos06_B_Avail 1;
BA_ "U_CD542_MY2021_Tx" SG_ 1056 SelDrvMdePos06_B_Avail 1;
BA_ "U_U55X_MY2022_Tx" SG_ 1056 SelDrvMdePos06_B_Avail 1;
BA_ "U_CD764_MY2022_Tx" SG_ 1056 SelDrvMdePos06_B_Avail 1;
BA_ "U_CDX706_MY2023_Tx" SG_ 1056 SelDrvMdePos06_B_Avail 1;
BA_ "GenSigSendType" SG_ 1056 SelDrvMdePos05_B_Avail 3;
BA_ "U_CX727_MY2021_Tx" SG_ 1056 SelDrvMdePos05_B_Avail 1;
BA_ "U_P702_MY2021_Tx" SG_ 1056 SelDrvMdePos05_B_Avail 1;
BA_ "U_T6_MCA_MY2020_Tx" SG_ 1056 SelDrvMdePos05_B_Avail 1;
BA_ "U_CD542_MY2021_Tx" SG_ 1056 SelDrvMdePos05_B_Avail 1;
BA_ "U_U55X_MY2022_Tx" SG_ 1056 SelDrvMdePos05_B_Avail 1;
BA_ "U_CD764_MY2022_Tx" SG_ 1056 SelDrvMdePos05_B_Avail 1;
BA_ "U_CDX706_MY2023_Tx" SG_ 1056 SelDrvMdePos05_B_Avail 1;
BA_ "GenSigSendType" SG_ 1056 SelDrvMdePos04_B_Avail 3;
BA_ "U_CX727_MY2021_Tx" SG_ 1056 SelDrvMdePos04_B_Avail 1;
BA_ "U_P702_MY2021_Tx" SG_ 1056 SelDrvMdePos04_B_Avail 1;
BA_ "U_T6_MCA_MY2020_Tx" SG_ 1056 SelDrvMdePos04_B_Avail 1;
BA_ "U_CD542_MY2021_Tx" SG_ 1056 SelDrvMdePos04_B_Avail 1;
BA_ "U_U55X_MY2022_Tx" SG_ 1056 SelDrvMdePos04_B_Avail 1;
BA_ "U_CD764_MY2022_Tx" SG_ 1056 SelDrvMdePos04_B_Avail 1;
BA_ "U_CDX706_MY2023_Tx" SG_ 1056 SelDrvMdePos04_B_Avail 1;
BA_ "GenSigSendType" SG_ 1056 SelDrvMdePos03_B_Avail 3;
BA_ "U_CX727_MY2021_Tx" SG_ 1056 SelDrvMdePos03_B_Avail 1;
BA_ "U_P702_MY2021_Tx" SG_ 1056 SelDrvMdePos03_B_Avail 1;
BA_ "U_T6_MCA_MY2020_Tx" SG_ 1056 SelDrvMdePos03_B_Avail 1;
BA_ "U_CD542_MY2021_Tx" SG_ 1056 SelDrvMdePos03_B_Avail 1;
BA_ "U_U55X_MY2022_Tx" SG_ 1056 SelDrvMdePos03_B_Avail 1;
BA_ "U_CD764_MY2022_Tx" SG_ 1056 SelDrvMdePos03_B_Avail 1;
BA_ "U_CDX706_MY2023_Tx" SG_ 1056 SelDrvMdePos03_B_Avail 1;
BA_ "GenSigSendType" SG_ 1056 SelDrvMdePos02_B_Avail 3;
BA_ "U_CX727_MY2021_Tx" SG_ 1056 SelDrvMdePos02_B_Avail 1;
BA_ "U_P702_MY2021_Tx" SG_ 1056 SelDrvMdePos02_B_Avail 1;
BA_ "U_T6_MCA_MY2020_Tx" SG_ 1056 SelDrvMdePos02_B_Avail 1;
BA_ "U_CD542_MY2021_Tx" SG_ 1056 SelDrvMdePos02_B_Avail 1;
BA_ "U_U55X_MY2022_Tx" SG_ 1056 SelDrvMdePos02_B_Avail 1;
BA_ "U_CD764_MY2022_Tx" SG_ 1056 SelDrvMdePos02_B_Avail 1;
BA_ "U_CDX706_MY2023_Tx" SG_ 1056 SelDrvMdePos02_B_Avail 1;
BA_ "GenSigSendType" SG_ 1056 SelDrvMdePos01_B_Avail 3;
BA_ "U_CX727_MY2021_Tx" SG_ 1056 SelDrvMdePos01_B_Avail 1;
BA_ "U_P702_MY2021_Tx" SG_ 1056 SelDrvMdePos01_B_Avail 1;
BA_ "U_T6_MCA_MY2020_Tx" SG_ 1056 SelDrvMdePos01_B_Avail 1;
BA_ "U_CD542_MY2021_Tx" SG_ 1056 SelDrvMdePos01_B_Avail 1;
BA_ "U_U55X_MY2022_Tx" SG_ 1056 SelDrvMdePos01_B_Avail 1;
BA_ "U_CD764_MY2022_Tx" SG_ 1056 SelDrvMdePos01_B_Avail 1;
BA_ "U_CDX706_MY2023_Tx" SG_ 1056 SelDrvMdePos01_B_Avail 1;
BA_ "GenSigSendType" SG_ 1056 ActvDrvMde_D2_Stat 3;
BA_ "GenSigStartValueInteger" SG_ 1056 ActvDrvMde_D2_Stat 31;
BA_ "GenSigStartValue" SG_ 1056 ActvDrvMde_D2_Stat 31;
BA_ "U_T6_MCA_MY2020_Rx" SG_ 1056 ActvDrvMde_D2_Stat 1;
BA_ "ECGUsedRxSignal" SG_ 1056 ActvDrvMde_D2_Stat 1;
BA_ "U_CD542_MY2021_Rx" SG_ 1056 ActvDrvMde_D2_Stat 1;
BA_ "U_U55X_MY2022_Rx" SG_ 1056 ActvDrvMde_D2_Stat 1;
BA_ "U_CD764_MY2022_Rx" SG_ 1056 ActvDrvMde_D2_Stat 1;
BA_ "U_CDX706_MY2023_Rx" SG_ 1056 ActvDrvMde_D2_Stat 1;
BA_ "U_CX727_MY2021_Tx" SG_ 1056 ActvDrvMde_D2_Stat 1;
BA_ "U_P702_MY2021_Tx" SG_ 1056 ActvDrvMde_D2_Stat 1;
BA_ "U_T6_MCA_MY2020_Tx" SG_ 1056 ActvDrvMde_D2_Stat 1;
BA_ "U_CD542_MY2021_Tx" SG_ 1056 ActvDrvMde_D2_Stat 1;
BA_ "U_U55X_MY2022_Tx" SG_ 1056 ActvDrvMde_D2_Stat 1;
BA_ "U_CD764_MY2022_Tx" SG_ 1056 ActvDrvMde_D2_Stat 1;
BA_ "U_CDX706_MY2023_Tx" SG_ 1056 ActvDrvMde_D2_Stat 1;
BA_ "GenSigSendType" SG_ 1056 SelDrvMde_D2_Rq 3;
BA_ "GenSigStartValueInteger" SG_ 1056 SelDrvMde_D2_Rq 31;
BA_ "GenSigStartValue" SG_ 1056 SelDrvMde_D2_Rq 31;
BA_ "U_CX727_MY2021_Tx" SG_ 1056 SelDrvMde_D2_Rq 1;
BA_ "U_P702_MY2021_Tx" SG_ 1056 SelDrvMde_D2_Rq 1;
BA_ "U_T6_MCA_MY2020_Tx" SG_ 1056 SelDrvMde_D2_Rq 1;
BA_ "U_CD542_MY2021_Tx" SG_ 1056 SelDrvMde_D2_Rq 1;
BA_ "U_U55X_MY2022_Tx" SG_ 1056 SelDrvMde_D2_Rq 1;
BA_ "U_CD764_MY2022_Tx" SG_ 1056 SelDrvMde_D2_Rq 1;
BA_ "U_CDX706_MY2023_Tx" SG_ 1056 SelDrvMde_D2_Rq 1;
BA_ "GenSigSendType" SG_ 1056 SelDrvMdePt_D_Rq 3;
BA_ "U_CX727_MY2021_Rx" SG_ 1056 SelDrvMdePt_D_Rq 1;
BA_ "U_P702_MY2021_Rx" SG_ 1056 SelDrvMdePt_D_Rq 1;
BA_ "U_T6_MCA_MY2020_Rx" SG_ 1056 SelDrvMdePt_D_Rq 1;
BA_ "U_CD542_MY2021_Rx" SG_ 1056 SelDrvMdePt_D_Rq 1;
BA_ "U_U55X_MY2022_Rx" SG_ 1056 SelDrvMdePt_D_Rq 1;
BA_ "U_CD764_MY2022_Rx" SG_ 1056 SelDrvMdePt_D_Rq 1;
BA_ "U_CDX706_MY2023_Rx" SG_ 1056 SelDrvMdePt_D_Rq 1;
BA_ "U_CX727_MY2021_Tx" SG_ 1056 SelDrvMdePt_D_Rq 1;
BA_ "U_P702_MY2021_Tx" SG_ 1056 SelDrvMdePt_D_Rq 1;
BA_ "U_T6_MCA_MY2020_Tx" SG_ 1056 SelDrvMdePt_D_Rq 1;
BA_ "U_CD542_MY2021_Tx" SG_ 1056 SelDrvMdePt_D_Rq 1;
BA_ "U_U55X_MY2022_Tx" SG_ 1056 SelDrvMdePt_D_Rq 1;
BA_ "U_CD764_MY2022_Tx" SG_ 1056 SelDrvMdePt_D_Rq 1;
BA_ "U_CDX706_MY2023_Tx" SG_ 1056 SelDrvMdePt_D_Rq 1;
BA_ "GenSigSendType" SG_ 1056 SelDrvMdeMsgTxt_D_Rq 3;
BA_ "U_CX727_MY2021_Tx" SG_ 1056 SelDrvMdeMsgTxt_D_Rq 1;
BA_ "U_P702_MY2021_Tx" SG_ 1056 SelDrvMdeMsgTxt_D_Rq 1;
BA_ "U_T6_MCA_MY2020_Tx" SG_ 1056 SelDrvMdeMsgTxt_D_Rq 1;
BA_ "U_CD542_MY2021_Tx" SG_ 1056 SelDrvMdeMsgTxt_D_Rq 1;
BA_ "U_U55X_MY2022_Tx" SG_ 1056 SelDrvMdeMsgTxt_D_Rq 1;
BA_ "U_CD764_MY2022_Tx" SG_ 1056 SelDrvMdeMsgTxt_D_Rq 1;
BA_ "U_CDX706_MY2023_Tx" SG_ 1056 SelDrvMdeMsgTxt_D_Rq 1;
BA_ "GenSigSendType" SG_ 1056 SelDrvMde_D_Stat 3;
BA_ "U_CX727_MY2021_Tx" SG_ 1056 SelDrvMde_D_Stat 1;
BA_ "U_P702_MY2021_Tx" SG_ 1056 SelDrvMde_D_Stat 1;
BA_ "U_T6_MCA_MY2020_Tx" SG_ 1056 SelDrvMde_D_Stat 1;
BA_ "U_CD542_MY2021_Tx" SG_ 1056 SelDrvMde_D_Stat 1;
BA_ "U_U55X_MY2022_Tx" SG_ 1056 SelDrvMde_D_Stat 1;
BA_ "U_CD764_MY2022_Tx" SG_ 1056 SelDrvMde_D_Stat 1;
BA_ "U_CDX706_MY2023_Tx" SG_ 1056 SelDrvMde_D_Stat 1;
BA_ "GenSigSendType" SG_ 1056 AwdMde_D_RqBrk 3;
BA_ "GenSigStartValueInteger" SG_ 1056 AwdMde_D_RqBrk 5;
BA_ "GenSigStartValue" SG_ 1056 AwdMde_D_RqBrk 5;
BA_ "U_CX727_MY2021_Tx" SG_ 1056 AwdMde_D_RqBrk 1;
BA_ "U_P702_MY2021_Tx" SG_ 1056 AwdMde_D_RqBrk 1;
BA_ "U_T6_MCA_MY2020_Tx" SG_ 1056 AwdMde_D_RqBrk 1;
BA_ "U_U55X_MY2022_Tx" SG_ 1056 AwdMde_D_RqBrk 1;
BA_ "U_CDX706_MY2023_Tx" SG_ 1056 AwdMde_D_RqBrk 1;
BA_ "GenSigSendType" SG_ 1056 AutoEpbDsply_D_Stat 3;
BA_ "U_T6_MCA_MY2020_Tx" SG_ 1056 AutoEpbDsply_D_Stat 1;
BA_ "U_U55X_MY2022_Tx" SG_ 1056 AutoEpbDsply_D_Stat 1;
BA_ "GenSigSendType" SG_ 1056 SelDrvMdeMsgTxt2_D_Rq 3;
BA_ "U_T6_MCA_MY2020_Tx" SG_ 1056 SelDrvMdeMsgTxt2_D_Rq 1;
BA_ "U_CD542_MY2021_Tx" SG_ 1056 SelDrvMdeMsgTxt2_D_Rq 1;
BA_ "U_U55X_MY2022_Tx" SG_ 1056 SelDrvMdeMsgTxt2_D_Rq 1;
BA_ "U_CD764_MY2022_Tx" SG_ 1056 SelDrvMdeMsgTxt2_D_Rq 1;
BA_ "U_CDX706_MY2023_Tx" SG_ 1056 SelDrvMdeMsgTxt2_D_Rq 1;
BA_ "GenSigSendType" SG_ 1056 SelDrvMdeHmi03_D_Rq 3;
BA_ "U_T6_MCA_MY2020_Tx" SG_ 1056 SelDrvMdeHmi03_D_Rq 1;
BA_ "U_CD542_MY2021_Tx" SG_ 1056 SelDrvMdeHmi03_D_Rq 1;
BA_ "U_U55X_MY2022_Tx" SG_ 1056 SelDrvMdeHmi03_D_Rq 1;
BA_ "U_CD764_MY2022_Tx" SG_ 1056 SelDrvMdeHmi03_D_Rq 1;
BA_ "U_CDX706_MY2023_Tx" SG_ 1056 SelDrvMdeHmi03_D_Rq 1;
BA_ "GenSigSendType" SG_ 1054 RbaBrk_D_Stat 3;
BA_ "U_T6_MCA_MY2020_Rx" SG_ 1054 RbaBrk_D_Stat 1;
BA_ "U_CD542_MY2021_Rx" SG_ 1054 RbaBrk_D_Stat 1;
BA_ "U_U55X_MY2022_Rx" SG_ 1054 RbaBrk_D_Stat 1;
BA_ "U_CD764_MY2022_Rx" SG_ 1054 RbaBrk_D_Stat 1;
BA_ "U_CDX706_MY2023_Rx" SG_ 1054 RbaBrk_D_Stat 1;
BA_ "U_CX727_MY2021_Tx" SG_ 1054 RbaBrk_D_Stat 1;
BA_ "U_P702_MY2021_Tx" SG_ 1054 RbaBrk_D_Stat 1;
BA_ "U_T6_MCA_MY2020_Tx" SG_ 1054 RbaBrk_D_Stat 1;
BA_ "U_CD542_MY2021_Tx" SG_ 1054 RbaBrk_D_Stat 1;
BA_ "U_U55X_MY2022_Tx" SG_ 1054 RbaBrk_D_Stat 1;
BA_ "U_CD764_MY2022_Tx" SG_ 1054 RbaBrk_D_Stat 1;
BA_ "U_CDX706_MY2023_Tx" SG_ 1054 RbaBrk_D_Stat 1;
BA_ "GenSigSendType" SG_ 1054 SelDrvMdeChassis2_D_Rq 3;
BA_ "U_CX727_MY2021_Rx" SG_ 1054 SelDrvMdeChassis2_D_Rq 1;
BA_ "U_P702_MY2021_Rx" SG_ 1054 SelDrvMdeChassis2_D_Rq 1;
BA_ "U_T6_MCA_MY2020_Rx" SG_ 1054 SelDrvMdeChassis2_D_Rq 1;
BA_ "U_CD542_MY2021_Rx" SG_ 1054 SelDrvMdeChassis2_D_Rq 1;
BA_ "U_U55X_MY2022_Rx" SG_ 1054 SelDrvMdeChassis2_D_Rq 1;
BA_ "U_CD764_MY2022_Rx" SG_ 1054 SelDrvMdeChassis2_D_Rq 1;
BA_ "U_CDX706_MY2023_Rx" SG_ 1054 SelDrvMdeChassis2_D_Rq 1;
BA_ "U_P702_MY2021_Tx" SG_ 1054 SelDrvMdeChassis2_D_Rq 1;
BA_ "U_T6_MCA_MY2020_Tx" SG_ 1054 SelDrvMdeChassis2_D_Rq 1;
BA_ "U_CD542_MY2021_Tx" SG_ 1054 SelDrvMdeChassis2_D_Rq 1;
BA_ "U_U55X_MY2022_Tx" SG_ 1054 SelDrvMdeChassis2_D_Rq 1;
BA_ "U_CD764_MY2022_Tx" SG_ 1054 SelDrvMdeChassis2_D_Rq 1;
BA_ "U_CDX706_MY2023_Tx" SG_ 1054 SelDrvMdeChassis2_D_Rq 1;
BA_ "GenSigSendType" SG_ 1054 BrkBstrLoLampOn_B_Rq 3;
BA_ "U_CDX706_MY2023_Tx" SG_ 1054 BrkBstrLoLampOn_B_Rq 1;
BA_ "GenSigSendType" SG_ 1054 TrailCtl_D_Stat 3;
BA_ "U_P702_MY2021_Rx" SG_ 1054 TrailCtl_D_Stat 1;
BA_ "U_T6_MCA_MY2020_Rx" SG_ 1054 TrailCtl_D_Stat 1;
BA_ "U_U55X_MY2022_Rx" SG_ 1054 TrailCtl_D_Stat 1;
BA_ "U_CX727_MY2021_Tx" SG_ 1054 TrailCtl_D_Stat 1;
BA_ "U_P702_MY2021_Tx" SG_ 1054 TrailCtl_D_Stat 1;
BA_ "U_T6_MCA_MY2020_Tx" SG_ 1054 TrailCtl_D_Stat 1;
BA_ "U_U55X_MY2022_Tx" SG_ 1054 TrailCtl_D_Stat 1;
BA_ "U_CDX706_MY2023_Tx" SG_ 1054 TrailCtl_D_Stat 1;
BA_ "GenSigSendType" SG_ 1054 TrailCtlMsgTxt_D_Rq 3;
BA_ "U_CX727_MY2021_Tx" SG_ 1054 TrailCtlMsgTxt_D_Rq 1;
BA_ "U_P702_MY2021_Tx" SG_ 1054 TrailCtlMsgTxt_D_Rq 1;
BA_ "U_T6_MCA_MY2020_Tx" SG_ 1054 TrailCtlMsgTxt_D_Rq 1;
BA_ "U_U55X_MY2022_Tx" SG_ 1054 TrailCtlMsgTxt_D_Rq 1;
BA_ "U_CDX706_MY2023_Tx" SG_ 1054 TrailCtlMsgTxt_D_Rq 1;
BA_ "GenSigSendType" SG_ 1054 BrkPadMsgTxt_D_Rq 3;
BA_ "ECGUsedRxSignal" SG_ 1054 BrkPadMsgTxt_D_Rq 1;
BA_ "U_CD542_MY2021_Rx" SG_ 1054 BrkPadMsgTxt_D_Rq 1;
BA_ "U_U55X_MY2022_Rx" SG_ 1054 BrkPadMsgTxt_D_Rq 1;
BA_ "U_CD764_MY2022_Rx" SG_ 1054 BrkPadMsgTxt_D_Rq 1;
BA_ "U_CDX706_MY2023_Rx" SG_ 1054 BrkPadMsgTxt_D_Rq 1;
BA_ "U_CX727_MY2021_Tx" SG_ 1054 BrkPadMsgTxt_D_Rq 1;
BA_ "U_CDX706_MY2023_Tx" SG_ 1054 BrkPadMsgTxt_D_Rq 1;
BA_ "GenSigSendType" SG_ 1054 BrkBstrVac_D_Stat 3;
BA_ "U_P702_MY2021_Rx" SG_ 1054 BrkBstrVac_D_Stat 1;
BA_ "U_T6_MCA_MY2020_Rx" SG_ 1054 BrkBstrVac_D_Stat 1;
BA_ "U_CD542_MY2021_Rx" SG_ 1054 BrkBstrVac_D_Stat 1;
BA_ "U_U55X_MY2022_Rx" SG_ 1054 BrkBstrVac_D_Stat 1;
BA_ "U_CD764_MY2022_Rx" SG_ 1054 BrkBstrVac_D_Stat 1;
BA_ "U_CDX706_MY2023_Rx" SG_ 1054 BrkBstrVac_D_Stat 1;
BA_ "U_CX727_MY2021_Tx" SG_ 1054 BrkBstrVac_D_Stat 1;
BA_ "U_P702_MY2021_Tx" SG_ 1054 BrkBstrVac_D_Stat 1;
BA_ "U_T6_MCA_MY2020_Tx" SG_ 1054 BrkBstrVac_D_Stat 1;
BA_ "U_CD542_MY2021_Tx" SG_ 1054 BrkBstrVac_D_Stat 1;
BA_ "U_U55X_MY2022_Tx" SG_ 1054 BrkBstrVac_D_Stat 1;
BA_ "U_CD764_MY2022_Tx" SG_ 1054 BrkBstrVac_D_Stat 1;
BA_ "U_CDX706_MY2023_Tx" SG_ 1054 BrkBstrVac_D_Stat 1;
BA_ "GenSigSendType" SG_ 1054 DrvSlipCtlOffLamp_D_Rq 3;
BA_ "U_CX727_MY2021_Tx" SG_ 1054 DrvSlipCtlOffLamp_D_Rq 1;
BA_ "U_P702_MY2021_Tx" SG_ 1054 DrvSlipCtlOffLamp_D_Rq 1;
BA_ "U_T6_MCA_MY2020_Tx" SG_ 1054 DrvSlipCtlOffLamp_D_Rq 1;
BA_ "U_CD542_MY2021_Tx" SG_ 1054 DrvSlipCtlOffLamp_D_Rq 1;
BA_ "U_U55X_MY2022_Tx" SG_ 1054 DrvSlipCtlOffLamp_D_Rq 1;
BA_ "U_CD764_MY2022_Tx" SG_ 1054 DrvSlipCtlOffLamp_D_Rq 1;
BA_ "U_CDX706_MY2023_Tx" SG_ 1054 DrvSlipCtlOffLamp_D_Rq 1;
BA_ "GenSigSendType" SG_ 1054 DrvSlipCtlMdeMsg_D_Rq 3;
BA_ "U_T6_MCA_MY2020_Rx" SG_ 1054 DrvSlipCtlMdeMsg_D_Rq 1;
BA_ "ECGUsedRxSignal" SG_ 1054 DrvSlipCtlMdeMsg_D_Rq 1;
BA_ "U_CD542_MY2021_Rx" SG_ 1054 DrvSlipCtlMdeMsg_D_Rq 1;
BA_ "U_U55X_MY2022_Rx" SG_ 1054 DrvSlipCtlMdeMsg_D_Rq 1;
BA_ "U_CD764_MY2022_Rx" SG_ 1054 DrvSlipCtlMdeMsg_D_Rq 1;
BA_ "U_CDX706_MY2023_Rx" SG_ 1054 DrvSlipCtlMdeMsg_D_Rq 1;
BA_ "U_CX727_MY2021_Tx" SG_ 1054 DrvSlipCtlMdeMsg_D_Rq 1;
BA_ "U_P702_MY2021_Tx" SG_ 1054 DrvSlipCtlMdeMsg_D_Rq 1;
BA_ "U_T6_MCA_MY2020_Tx" SG_ 1054 DrvSlipCtlMdeMsg_D_Rq 1;
BA_ "U_CD542_MY2021_Tx" SG_ 1054 DrvSlipCtlMdeMsg_D_Rq 1;
BA_ "U_U55X_MY2022_Tx" SG_ 1054 DrvSlipCtlMdeMsg_D_Rq 1;
BA_ "U_CD764_MY2022_Tx" SG_ 1054 DrvSlipCtlMdeMsg_D_Rq 1;
BA_ "U_CDX706_MY2023_Tx" SG_ 1054 DrvSlipCtlMdeMsg_D_Rq 1;
BA_ "GenSigSendType" SG_ 1054 HdcOn_B_Ind 3;
BA_ "U_CX727_MY2021_Tx" SG_ 1054 HdcOn_B_Ind 1;
BA_ "U_T6_MCA_MY2020_Tx" SG_ 1054 HdcOn_B_Ind 1;
BA_ "U_U55X_MY2022_Tx" SG_ 1054 HdcOn_B_Ind 1;
BA_ "U_CDX706_MY2023_Tx" SG_ 1054 HdcOn_B_Ind 1;
BA_ "GenSigSendType" SG_ 1054 AutoHoldMsgTxt_D_Rq 3;
BA_ "U_CX727_MY2021_Tx" SG_ 1054 AutoHoldMsgTxt_D_Rq 1;
BA_ "U_P702_MY2021_Tx" SG_ 1054 AutoHoldMsgTxt_D_Rq 1;
BA_ "U_T6_MCA_MY2020_Tx" SG_ 1054 AutoHoldMsgTxt_D_Rq 1;
BA_ "U_CD542_MY2021_Tx" SG_ 1054 AutoHoldMsgTxt_D_Rq 1;
BA_ "U_U55X_MY2022_Tx" SG_ 1054 AutoHoldMsgTxt_D_Rq 1;
BA_ "U_CD764_MY2022_Tx" SG_ 1054 AutoHoldMsgTxt_D_Rq 1;
BA_ "U_CDX706_MY2023_Tx" SG_ 1054 AutoHoldMsgTxt_D_Rq 1;
BA_ "GenSigSendType" SG_ 1054 CtaBrk_D_Stat 3;
BA_ "U_T6_MCA_MY2020_Rx" SG_ 1054 CtaBrk_D_Stat 1;
BA_ "U_CD542_MY2021_Rx" SG_ 1054 CtaBrk_D_Stat 1;
BA_ "U_U55X_MY2022_Rx" SG_ 1054 CtaBrk_D_Stat 1;
BA_ "U_CD764_MY2022_Rx" SG_ 1054 CtaBrk_D_Stat 1;
BA_ "U_CDX706_MY2023_Rx" SG_ 1054 CtaBrk_D_Stat 1;
BA_ "U_CX727_MY2021_Tx" SG_ 1054 CtaBrk_D_Stat 1;
BA_ "U_P702_MY2021_Tx" SG_ 1054 CtaBrk_D_Stat 1;
BA_ "U_T6_MCA_MY2020_Tx" SG_ 1054 CtaBrk_D_Stat 1;
BA_ "U_CD542_MY2021_Tx" SG_ 1054 CtaBrk_D_Stat 1;
BA_ "U_U55X_MY2022_Tx" SG_ 1054 CtaBrk_D_Stat 1;
BA_ "U_CD764_MY2022_Tx" SG_ 1054 CtaBrk_D_Stat 1;
BA_ "U_CDX706_MY2023_Tx" SG_ 1054 CtaBrk_D_Stat 1;
BA_ "GenSigSendType" SG_ 1054 SelDrvMdeAwd_D_Rq 3;
BA_ "GenSigStartValueInteger" SG_ 1054 SelDrvMdeAwd_D_Rq 31;
BA_ "GenSigStartValue" SG_ 1054 SelDrvMdeAwd_D_Rq 31;
BA_ "U_P702_MY2021_Rx" SG_ 1054 SelDrvMdeAwd_D_Rq 1;
BA_ "U_T6_MCA_MY2020_Rx" SG_ 1054 SelDrvMdeAwd_D_Rq 1;
BA_ "U_U55X_MY2022_Rx" SG_ 1054 SelDrvMdeAwd_D_Rq 1;
BA_ "U_CDX706_MY2023_Rx" SG_ 1054 SelDrvMdeAwd_D_Rq 1;
BA_ "U_P702_MY2021_Tx" SG_ 1054 SelDrvMdeAwd_D_Rq 1;
BA_ "U_T6_MCA_MY2020_Tx" SG_ 1054 SelDrvMdeAwd_D_Rq 1;
BA_ "U_CD542_MY2021_Tx" SG_ 1054 SelDrvMdeAwd_D_Rq 1;
BA_ "U_U55X_MY2022_Tx" SG_ 1054 SelDrvMdeAwd_D_Rq 1;
BA_ "U_CD764_MY2022_Tx" SG_ 1054 SelDrvMdeAwd_D_Rq 1;
BA_ "U_CDX706_MY2023_Tx" SG_ 1054 SelDrvMdeAwd_D_Rq 1;
BA_ "GenSigSendType" SG_ 1054 AutoHoldSwMde_B_Ind 3;
BA_ "ContentDependant" SG_ 1054 AutoHoldSwMde_B_Ind 1;
BA_ "U_CX727_MY2021_Tx" SG_ 1054 AutoHoldSwMde_B_Ind 1;
BA_ "U_P702_MY2021_Tx" SG_ 1054 AutoHoldSwMde_B_Ind 1;
BA_ "U_T6_MCA_MY2020_Tx" SG_ 1054 AutoHoldSwMde_B_Ind 1;
BA_ "U_CD542_MY2021_Tx" SG_ 1054 AutoHoldSwMde_B_Ind 1;
BA_ "U_U55X_MY2022_Tx" SG_ 1054 AutoHoldSwMde_B_Ind 1;
BA_ "U_CD764_MY2022_Tx" SG_ 1054 AutoHoldSwMde_B_Ind 1;
BA_ "U_CDX706_MY2023_Tx" SG_ 1054 AutoHoldSwMde_B_Ind 1;
BA_ "GenSigSendType" SG_ 1054 AutoHoldMde_D_Ind 3;
BA_ "U_CX727_MY2021_Tx" SG_ 1054 AutoHoldMde_D_Ind 1;
BA_ "U_P702_MY2021_Tx" SG_ 1054 AutoHoldMde_D_Ind 1;
BA_ "U_T6_MCA_MY2020_Tx" SG_ 1054 AutoHoldMde_D_Ind 1;
BA_ "U_CD542_MY2021_Tx" SG_ 1054 AutoHoldMde_D_Ind 1;
BA_ "U_U55X_MY2022_Tx" SG_ 1054 AutoHoldMde_D_Ind 1;
BA_ "U_CD764_MY2022_Tx" SG_ 1054 AutoHoldMde_D_Ind 1;
BA_ "U_CDX706_MY2023_Tx" SG_ 1054 AutoHoldMde_D_Ind 1;
BA_ "GenSigSendType" SG_ 1054 BrkMdeInhbt_B_RqDsply 3;
BA_ "WakeupSignal" SG_ 1054 BrkMdeInhbt_B_RqDsply 1;
BA_ "U_P702_MY2021_Tx" SG_ 1054 BrkMdeInhbt_B_RqDsply 1;
BA_ "GenSigSendType" SG_ 1054 BrkLineLck_D_Stat 3;
BA_ "GenSigStartValueInteger" SG_ 1054 BrkLineLck_D_Stat 4;
BA_ "GenSigStartValue" SG_ 1054 BrkLineLck_D_Stat 4;
BA_ "GenSigSendType" SG_ 1054 SelDrvMdeChassis_D_Rq 3;
BA_ "U_T6_MCA_MY2020_Rx" SG_ 1054 SelDrvMdeChassis_D_Rq 1;
BA_ "U_U55X_MY2022_Rx" SG_ 1054 SelDrvMdeChassis_D_Rq 1;
BA_ "U_CX727_MY2021_Tx" SG_ 1054 SelDrvMdeChassis_D_Rq 1;
BA_ "U_P702_MY2021_Tx" SG_ 1054 SelDrvMdeChassis_D_Rq 1;
BA_ "U_T6_MCA_MY2020_Tx" SG_ 1054 SelDrvMdeChassis_D_Rq 1;
BA_ "U_CD542_MY2021_Tx" SG_ 1054 SelDrvMdeChassis_D_Rq 1;
BA_ "U_U55X_MY2022_Tx" SG_ 1054 SelDrvMdeChassis_D_Rq 1;
BA_ "U_CD764_MY2022_Tx" SG_ 1054 SelDrvMdeChassis_D_Rq 1;
BA_ "U_CDX706_MY2023_Tx" SG_ 1054 SelDrvMdeChassis_D_Rq 1;
BA_ "GenSigSendType" SG_ 1054 ApaBrk_D_Stat 3;
BA_ "U_CX727_MY2021_Rx" SG_ 1054 ApaBrk_D_Stat 1;
BA_ "U_P702_MY2021_Rx" SG_ 1054 ApaBrk_D_Stat 1;
BA_ "U_T6_MCA_MY2020_Rx" SG_ 1054 ApaBrk_D_Stat 1;
BA_ "U_CD542_MY2021_Rx" SG_ 1054 ApaBrk_D_Stat 1;
BA_ "U_U55X_MY2022_Rx" SG_ 1054 ApaBrk_D_Stat 1;
BA_ "U_CD764_MY2022_Rx" SG_ 1054 ApaBrk_D_Stat 1;
BA_ "U_CDX706_MY2023_Rx" SG_ 1054 ApaBrk_D_Stat 1;
BA_ "U_CX727_MY2021_Tx" SG_ 1054 ApaBrk_D_Stat 1;
BA_ "U_P702_MY2021_Tx" SG_ 1054 ApaBrk_D_Stat 1;
BA_ "U_T6_MCA_MY2020_Tx" SG_ 1054 ApaBrk_D_Stat 1;
BA_ "U_CD542_MY2021_Tx" SG_ 1054 ApaBrk_D_Stat 1;
BA_ "U_U55X_MY2022_Tx" SG_ 1054 ApaBrk_D_Stat 1;
BA_ "U_CD764_MY2022_Tx" SG_ 1054 ApaBrk_D_Stat 1;
BA_ "U_CDX706_MY2023_Tx" SG_ 1054 ApaBrk_D_Stat 1;
BA_ "GenSigSendType" SG_ 1054 SelDrvMdeChassis3_D_Rq 3;
BA_ "U_T6_MCA_MY2020_Rx" SG_ 1054 SelDrvMdeChassis3_D_Rq 1;
BA_ "U_T6_MCA_MY2020_Tx" SG_ 1054 SelDrvMdeChassis3_D_Rq 1;
BA_ "U_CDX706_MY2023_Tx" SG_ 1054 SelDrvMdeChassis3_D_Rq 1;
BA_ "GenSigSendType" SG_ 1054 TrailOnePdlTqLm_B_Actl 3;
BA_ "U_T6_MCA_MY2020_Rx" SG_ 1054 TrailOnePdlTqLm_B_Actl 1;
BA_ "U_T6_MCA_MY2020_Tx" SG_ 1054 TrailOnePdlTqLm_B_Actl 1;
BA_ "U_CDX706_MY2023_Tx" SG_ 1054 TrailOnePdlTqLm_B_Actl 1;
BA_ "GenSigSendType" SG_ 1054 OnePdlDrvDeny_B_Stat 3;
BA_ "U_T6_MCA_MY2020_Rx" SG_ 1054 OnePdlDrvDeny_B_Stat 1;
BA_ "U_T6_MCA_MY2020_Tx" SG_ 1054 OnePdlDrvDeny_B_Stat 1;
BA_ "U_CD542_MY2021_Tx" SG_ 1054 OnePdlDrvDeny_B_Stat 1;
BA_ "U_CD764_MY2022_Tx" SG_ 1054 OnePdlDrvDeny_B_Stat 1;
BA_ "U_CDX706_MY2023_Tx" SG_ 1054 OnePdlDrvDeny_B_Stat 1;
BA_ "GenSigSendType" SG_ 1054 BrkDrvMde_D_Stat 3;
BA_ "U_CX727_MY2021_Tx" SG_ 1054 BrkDrvMde_D_Stat 1;
BA_ "GenSigSendType" SG_ 1054 AirDamUp_B_RqBrk 3;
BA_ "U_P702_MY2021_Rx" SG_ 1054 AirDamUp_B_RqBrk 1;
BA_ "U_T6_MCA_MY2020_Rx" SG_ 1054 AirDamUp_B_RqBrk 1;
BA_ "U_P702_MY2021_Tx" SG_ 1054 AirDamUp_B_RqBrk 1;
BA_ "U_U55X_MY2022_Tx" SG_ 1054 AirDamUp_B_RqBrk 1;
BA_ "GenSigSendType" SG_ 1054 FrontDiffElckrOpen_B_Rq 3;
BA_ "U_T6_MCA_MY2020_Rx" SG_ 1054 FrontDiffElckrOpen_B_Rq 1;
BA_ "U_T6_MCA_MY2020_Tx" SG_ 1054 FrontDiffElckrOpen_B_Rq 1;
BA_ "U_CDX706_MY2023_Tx" SG_ 1054 FrontDiffElckrOpen_B_Rq 1;
BA_ "U_T6_MCA_MY2020_Tx" SG_ 1046 ReserveTracCtlPtActv 1;
BA_ "GenSigStartValueInteger" SG_ 1046 HsaMde_D_Mem 1;
BA_ "GenSigStartValue" SG_ 1046 HsaMde_D_Mem 1;
BA_ "U_CX727_MY2021_Tx" SG_ 1046 HsaMde_D_Mem 1;
BA_ "U_P702_MY2021_Tx" SG_ 1046 HsaMde_D_Mem 1;
BA_ "U_T6_MCA_MY2020_Tx" SG_ 1046 HsaMde_D_Mem 1;
BA_ "U_CD542_MY2021_Tx" SG_ 1046 HsaMde_D_Mem 1;
BA_ "U_U55X_MY2022_Tx" SG_ 1046 HsaMde_D_Mem 1;
BA_ "U_CD764_MY2022_Tx" SG_ 1046 HsaMde_D_Mem 1;
BA_ "U_CDX706_MY2023_Tx" SG_ 1046 HsaMde_D_Mem 1;
BA_ "U_P702_MY2021_Rx" SG_ 1046 BrkBstrVac_B_Rq 1;
BA_ "U_T6_MCA_MY2020_Rx" SG_ 1046 BrkBstrVac_B_Rq 1;
BA_ "U_CD542_MY2021_Rx" SG_ 1046 BrkBstrVac_B_Rq 1;
BA_ "U_U55X_MY2022_Rx" SG_ 1046 BrkBstrVac_B_Rq 1;
BA_ "U_CD764_MY2022_Rx" SG_ 1046 BrkBstrVac_B_Rq 1;
BA_ "U_CDX706_MY2023_Rx" SG_ 1046 BrkBstrVac_B_Rq 1;
BA_ "U_CX727_MY2021_Tx" SG_ 1046 BrkBstrVac_B_Rq 1;
BA_ "U_P702_MY2021_Tx" SG_ 1046 BrkBstrVac_B_Rq 1;
BA_ "U_T6_MCA_MY2020_Tx" SG_ 1046 BrkBstrVac_B_Rq 1;
BA_ "U_CD542_MY2021_Tx" SG_ 1046 BrkBstrVac_B_Rq 1;
BA_ "U_U55X_MY2022_Tx" SG_ 1046 BrkBstrVac_B_Rq 1;
BA_ "U_CD764_MY2022_Tx" SG_ 1046 BrkBstrVac_B_Rq 1;
BA_ "U_CDX706_MY2023_Tx" SG_ 1046 BrkBstrVac_B_Rq 1;
BA_ "U_T6_MCA_MY2020_Rx" SG_ 1046 HdcMde_D_Actl 1;
BA_ "U_CDX706_MY2023_Rx" SG_ 1046 HdcMde_D_Actl 1;
BA_ "U_CX727_MY2021_Tx" SG_ 1046 HdcMde_D_Actl 1;
BA_ "U_P702_MY2021_Tx" SG_ 1046 HdcMde_D_Actl 1;
BA_ "U_T6_MCA_MY2020_Tx" SG_ 1046 HdcMde_D_Actl 1;
BA_ "U_U55X_MY2022_Tx" SG_ 1046 HdcMde_D_Actl 1;
BA_ "U_CDX706_MY2023_Tx" SG_ 1046 HdcMde_D_Actl 1;
BA_ "GenSigStartValueInteger" SG_ 1046 RearDiffLck_Tq2_RqMx 4094;
BA_ "GenSigStartValue" SG_ 1046 RearDiffLck_Tq2_RqMx 4094;
BA_ "U_T6_MCA_MY2020_Rx" SG_ 1046 RearDiffLck_Tq2_RqMx 1;
BA_ "U_U55X_MY2022_Rx" SG_ 1046 RearDiffLck_Tq2_RqMx 1;
BA_ "U_CX727_MY2021_Tx" SG_ 1046 RearDiffLck_Tq2_RqMx 1;
BA_ "U_P702_MY2021_Tx" SG_ 1046 RearDiffLck_Tq2_RqMx 1;
BA_ "U_T6_MCA_MY2020_Tx" SG_ 1046 RearDiffLck_Tq2_RqMx 1;
BA_ "U_CD542_MY2021_Tx" SG_ 1046 RearDiffLck_Tq2_RqMx 1;
BA_ "U_U55X_MY2022_Tx" SG_ 1046 RearDiffLck_Tq2_RqMx 1;
BA_ "U_CD764_MY2022_Tx" SG_ 1046 RearDiffLck_Tq2_RqMx 1;
BA_ "U_CDX706_MY2023_Tx" SG_ 1046 RearDiffLck_Tq2_RqMx 1;
BA_ "U_T6_MCA_MY2020_Rx" SG_ 1046 TRLR_SWAY_EVNT_IN_PROG 1;
BA_ "ECGUsedRxSignal" SG_ 1046 TRLR_SWAY_EVNT_IN_PROG 1;
BA_ "U_CD542_MY2021_Rx" SG_ 1046 TRLR_SWAY_EVNT_IN_PROG 1;
BA_ "U_CD764_MY2022_Rx" SG_ 1046 TRLR_SWAY_EVNT_IN_PROG 1;
BA_ "U_CDX706_MY2023_Rx" SG_ 1046 TRLR_SWAY_EVNT_IN_PROG 1;
BA_ "U_CX727_MY2021_Tx" SG_ 1046 TRLR_SWAY_EVNT_IN_PROG 1;
BA_ "U_P702_MY2021_Tx" SG_ 1046 TRLR_SWAY_EVNT_IN_PROG 1;
BA_ "U_T6_MCA_MY2020_Tx" SG_ 1046 TRLR_SWAY_EVNT_IN_PROG 1;
BA_ "U_CD542_MY2021_Tx" SG_ 1046 TRLR_SWAY_EVNT_IN_PROG 1;
BA_ "U_U55X_MY2022_Tx" SG_ 1046 TRLR_SWAY_EVNT_IN_PROG 1;
BA_ "U_CD764_MY2022_Tx" SG_ 1046 TRLR_SWAY_EVNT_IN_PROG 1;
BA_ "U_CX727_MY2021_Tx" SG_ 1046 TRLR_SWAY_CONFIG_STAT 1;
BA_ "U_P702_MY2021_Tx" SG_ 1046 TRLR_SWAY_CONFIG_STAT 1;
BA_ "U_T6_MCA_MY2020_Tx" SG_ 1046 TRLR_SWAY_CONFIG_STAT 1;
BA_ "U_CD542_MY2021_Tx" SG_ 1046 TRLR_SWAY_CONFIG_STAT 1;
BA_ "U_U55X_MY2022_Tx" SG_ 1046 TRLR_SWAY_CONFIG_STAT 1;
BA_ "U_CD764_MY2022_Tx" SG_ 1046 TRLR_SWAY_CONFIG_STAT 1;
BA_ "U_CDX706_MY2023_Tx" SG_ 1046 TRLR_SWAY_CONFIG_STAT 1;
BA_ "ContentDependant" SG_ 1046 TCMode 1;
BA_ "U_CX727_MY2021_Rx" SG_ 1046 TCMode 1;
BA_ "U_P702_MY2021_Rx" SG_ 1046 TCMode 1;
BA_ "U_T6_MCA_MY2020_Rx" SG_ 1046 TCMode 1;
BA_ "ECGUsedRxSignal" SG_ 1046 TCMode 1;
BA_ "U_CD542_MY2021_Rx" SG_ 1046 TCMode 1;
BA_ "U_U55X_MY2022_Rx" SG_ 1046 TCMode 1;
BA_ "U_CD764_MY2022_Rx" SG_ 1046 TCMode 1;
BA_ "U_CDX706_MY2023_Rx" SG_ 1046 TCMode 1;
BA_ "U_CX727_MY2021_Tx" SG_ 1046 TCMode 1;
BA_ "U_P702_MY2021_Tx" SG_ 1046 TCMode 1;
BA_ "U_T6_MCA_MY2020_Tx" SG_ 1046 TCMode 1;
BA_ "U_CD542_MY2021_Tx" SG_ 1046 TCMode 1;
BA_ "U_U55X_MY2022_Tx" SG_ 1046 TCMode 1;
BA_ "U_CD764_MY2022_Tx" SG_ 1046 TCMode 1;
BA_ "U_CDX706_MY2023_Tx" SG_ 1046 TCMode 1;
BA_ "U_CX727_MY2021_Rx" SG_ 1046 DrvSlipCtlLamp_D_Rq 1;
BA_ "U_P702_MY2021_Rx" SG_ 1046 DrvSlipCtlLamp_D_Rq 1;
BA_ "U_T6_MCA_MY2020_Rx" SG_ 1046 DrvSlipCtlLamp_D_Rq 1;
BA_ "U_CD542_MY2021_Rx" SG_ 1046 DrvSlipCtlLamp_D_Rq 1;
BA_ "U_U55X_MY2022_Rx" SG_ 1046 DrvSlipCtlLamp_D_Rq 1;
BA_ "U_CD764_MY2022_Rx" SG_ 1046 DrvSlipCtlLamp_D_Rq 1;
BA_ "U_CDX706_MY2023_Rx" SG_ 1046 DrvSlipCtlLamp_D_Rq 1;
BA_ "U_CX727_MY2021_Tx" SG_ 1046 DrvSlipCtlLamp_D_Rq 1;
BA_ "U_P702_MY2021_Tx" SG_ 1046 DrvSlipCtlLamp_D_Rq 1;
BA_ "U_T6_MCA_MY2020_Tx" SG_ 1046 DrvSlipCtlLamp_D_Rq 1;
BA_ "U_CD542_MY2021_Tx" SG_ 1046 DrvSlipCtlLamp_D_Rq 1;
BA_ "U_U55X_MY2022_Tx" SG_ 1046 DrvSlipCtlLamp_D_Rq 1;
BA_ "U_CD764_MY2022_Tx" SG_ 1046 DrvSlipCtlLamp_D_Rq 1;
BA_ "U_CDX706_MY2023_Tx" SG_ 1046 DrvSlipCtlLamp_D_Rq 1;
BA_ "U_CX727_MY2021_Rx" SG_ 1046 Abs_B_Falt 1;
BA_ "U_P702_MY2021_Rx" SG_ 1046 Abs_B_Falt 1;
BA_ "U_T6_MCA_MY2020_Rx" SG_ 1046 Abs_B_Falt 1;
BA_ "ECGUsedRxSignal" SG_ 1046 Abs_B_Falt 1;
BA_ "U_CD542_MY2021_Rx" SG_ 1046 Abs_B_Falt 1;
BA_ "U_U55X_MY2022_Rx" SG_ 1046 Abs_B_Falt 1;
BA_ "U_CD764_MY2022_Rx" SG_ 1046 Abs_B_Falt 1;
BA_ "U_CDX706_MY2023_Rx" SG_ 1046 Abs_B_Falt 1;
BA_ "U_CX727_MY2021_Tx" SG_ 1046 Abs_B_Falt 1;
BA_ "U_P702_MY2021_Tx" SG_ 1046 Abs_B_Falt 1;
BA_ "U_T6_MCA_MY2020_Tx" SG_ 1046 Abs_B_Falt 1;
BA_ "U_CD542_MY2021_Tx" SG_ 1046 Abs_B_Falt 1;
BA_ "U_U55X_MY2022_Tx" SG_ 1046 Abs_B_Falt 1;
BA_ "U_CD764_MY2022_Tx" SG_ 1046 Abs_B_Falt 1;
BA_ "U_CDX706_MY2023_Tx" SG_ 1046 Abs_B_Falt 1;
BA_ "U_CX727_MY2021_Rx" SG_ 1046 DrvSlipCtlMde_D_Ind 1;
BA_ "U_P702_MY2021_Rx" SG_ 1046 DrvSlipCtlMde_D_Ind 1;
BA_ "U_T6_MCA_MY2020_Rx" SG_ 1046 DrvSlipCtlMde_D_Ind 1;
BA_ "ECGUsedRxSignal" SG_ 1046 DrvSlipCtlMde_D_Ind 1;
BA_ "U_CD542_MY2021_Rx" SG_ 1046 DrvSlipCtlMde_D_Ind 1;
BA_ "U_U55X_MY2022_Rx" SG_ 1046 DrvSlipCtlMde_D_Ind 1;
BA_ "U_CD764_MY2022_Rx" SG_ 1046 DrvSlipCtlMde_D_Ind 1;
BA_ "U_CDX706_MY2023_Rx" SG_ 1046 DrvSlipCtlMde_D_Ind 1;
BA_ "U_CX727_MY2021_Tx" SG_ 1046 DrvSlipCtlMde_D_Ind 1;
BA_ "U_P702_MY2021_Tx" SG_ 1046 DrvSlipCtlMde_D_Ind 1;
BA_ "U_T6_MCA_MY2020_Tx" SG_ 1046 DrvSlipCtlMde_D_Ind 1;
BA_ "U_CD542_MY2021_Tx" SG_ 1046 DrvSlipCtlMde_D_Ind 1;
BA_ "U_U55X_MY2022_Tx" SG_ 1046 DrvSlipCtlMde_D_Ind 1;
BA_ "U_CD764_MY2022_Tx" SG_ 1046 DrvSlipCtlMde_D_Ind 1;
BA_ "U_CDX706_MY2023_Tx" SG_ 1046 DrvSlipCtlMde_D_Ind 1;
BA_ "U_P702_MY2021_Rx" SG_ 1046 DrvAntiLckLamp_D_Rq 1;
BA_ "U_T6_MCA_MY2020_Rx" SG_ 1046 DrvAntiLckLamp_D_Rq 1;
BA_ "U_CD542_MY2021_Rx" SG_ 1046 DrvAntiLckLamp_D_Rq 1;
BA_ "U_U55X_MY2022_Rx" SG_ 1046 DrvAntiLckLamp_D_Rq 1;
BA_ "U_CD764_MY2022_Rx" SG_ 1046 DrvAntiLckLamp_D_Rq 1;
BA_ "U_CDX706_MY2023_Rx" SG_ 1046 DrvAntiLckLamp_D_Rq 1;
BA_ "U_CX727_MY2021_Tx" SG_ 1046 DrvAntiLckLamp_D_Rq 1;
BA_ "U_P702_MY2021_Tx" SG_ 1046 DrvAntiLckLamp_D_Rq 1;
BA_ "U_T6_MCA_MY2020_Tx" SG_ 1046 DrvAntiLckLamp_D_Rq 1;
BA_ "U_CD542_MY2021_Tx" SG_ 1046 DrvAntiLckLamp_D_Rq 1;
BA_ "U_U55X_MY2022_Tx" SG_ 1046 DrvAntiLckLamp_D_Rq 1;
BA_ "U_CD764_MY2022_Tx" SG_ 1046 DrvAntiLckLamp_D_Rq 1;
BA_ "U_CDX706_MY2023_Tx" SG_ 1046 DrvAntiLckLamp_D_Rq 1;
BA_ "MetaData" SG_ 1046 BpedMove_No_Cnt 1;
BA_ "U_CX727_MY2021_Rx" SG_ 1046 BpedMove_No_Cnt 1;
BA_ "U_P702_MY2021_Rx" SG_ 1046 BpedMove_No_Cnt 1;
BA_ "U_CD542_MY2021_Rx" SG_ 1046 BpedMove_No_Cnt 1;
BA_ "U_CDX706_MY2023_Rx" SG_ 1046 BpedMove_No_Cnt 1;
BA_ "U_CX727_MY2021_Tx" SG_ 1046 BpedMove_No_Cnt 1;
BA_ "U_P702_MY2021_Tx" SG_ 1046 BpedMove_No_Cnt 1;
BA_ "U_T6_MCA_MY2020_Tx" SG_ 1046 BpedMove_No_Cnt 1;
BA_ "U_CD542_MY2021_Tx" SG_ 1046 BpedMove_No_Cnt 1;
BA_ "U_U55X_MY2022_Tx" SG_ 1046 BpedMove_No_Cnt 1;
BA_ "U_CD764_MY2022_Tx" SG_ 1046 BpedMove_No_Cnt 1;
BA_ "U_CDX706_MY2023_Tx" SG_ 1046 BpedMove_No_Cnt 1;
BA_ "GenSigStartValueInteger" SG_ 1046 StabCtlBrk_B_Avail 1;
BA_ "GenSigStartValue" SG_ 1046 StabCtlBrk_B_Avail 1;
BA_ "U_T6_MCA_MY2020_Rx" SG_ 1046 StabCtlBrk_B_Avail 1;
BA_ "U_U55X_MY2022_Rx" SG_ 1046 StabCtlBrk_B_Avail 1;
BA_ "U_CX727_MY2021_Tx" SG_ 1046 StabCtlBrk_B_Avail 1;
BA_ "U_P702_MY2021_Tx" SG_ 1046 StabCtlBrk_B_Avail 1;
BA_ "U_T6_MCA_MY2020_Tx" SG_ 1046 StabCtlBrk_B_Avail 1;
BA_ "U_CD542_MY2021_Tx" SG_ 1046 StabCtlBrk_B_Avail 1;
BA_ "U_U55X_MY2022_Tx" SG_ 1046 StabCtlBrk_B_Avail 1;
BA_ "U_CD764_MY2022_Tx" SG_ 1046 StabCtlBrk_B_Avail 1;
BA_ "U_CDX706_MY2023_Tx" SG_ 1046 StabCtlBrk_B_Avail 1;
BA_ "U_CX727_MY2021_Tx" SG_ 1046 DrvHdcWarnInfo_D_Rq 1;
BA_ "U_P702_MY2021_Tx" SG_ 1046 DrvHdcWarnInfo_D_Rq 1;
BA_ "U_T6_MCA_MY2020_Tx" SG_ 1046 DrvHdcWarnInfo_D_Rq 1;
BA_ "U_U55X_MY2022_Tx" SG_ 1046 DrvHdcWarnInfo_D_Rq 1;
BA_ "U_CX727_MY2021_Tx" SG_ 1046 DrvHdcMsg_D_Rq 1;
BA_ "U_P702_MY2021_Tx" SG_ 1046 DrvHdcMsg_D_Rq 1;
BA_ "U_T6_MCA_MY2020_Tx" SG_ 1046 DrvHdcMsg_D_Rq 1;
BA_ "U_U55X_MY2022_Tx" SG_ 1046 DrvHdcMsg_D_Rq 1;
BA_ "U_CX727_MY2021_Tx" SG_ 1046 DrvHdcLampInfo_D_Rq 1;
BA_ "U_P702_MY2021_Tx" SG_ 1046 DrvHdcLampInfo_D_Rq 1;
BA_ "U_T6_MCA_MY2020_Tx" SG_ 1046 DrvHdcLampInfo_D_Rq 1;
BA_ "U_U55X_MY2022_Tx" SG_ 1046 DrvHdcLampInfo_D_Rq 1;
BA_ "U_CD764_MY2022_Tx" SG_ 1046 DrvHdcLampInfo_D_Rq 1;
BA_ "GenSigStartValueInteger" SG_ 1046 BpedMove_D_Actl 3;
BA_ "GenSigStartValue" SG_ 1046 BpedMove_D_Actl 3;
BA_ "U_CX727_MY2021_Rx" SG_ 1046 BpedMove_D_Actl 1;
BA_ "U_P702_MY2021_Rx" SG_ 1046 BpedMove_D_Actl 1;
BA_ "U_T6_MCA_MY2020_Rx" SG_ 1046 BpedMove_D_Actl 1;
BA_ "U_CD542_MY2021_Rx" SG_ 1046 BpedMove_D_Actl 1;
BA_ "U_CDX706_MY2023_Rx" SG_ 1046 BpedMove_D_Actl 1;
BA_ "U_CX727_MY2021_Tx" SG_ 1046 BpedMove_D_Actl 1;
BA_ "U_P702_MY2021_Tx" SG_ 1046 BpedMove_D_Actl 1;
BA_ "U_T6_MCA_MY2020_Tx" SG_ 1046 BpedMove_D_Actl 1;
BA_ "U_CD542_MY2021_Tx" SG_ 1046 BpedMove_D_Actl 1;
BA_ "U_U55X_MY2022_Tx" SG_ 1046 BpedMove_D_Actl 1;
BA_ "U_CD764_MY2022_Tx" SG_ 1046 BpedMove_D_Actl 1;
BA_ "U_CDX706_MY2023_Tx" SG_ 1046 BpedMove_D_Actl 1;
BA_ "U_CX727_MY2021_Tx" SG_ 1046 ChimeBrk_B_Rq 1;
BA_ "U_P702_MY2021_Tx" SG_ 1046 ChimeBrk_B_Rq 1;
BA_ "U_T6_MCA_MY2020_Tx" SG_ 1046 ChimeBrk_B_Rq 1;
BA_ "U_CD542_MY2021_Tx" SG_ 1046 ChimeBrk_B_Rq 1;
BA_ "U_U55X_MY2022_Tx" SG_ 1046 ChimeBrk_B_Rq 1;
BA_ "U_CD764_MY2022_Tx" SG_ 1046 ChimeBrk_B_Rq 1;
BA_ "U_CDX706_MY2023_Tx" SG_ 1046 ChimeBrk_B_Rq 1;
BA_ "U_CX727_MY2021_Tx" SG_ 1046 BrkLamp_B_Rq 1;
BA_ "U_P702_MY2021_Tx" SG_ 1046 BrkLamp_B_Rq 1;
BA_ "U_T6_MCA_MY2020_Tx" SG_ 1046 BrkLamp_B_Rq 1;
BA_ "U_CD542_MY2021_Tx" SG_ 1046 BrkLamp_B_Rq 1;
BA_ "U_U55X_MY2022_Tx" SG_ 1046 BrkLamp_B_Rq 1;
BA_ "U_CD764_MY2022_Tx" SG_ 1046 BrkLamp_B_Rq 1;
BA_ "U_CDX706_MY2023_Tx" SG_ 1046 BrkLamp_B_Rq 1;
BA_ "U_CX727_MY2021_Tx" SG_ 1046 HILL_DESC_MC 1;
BA_ "U_P702_MY2021_Tx" SG_ 1046 HILL_DESC_MC 1;
BA_ "U_T6_MCA_MY2020_Tx" SG_ 1046 HILL_DESC_MC 1;
BA_ "U_U55X_MY2022_Tx" SG_ 1046 HILL_DESC_MC 1;
BA_ "U_CDX706_MY2023_Tx" SG_ 1046 HILL_DESC_MC 1;
BA_ "MetaData" SG_ 1046 BpedDiffLckTq_No_Cs 1;
BA_ "U_CDX706_MY2023_Rx" SG_ 1046 BpedDiffLckTq_No_Cs 1;
BA_ "U_CX727_MY2021_Tx" SG_ 1046 BpedDiffLckTq_No_Cs 1;
BA_ "U_CD542_MY2021_Tx" SG_ 1046 BpedDiffLckTq_No_Cs 1;
BA_ "U_CD764_MY2022_Tx" SG_ 1046 BpedDiffLckTq_No_Cs 1;
BA_ "U_CDX706_MY2023_Tx" SG_ 1046 BpedDiffLckTq_No_Cs 1;
BA_ "U_T6_MCA_MY2020_Rx" SG_ 1046 RearDiffElckrOpen_B_Rq 1;
BA_ "U_P702_MY2021_Tx" SG_ 1046 RearDiffElckrOpen_B_Rq 1;
BA_ "U_T6_MCA_MY2020_Tx" SG_ 1046 RearDiffElckrOpen_B_Rq 1;
BA_ "U_U55X_MY2022_Tx" SG_ 1046 RearDiffElckrOpen_B_Rq 1;
BA_ "U_CDX706_MY2023_Tx" SG_ 1046 RearDiffElckrOpen_B_Rq 1;
BA_ "GenSigStartValueInteger" SG_ 1045 VehStab_D_Stat 14;
BA_ "GenSigStartValue" SG_ 1045 VehStab_D_Stat 14;
BA_ "U_CX727_MY2021_Rx" SG_ 1045 VehStab_D_Stat 1;
BA_ "U_P702_MY2021_Rx" SG_ 1045 VehStab_D_Stat 1;
BA_ "U_T6_MCA_MY2020_Rx" SG_ 1045 VehStab_D_Stat 1;
BA_ "U_CD542_MY2021_Rx" SG_ 1045 VehStab_D_Stat 1;
BA_ "U_U55X_MY2022_Rx" SG_ 1045 VehStab_D_Stat 1;
BA_ "U_CD764_MY2022_Rx" SG_ 1045 VehStab_D_Stat 1;
BA_ "U_CDX706_MY2023_Rx" SG_ 1045 VehStab_D_Stat 1;
BA_ "U_CX727_MY2021_Tx" SG_ 1045 VehStab_D_Stat 1;
BA_ "U_P702_MY2021_Tx" SG_ 1045 VehStab_D_Stat 1;
BA_ "U_T6_MCA_MY2020_Tx" SG_ 1045 VehStab_D_Stat 1;
BA_ "U_CD542_MY2021_Tx" SG_ 1045 VehStab_D_Stat 1;
BA_ "U_U55X_MY2022_Tx" SG_ 1045 VehStab_D_Stat 1;
BA_ "U_CD764_MY2022_Tx" SG_ 1045 VehStab_D_Stat 1;
BA_ "U_CDX706_MY2023_Tx" SG_ 1045 VehStab_D_Stat 1;
BA_ "U_CX727_MY2021_Tx" SG_ 1045 BrkFluidLvl_D_Stat 1;
BA_ "U_P702_MY2021_Tx" SG_ 1045 BrkFluidLvl_D_Stat 1;
BA_ "U_T6_MCA_MY2020_Tx" SG_ 1045 BrkFluidLvl_D_Stat 1;
BA_ "U_CD542_MY2021_Tx" SG_ 1045 BrkFluidLvl_D_Stat 1;
BA_ "U_U55X_MY2022_Tx" SG_ 1045 BrkFluidLvl_D_Stat 1;
BA_ "U_CD764_MY2022_Tx" SG_ 1045 BrkFluidLvl_D_Stat 1;
BA_ "U_CDX706_MY2023_Tx" SG_ 1045 BrkFluidLvl_D_Stat 1;
BA_ "U_P702_MY2021_Rx" SG_ 1045 LsmcBrkDecel_D_Stat 1;
BA_ "U_T6_MCA_MY2020_Rx" SG_ 1045 LsmcBrkDecel_D_Stat 1;
BA_ "U_U55X_MY2022_Rx" SG_ 1045 LsmcBrkDecel_D_Stat 1;
BA_ "U_P702_MY2021_Tx" SG_ 1045 LsmcBrkDecel_D_Stat 1;
BA_ "U_T6_MCA_MY2020_Tx" SG_ 1045 LsmcBrkDecel_D_Stat 1;
BA_ "U_U55X_MY2022_Tx" SG_ 1045 LsmcBrkDecel_D_Stat 1;
BA_ "GenSigStartValueInteger" SG_ 1045 VehYawNonLin_W_Rq 4094;
BA_ "GenSigStartValue" SG_ 1045 VehYawNonLin_W_Rq 4094;
BA_ "U_CX727_MY2021_Rx" SG_ 1045 VehYawNonLin_W_Rq 1;
BA_ "U_P702_MY2021_Rx" SG_ 1045 VehYawNonLin_W_Rq 1;
BA_ "U_T6_MCA_MY2020_Rx" SG_ 1045 VehYawNonLin_W_Rq 1;
BA_ "U_U55X_MY2022_Rx" SG_ 1045 VehYawNonLin_W_Rq 1;
BA_ "U_CDX706_MY2023_Rx" SG_ 1045 VehYawNonLin_W_Rq 1;
BA_ "U_CX727_MY2021_Tx" SG_ 1045 VehYawNonLin_W_Rq 1;
BA_ "U_P702_MY2021_Tx" SG_ 1045 VehYawNonLin_W_Rq 1;
BA_ "U_T6_MCA_MY2020_Tx" SG_ 1045 VehYawNonLin_W_Rq 1;
BA_ "U_CD542_MY2021_Tx" SG_ 1045 VehYawNonLin_W_Rq 1;
BA_ "U_U55X_MY2022_Tx" SG_ 1045 VehYawNonLin_W_Rq 1;
BA_ "U_CD764_MY2022_Tx" SG_ 1045 VehYawNonLin_W_Rq 1;
BA_ "U_CDX706_MY2023_Tx" SG_ 1045 VehYawNonLin_W_Rq 1;
BA_ "GenSigStartValueInteger" SG_ 1045 VehYawLin_W_Rq 4094;
BA_ "GenSigStartValue" SG_ 1045 VehYawLin_W_Rq 4094;
BA_ "U_CX727_MY2021_Rx" SG_ 1045 VehYawLin_W_Rq 1;
BA_ "U_P702_MY2021_Rx" SG_ 1045 VehYawLin_W_Rq 1;
BA_ "U_T6_MCA_MY2020_Rx" SG_ 1045 VehYawLin_W_Rq 1;
BA_ "U_U55X_MY2022_Rx" SG_ 1045 VehYawLin_W_Rq 1;
BA_ "U_CDX706_MY2023_Rx" SG_ 1045 VehYawLin_W_Rq 1;
BA_ "U_CX727_MY2021_Tx" SG_ 1045 VehYawLin_W_Rq 1;
BA_ "U_P702_MY2021_Tx" SG_ 1045 VehYawLin_W_Rq 1;
BA_ "U_T6_MCA_MY2020_Tx" SG_ 1045 VehYawLin_W_Rq 1;
BA_ "U_CD542_MY2021_Tx" SG_ 1045 VehYawLin_W_Rq 1;
BA_ "U_U55X_MY2022_Tx" SG_ 1045 VehYawLin_W_Rq 1;
BA_ "U_CD764_MY2022_Tx" SG_ 1045 VehYawLin_W_Rq 1;
BA_ "U_CDX706_MY2023_Tx" SG_ 1045 VehYawLin_W_Rq 1;
BA_ "MetaData" SG_ 1045 VehVActlBrk_No_Cs 1;
BA_ "U_CX727_MY2021_Rx" SG_ 1045 VehVActlBrk_No_Cs 1;
BA_ "U_P702_MY2021_Rx" SG_ 1045 VehVActlBrk_No_Cs 1;
BA_ "U_T6_MCA_MY2020_Rx" SG_ 1045 VehVActlBrk_No_Cs 1;
BA_ "U_CD542_MY2021_Rx" SG_ 1045 VehVActlBrk_No_Cs 1;
BA_ "U_U55X_MY2022_Rx" SG_ 1045 VehVActlBrk_No_Cs 1;
BA_ "U_CD764_MY2022_Rx" SG_ 1045 VehVActlBrk_No_Cs 1;
BA_ "U_CDX706_MY2023_Rx" SG_ 1045 VehVActlBrk_No_Cs 1;
BA_ "U_CX727_MY2021_Tx" SG_ 1045 VehVActlBrk_No_Cs 1;
BA_ "U_P702_MY2021_Tx" SG_ 1045 VehVActlBrk_No_Cs 1;
BA_ "U_T6_MCA_MY2020_Tx" SG_ 1045 VehVActlBrk_No_Cs 1;
BA_ "U_CD542_MY2021_Tx" SG_ 1045 VehVActlBrk_No_Cs 1;
BA_ "U_U55X_MY2022_Tx" SG_ 1045 VehVActlBrk_No_Cs 1;
BA_ "U_CD764_MY2022_Tx" SG_ 1045 VehVActlBrk_No_Cs 1;
BA_ "U_CDX706_MY2023_Tx" SG_ 1045 VehVActlBrk_No_Cs 1;
BA_ "U_CX727_MY2021_Rx" SG_ 1045 Veh_V_ActlBrk 1;
BA_ "U_P702_MY2021_Rx" SG_ 1045 Veh_V_ActlBrk 1;
BA_ "U_T6_MCA_MY2020_Rx" SG_ 1045 Veh_V_ActlBrk 1;
BA_ "U_CD542_MY2021_Rx" SG_ 1045 Veh_V_ActlBrk 1;
BA_ "U_U55X_MY2022_Rx" SG_ 1045 Veh_V_ActlBrk 1;
BA_ "U_CD764_MY2022_Rx" SG_ 1045 Veh_V_ActlBrk 1;
BA_ "U_CDX706_MY2023_Rx" SG_ 1045 Veh_V_ActlBrk 1;
BA_ "U_CX727_MY2021_Tx" SG_ 1045 Veh_V_ActlBrk 1;
BA_ "U_P702_MY2021_Tx" SG_ 1045 Veh_V_ActlBrk 1;
BA_ "U_T6_MCA_MY2020_Tx" SG_ 1045 Veh_V_ActlBrk 1;
BA_ "U_CD542_MY2021_Tx" SG_ 1045 Veh_V_ActlBrk 1;
BA_ "U_U55X_MY2022_Tx" SG_ 1045 Veh_V_ActlBrk 1;
BA_ "U_CD764_MY2022_Tx" SG_ 1045 Veh_V_ActlBrk 1;
BA_ "U_CDX706_MY2023_Tx" SG_ 1045 Veh_V_ActlBrk 1;
BA_ "MetaData" SG_ 1045 VehVActlBrk_No_Cnt 1;
BA_ "U_CX727_MY2021_Rx" SG_ 1045 VehVActlBrk_No_Cnt 1;
BA_ "U_P702_MY2021_Rx" SG_ 1045 VehVActlBrk_No_Cnt 1;
BA_ "U_T6_MCA_MY2020_Rx" SG_ 1045 VehVActlBrk_No_Cnt 1;
BA_ "U_CD542_MY2021_Rx" SG_ 1045 VehVActlBrk_No_Cnt 1;
BA_ "U_U55X_MY2022_Rx" SG_ 1045 VehVActlBrk_No_Cnt 1;
BA_ "U_CD764_MY2022_Rx" SG_ 1045 VehVActlBrk_No_Cnt 1;
BA_ "U_CDX706_MY2023_Rx" SG_ 1045 VehVActlBrk_No_Cnt 1;
BA_ "U_CX727_MY2021_Tx" SG_ 1045 VehVActlBrk_No_Cnt 1;
BA_ "U_P702_MY2021_Tx" SG_ 1045 VehVActlBrk_No_Cnt 1;
BA_ "U_T6_MCA_MY2020_Tx" SG_ 1045 VehVActlBrk_No_Cnt 1;
BA_ "U_CD542_MY2021_Tx" SG_ 1045 VehVActlBrk_No_Cnt 1;
BA_ "U_U55X_MY2022_Tx" SG_ 1045 VehVActlBrk_No_Cnt 1;
BA_ "U_CD764_MY2022_Tx" SG_ 1045 VehVActlBrk_No_Cnt 1;
BA_ "U_CDX706_MY2023_Tx" SG_ 1045 VehVActlBrk_No_Cnt 1;
BA_ "MetaData" SG_ 1045 VehVActlBrk_D_Qf 1;
BA_ "U_CX727_MY2021_Rx" SG_ 1045 VehVActlBrk_D_Qf 1;
BA_ "U_P702_MY2021_Rx" SG_ 1045 VehVActlBrk_D_Qf 1;
BA_ "U_T6_MCA_MY2020_Rx" SG_ 1045 VehVActlBrk_D_Qf 1;
BA_ "U_CD542_MY2021_Rx" SG_ 1045 VehVActlBrk_D_Qf 1;
BA_ "U_U55X_MY2022_Rx" SG_ 1045 VehVActlBrk_D_Qf 1;
BA_ "U_CD764_MY2022_Rx" SG_ 1045 VehVActlBrk_D_Qf 1;
BA_ "U_CDX706_MY2023_Rx" SG_ 1045 VehVActlBrk_D_Qf 1;
BA_ "U_CX727_MY2021_Tx" SG_ 1045 VehVActlBrk_D_Qf 1;
BA_ "U_P702_MY2021_Tx" SG_ 1045 VehVActlBrk_D_Qf 1;
BA_ "U_T6_MCA_MY2020_Tx" SG_ 1045 VehVActlBrk_D_Qf 1;
BA_ "U_CD542_MY2021_Tx" SG_ 1045 VehVActlBrk_D_Qf 1;
BA_ "U_U55X_MY2022_Tx" SG_ 1045 VehVActlBrk_D_Qf 1;
BA_ "U_CD764_MY2022_Tx" SG_ 1045 VehVActlBrk_D_Qf 1;
BA_ "U_CDX706_MY2023_Tx" SG_ 1045 VehVActlBrk_D_Qf 1;
BA_ "U_CDX706_MY2023_Tx" SG_ 1044 PrplBrkTqAsst_Pw_Rq 1;
BA_ "MetaData" SG_ 1044 ApaBrkErrDStat_No_Cs 1;
BA_ "U_CDX706_MY2023_Rx" SG_ 1044 ApaBrkErrDStat_No_Cs 1;
BA_ "U_CDX706_MY2023_Tx" SG_ 1044 ApaBrkErrDStat_No_Cs 1;
BA_ "MetaData" SG_ 1044 ApaBrkErrDStat_No_Cnt 1;
BA_ "U_CDX706_MY2023_Rx" SG_ 1044 ApaBrkErrDStat_No_Cnt 1;
BA_ "U_CDX706_MY2023_Tx" SG_ 1044 ApaBrkErrDStat_No_Cnt 1;
BA_ "GenSigStartValue" SG_ 1044 ApaBrkErr_D_Stat 2;
BA_ "U_CDX706_MY2023_Rx" SG_ 1044 ApaBrkErr_D_Stat 1;
BA_ "U_CDX706_MY2023_Tx" SG_ 1044 ApaBrkErr_D_Stat 1;
BA_ "GenSigStartValueInteger" SG_ 1044 StePinOffst_An_Est 65534;
BA_ "ContentDependant" SG_ 1044 StePinOffst_An_Est 1;
BA_ "GenSigStartValue" SG_ 1044 StePinOffst_An_Est 65533;
BA_ "U_CX727_MY2021_Rx" SG_ 1044 StePinOffst_An_Est 1;
BA_ "U_P702_MY2021_Rx" SG_ 1044 StePinOffst_An_Est 1;
BA_ "U_T6_MCA_MY2020_Rx" SG_ 1044 StePinOffst_An_Est 1;
BA_ "U_CD542_MY2021_Rx" SG_ 1044 StePinOffst_An_Est 1;
BA_ "U_U55X_MY2022_Rx" SG_ 1044 StePinOffst_An_Est 1;
BA_ "U_CD764_MY2022_Rx" SG_ 1044 StePinOffst_An_Est 1;
BA_ "U_CDX706_MY2023_Rx" SG_ 1044 StePinOffst_An_Est 1;
BA_ "U_CX727_MY2021_Tx" SG_ 1044 StePinOffst_An_Est 1;
BA_ "U_P702_MY2021_Tx" SG_ 1044 StePinOffst_An_Est 1;
BA_ "U_T6_MCA_MY2020_Tx" SG_ 1044 StePinOffst_An_Est 1;
BA_ "U_CD542_MY2021_Tx" SG_ 1044 StePinOffst_An_Est 1;
BA_ "U_U55X_MY2022_Tx" SG_ 1044 StePinOffst_An_Est 1;
BA_ "U_CD764_MY2022_Tx" SG_ 1044 StePinOffst_An_Est 1;
BA_ "U_CDX706_MY2023_Tx" SG_ 1044 StePinOffst_An_Est 1;
BA_ "ContentDependant" SG_ 1044 StePinOffst_No_Cs 1;
BA_ "MetaData" SG_ 1044 StePinOffst_No_Cs 1;
BA_ "U_CX727_MY2021_Rx" SG_ 1044 StePinOffst_No_Cs 1;
BA_ "U_P702_MY2021_Rx" SG_ 1044 StePinOffst_No_Cs 1;
BA_ "U_T6_MCA_MY2020_Rx" SG_ 1044 StePinOffst_No_Cs 1;
BA_ "U_CD542_MY2021_Rx" SG_ 1044 StePinOffst_No_Cs 1;
BA_ "U_U55X_MY2022_Rx" SG_ 1044 StePinOffst_No_Cs 1;
BA_ "U_CD764_MY2022_Rx" SG_ 1044 StePinOffst_No_Cs 1;
BA_ "U_CDX706_MY2023_Rx" SG_ 1044 StePinOffst_No_Cs 1;
BA_ "U_CX727_MY2021_Tx" SG_ 1044 StePinOffst_No_Cs 1;
BA_ "U_P702_MY2021_Tx" SG_ 1044 StePinOffst_No_Cs 1;
BA_ "U_T6_MCA_MY2020_Tx" SG_ 1044 StePinOffst_No_Cs 1;
BA_ "U_CD542_MY2021_Tx" SG_ 1044 StePinOffst_No_Cs 1;
BA_ "U_U55X_MY2022_Tx" SG_ 1044 StePinOffst_No_Cs 1;
BA_ "U_CD764_MY2022_Tx" SG_ 1044 StePinOffst_No_Cs 1;
BA_ "U_CDX706_MY2023_Tx" SG_ 1044 StePinOffst_No_Cs 1;
BA_ "MetaData" SG_ 1044 StePinOffst_No_Cnt 1;
BA_ "U_CX727_MY2021_Rx" SG_ 1044 StePinOffst_No_Cnt 1;
BA_ "U_P702_MY2021_Rx" SG_ 1044 StePinOffst_No_Cnt 1;
BA_ "U_T6_MCA_MY2020_Rx" SG_ 1044 StePinOffst_No_Cnt 1;
BA_ "U_CD542_MY2021_Rx" SG_ 1044 StePinOffst_No_Cnt 1;
BA_ "U_U55X_MY2022_Rx" SG_ 1044 StePinOffst_No_Cnt 1;
BA_ "U_CD764_MY2022_Rx" SG_ 1044 StePinOffst_No_Cnt 1;
BA_ "U_CDX706_MY2023_Rx" SG_ 1044 StePinOffst_No_Cnt 1;
BA_ "U_CX727_MY2021_Tx" SG_ 1044 StePinOffst_No_Cnt 1;
BA_ "U_P702_MY2021_Tx" SG_ 1044 StePinOffst_No_Cnt 1;
BA_ "U_T6_MCA_MY2020_Tx" SG_ 1044 StePinOffst_No_Cnt 1;
BA_ "U_CD542_MY2021_Tx" SG_ 1044 StePinOffst_No_Cnt 1;
BA_ "U_U55X_MY2022_Tx" SG_ 1044 StePinOffst_No_Cnt 1;
BA_ "U_CD764_MY2022_Tx" SG_ 1044 StePinOffst_No_Cnt 1;
BA_ "U_CDX706_MY2023_Tx" SG_ 1044 StePinOffst_No_Cnt 1;
BA_ "U_CX727_MY2021_Rx" SG_ 1044 StePinOffst_D_Stat 1;
BA_ "U_P702_MY2021_Rx" SG_ 1044 StePinOffst_D_Stat 1;
BA_ "U_T6_MCA_MY2020_Rx" SG_ 1044 StePinOffst_D_Stat 1;
BA_ "U_CD542_MY2021_Rx" SG_ 1044 StePinOffst_D_Stat 1;
BA_ "U_U55X_MY2022_Rx" SG_ 1044 StePinOffst_D_Stat 1;
BA_ "U_CD764_MY2022_Rx" SG_ 1044 StePinOffst_D_Stat 1;
BA_ "U_CDX706_MY2023_Rx" SG_ 1044 StePinOffst_D_Stat 1;
BA_ "U_CX727_MY2021_Tx" SG_ 1044 StePinOffst_D_Stat 1;
BA_ "U_P702_MY2021_Tx" SG_ 1044 StePinOffst_D_Stat 1;
BA_ "U_T6_MCA_MY2020_Tx" SG_ 1044 StePinOffst_D_Stat 1;
BA_ "U_CD542_MY2021_Tx" SG_ 1044 StePinOffst_D_Stat 1;
BA_ "U_U55X_MY2022_Tx" SG_ 1044 StePinOffst_D_Stat 1;
BA_ "U_CD764_MY2022_Tx" SG_ 1044 StePinOffst_D_Stat 1;
BA_ "U_CDX706_MY2023_Tx" SG_ 1044 StePinOffst_D_Stat 1;
BA_ "GenSigStartValueInteger" SG_ 1042 VehRol_An_Dsply 64;
BA_ "U_P702_MY2021_Tx" SG_ 1042 VehRol_An_Dsply 1;
BA_ "U_T6_MCA_MY2020_Tx" SG_ 1042 VehRol_An_Dsply 1;
BA_ "U_U55X_MY2022_Tx" SG_ 1042 VehRol_An_Dsply 1;
BA_ "U_CDX706_MY2023_Tx" SG_ 1042 VehRol_An_Dsply 1;
BA_ "U_U55X_MY2022_Rx" SG_ 1042 RearDiffLck_Tq_RqMn 1;
BA_ "U_U55X_MY2022_Tx" SG_ 1042 RearDiffLck_Tq_RqMn 1;
BA_ "GenSigStartValueInteger" SG_ 1042 VehPtch_An_Dsply 64;
BA_ "U_P702_MY2021_Rx" SG_ 1042 VehPtch_An_Dsply 1;
BA_ "U_U55X_MY2022_Rx" SG_ 1042 VehPtch_An_Dsply 1;
BA_ "U_P702_MY2021_Tx" SG_ 1042 VehPtch_An_Dsply 1;
BA_ "U_T6_MCA_MY2020_Tx" SG_ 1042 VehPtch_An_Dsply 1;
BA_ "U_U55X_MY2022_Tx" SG_ 1042 VehPtch_An_Dsply 1;
BA_ "U_CDX706_MY2023_Tx" SG_ 1042 VehPtch_An_Dsply 1;
BA_ "U_P702_MY2021_Tx" SG_ 1042 TrlrBrk_Pc_Rq 1;
BA_ "U_T6_MCA_MY2020_Tx" SG_ 1042 TrlrBrk_Pc_Rq 1;
BA_ "U_U55X_MY2022_Tx" SG_ 1042 TrlrBrk_Pc_Rq 1;
BA_ "U_CDX706_MY2023_Tx" SG_ 1042 TrlrBrk_Pc_Rq 1;
BA_ "U_CX727_MY2021_Rx" SG_ 535 WhlRr_W_Meas 1;
BA_ "U_P702_MY2021_Rx" SG_ 535 WhlRr_W_Meas 1;
BA_ "U_T6_MCA_MY2020_Rx" SG_ 535 WhlRr_W_Meas 1;
BA_ "U_CD542_MY2021_Rx" SG_ 535 WhlRr_W_Meas 1;
BA_ "U_U55X_MY2022_Rx" SG_ 535 WhlRr_W_Meas 1;
BA_ "U_CD764_MY2022_Rx" SG_ 535 WhlRr_W_Meas 1;
BA_ "U_CDX706_MY2023_Rx" SG_ 535 WhlRr_W_Meas 1;
BA_ "U_CX727_MY2021_Tx" SG_ 535 WhlRr_W_Meas 1;
BA_ "U_P702_MY2021_Tx" SG_ 535 WhlRr_W_Meas 1;
BA_ "U_T6_MCA_MY2020_Tx" SG_ 535 WhlRr_W_Meas 1;
BA_ "U_CD542_MY2021_Tx" SG_ 535 WhlRr_W_Meas 1;
BA_ "U_U55X_MY2022_Tx" SG_ 535 WhlRr_W_Meas 1;
BA_ "U_CD764_MY2022_Tx" SG_ 535 WhlRr_W_Meas 1;
BA_ "U_CDX706_MY2023_Tx" SG_ 535 WhlRr_W_Meas 1;
BA_ "U_CX727_MY2021_Rx" SG_ 535 WhlRl_W_Meas 1;
BA_ "U_P702_MY2021_Rx" SG_ 535 WhlRl_W_Meas 1;
BA_ "U_T6_MCA_MY2020_Rx" SG_ 535 WhlRl_W_Meas 1;
BA_ "U_CD542_MY2021_Rx" SG_ 535 WhlRl_W_Meas 1;
BA_ "U_U55X_MY2022_Rx" SG_ 535 WhlRl_W_Meas 1;
BA_ "U_CD764_MY2022_Rx" SG_ 535 WhlRl_W_Meas 1;
BA_ "U_CDX706_MY2023_Rx" SG_ 535 WhlRl_W_Meas 1;
BA_ "U_CX727_MY2021_Tx" SG_ 535 WhlRl_W_Meas 1;
BA_ "U_P702_MY2021_Tx" SG_ 535 WhlRl_W_Meas 1;
BA_ "U_T6_MCA_MY2020_Tx" SG_ 535 WhlRl_W_Meas 1;
BA_ "U_CD542_MY2021_Tx" SG_ 535 WhlRl_W_Meas 1;
BA_ "U_U55X_MY2022_Tx" SG_ 535 WhlRl_W_Meas 1;
BA_ "U_CD764_MY2022_Tx" SG_ 535 WhlRl_W_Meas 1;
BA_ "U_CDX706_MY2023_Tx" SG_ 535 WhlRl_W_Meas 1;
BA_ "U_CX727_MY2021_Rx" SG_ 535 WhlFr_W_Meas 1;
BA_ "U_P702_MY2021_Rx" SG_ 535 WhlFr_W_Meas 1;
BA_ "U_T6_MCA_MY2020_Rx" SG_ 535 WhlFr_W_Meas 1;
BA_ "U_CD542_MY2021_Rx" SG_ 535 WhlFr_W_Meas 1;
BA_ "U_U55X_MY2022_Rx" SG_ 535 WhlFr_W_Meas 1;
BA_ "U_CD764_MY2022_Rx" SG_ 535 WhlFr_W_Meas 1;
BA_ "U_CDX706_MY2023_Rx" SG_ 535 WhlFr_W_Meas 1;
BA_ "U_CX727_MY2021_Tx" SG_ 535 WhlFr_W_Meas 1;
BA_ "U_P702_MY2021_Tx" SG_ 535 WhlFr_W_Meas 1;
BA_ "U_T6_MCA_MY2020_Tx" SG_ 535 WhlFr_W_Meas 1;
BA_ "U_CD542_MY2021_Tx" SG_ 535 WhlFr_W_Meas 1;
BA_ "U_U55X_MY2022_Tx" SG_ 535 WhlFr_W_Meas 1;
BA_ "U_CD764_MY2022_Tx" SG_ 535 WhlFr_W_Meas 1;
BA_ "U_CDX706_MY2023_Tx" SG_ 535 WhlFr_W_Meas 1;
BA_ "U_CX727_MY2021_Rx" SG_ 535 WhlFl_W_Meas 1;
BA_ "U_P702_MY2021_Rx" SG_ 535 WhlFl_W_Meas 1;
BA_ "U_T6_MCA_MY2020_Rx" SG_ 535 WhlFl_W_Meas 1;
BA_ "U_CD542_MY2021_Rx" SG_ 535 WhlFl_W_Meas 1;
BA_ "U_U55X_MY2022_Rx" SG_ 535 WhlFl_W_Meas 1;
BA_ "U_CD764_MY2022_Rx" SG_ 535 WhlFl_W_Meas 1;
BA_ "U_CDX706_MY2023_Rx" SG_ 535 WhlFl_W_Meas 1;
BA_ "U_CX727_MY2021_Tx" SG_ 535 WhlFl_W_Meas 1;
BA_ "U_P702_MY2021_Tx" SG_ 535 WhlFl_W_Meas 1;
BA_ "U_T6_MCA_MY2020_Tx" SG_ 535 WhlFl_W_Meas 1;
BA_ "U_CD542_MY2021_Tx" SG_ 535 WhlFl_W_Meas 1;
BA_ "U_U55X_MY2022_Tx" SG_ 535 WhlFl_W_Meas 1;
BA_ "U_CD764_MY2022_Tx" SG_ 535 WhlFl_W_Meas 1;
BA_ "U_CDX706_MY2023_Tx" SG_ 535 WhlFl_W_Meas 1;
BA_ "ContentDependant" SG_ 534 BrkObdData_No_Actl 1;
BA_ "U_CX727_MY2021_Rx" SG_ 534 BrkObdData_No_Actl 1;
BA_ "U_CD542_MY2021_Rx" SG_ 534 BrkObdData_No_Actl 1;
BA_ "U_CDX706_MY2023_Rx" SG_ 534 BrkObdData_No_Actl 1;
BA_ "U_CX727_MY2021_Tx" SG_ 534 BrkObdData_No_Actl 1;
BA_ "U_P702_MY2021_Tx" SG_ 534 BrkObdData_No_Actl 1;
BA_ "U_T6_MCA_MY2020_Tx" SG_ 534 BrkObdData_No_Actl 1;
BA_ "U_CD542_MY2021_Tx" SG_ 534 BrkObdData_No_Actl 1;
BA_ "U_U55X_MY2022_Tx" SG_ 534 BrkObdData_No_Actl 1;
BA_ "U_CD764_MY2022_Tx" SG_ 534 BrkObdData_No_Actl 1;
BA_ "ContentDependant" SG_ 534 BrkObdIndex_No_Actl 1;
BA_ "U_CX727_MY2021_Rx" SG_ 534 BrkObdIndex_No_Actl 1;
BA_ "U_CD542_MY2021_Rx" SG_ 534 BrkObdIndex_No_Actl 1;
BA_ "U_CDX706_MY2023_Rx" SG_ 534 BrkObdIndex_No_Actl 1;
BA_ "U_CX727_MY2021_Tx" SG_ 534 BrkObdIndex_No_Actl 1;
BA_ "U_P702_MY2021_Tx" SG_ 534 BrkObdIndex_No_Actl 1;
BA_ "U_T6_MCA_MY2020_Tx" SG_ 534 BrkObdIndex_No_Actl 1;
BA_ "U_CD542_MY2021_Tx" SG_ 534 BrkObdIndex_No_Actl 1;
BA_ "U_U55X_MY2022_Tx" SG_ 534 BrkObdIndex_No_Actl 1;
BA_ "U_CD764_MY2022_Tx" SG_ 534 BrkObdIndex_No_Actl 1;
BA_ "U_P702_MY2021_Rx" SG_ 534 WhlRotatRr_No_Cnt 1;
BA_ "U_T6_MCA_MY2020_Rx" SG_ 534 WhlRotatRr_No_Cnt 1;
BA_ "U_CD542_MY2021_Rx" SG_ 534 WhlRotatRr_No_Cnt 1;
BA_ "U_U55X_MY2022_Rx" SG_ 534 WhlRotatRr_No_Cnt 1;
BA_ "U_CD764_MY2022_Rx" SG_ 534 WhlRotatRr_No_Cnt 1;
BA_ "U_CDX706_MY2023_Rx" SG_ 534 WhlRotatRr_No_Cnt 1;
BA_ "U_CX727_MY2021_Tx" SG_ 534 WhlRotatRr_No_Cnt 1;
BA_ "U_P702_MY2021_Tx" SG_ 534 WhlRotatRr_No_Cnt 1;
BA_ "U_T6_MCA_MY2020_Tx" SG_ 534 WhlRotatRr_No_Cnt 1;
BA_ "U_CD542_MY2021_Tx" SG_ 534 WhlRotatRr_No_Cnt 1;
BA_ "U_U55X_MY2022_Tx" SG_ 534 WhlRotatRr_No_Cnt 1;
BA_ "U_CD764_MY2022_Tx" SG_ 534 WhlRotatRr_No_Cnt 1;
BA_ "U_CDX706_MY2023_Tx" SG_ 534 WhlRotatRr_No_Cnt 1;
BA_ "U_CX727_MY2021_Rx" SG_ 534 WhlDirRr_D_Actl 1;
BA_ "U_P702_MY2021_Rx" SG_ 534 WhlDirRr_D_Actl 1;
BA_ "U_T6_MCA_MY2020_Rx" SG_ 534 WhlDirRr_D_Actl 1;
BA_ "U_CD542_MY2021_Rx" SG_ 534 WhlDirRr_D_Actl 1;
BA_ "U_U55X_MY2022_Rx" SG_ 534 WhlDirRr_D_Actl 1;
BA_ "U_CD764_MY2022_Rx" SG_ 534 WhlDirRr_D_Actl 1;
BA_ "U_CDX706_MY2023_Rx" SG_ 534 WhlDirRr_D_Actl 1;
BA_ "U_CX727_MY2021_Tx" SG_ 534 WhlDirRr_D_Actl 1;
BA_ "U_P702_MY2021_Tx" SG_ 534 WhlDirRr_D_Actl 1;
BA_ "U_T6_MCA_MY2020_Tx" SG_ 534 WhlDirRr_D_Actl 1;
BA_ "U_CD542_MY2021_Tx" SG_ 534 WhlDirRr_D_Actl 1;
BA_ "U_U55X_MY2022_Tx" SG_ 534 WhlDirRr_D_Actl 1;
BA_ "U_CD764_MY2022_Tx" SG_ 534 WhlDirRr_D_Actl 1;
BA_ "U_CDX706_MY2023_Tx" SG_ 534 WhlDirRr_D_Actl 1;
BA_ "U_CX727_MY2021_Rx" SG_ 534 WhlDirRl_D_Actl 1;
BA_ "U_P702_MY2021_Rx" SG_ 534 WhlDirRl_D_Actl 1;
BA_ "U_T6_MCA_MY2020_Rx" SG_ 534 WhlDirRl_D_Actl 1;
BA_ "U_CD542_MY2021_Rx" SG_ 534 WhlDirRl_D_Actl 1;
BA_ "U_U55X_MY2022_Rx" SG_ 534 WhlDirRl_D_Actl 1;
BA_ "U_CD764_MY2022_Rx" SG_ 534 WhlDirRl_D_Actl 1;
BA_ "U_CDX706_MY2023_Rx" SG_ 534 WhlDirRl_D_Actl 1;
BA_ "U_CX727_MY2021_Tx" SG_ 534 WhlDirRl_D_Actl 1;
BA_ "U_P702_MY2021_Tx" SG_ 534 WhlDirRl_D_Actl 1;
BA_ "U_T6_MCA_MY2020_Tx" SG_ 534 WhlDirRl_D_Actl 1;
BA_ "U_CD542_MY2021_Tx" SG_ 534 WhlDirRl_D_Actl 1;
BA_ "U_U55X_MY2022_Tx" SG_ 534 WhlDirRl_D_Actl 1;
BA_ "U_CD764_MY2022_Tx" SG_ 534 WhlDirRl_D_Actl 1;
BA_ "U_CDX706_MY2023_Tx" SG_ 534 WhlDirRl_D_Actl 1;
BA_ "U_CX727_MY2021_Rx" SG_ 534 WhlDirFr_D_Actl 1;
BA_ "U_P702_MY2021_Rx" SG_ 534 WhlDirFr_D_Actl 1;
BA_ "U_T6_MCA_MY2020_Rx" SG_ 534 WhlDirFr_D_Actl 1;
BA_ "U_CD542_MY2021_Rx" SG_ 534 WhlDirFr_D_Actl 1;
BA_ "U_U55X_MY2022_Rx" SG_ 534 WhlDirFr_D_Actl 1;
BA_ "U_CD764_MY2022_Rx" SG_ 534 WhlDirFr_D_Actl 1;
BA_ "U_CDX706_MY2023_Rx" SG_ 534 WhlDirFr_D_Actl 1;
BA_ "U_CX727_MY2021_Tx" SG_ 534 WhlDirFr_D_Actl 1;
BA_ "U_P702_MY2021_Tx" SG_ 534 WhlDirFr_D_Actl 1;
BA_ "U_T6_MCA_MY2020_Tx" SG_ 534 WhlDirFr_D_Actl 1;
BA_ "U_CD542_MY2021_Tx" SG_ 534 WhlDirFr_D_Actl 1;
BA_ "U_U55X_MY2022_Tx" SG_ 534 WhlDirFr_D_Actl 1;
BA_ "U_CD764_MY2022_Tx" SG_ 534 WhlDirFr_D_Actl 1;
BA_ "U_CDX706_MY2023_Tx" SG_ 534 WhlDirFr_D_Actl 1;
BA_ "U_CX727_MY2021_Rx" SG_ 534 WhlDirFl_D_Actl 1;
BA_ "U_P702_MY2021_Rx" SG_ 534 WhlDirFl_D_Actl 1;
BA_ "U_T6_MCA_MY2020_Rx" SG_ 534 WhlDirFl_D_Actl 1;
BA_ "U_CD542_MY2021_Rx" SG_ 534 WhlDirFl_D_Actl 1;
BA_ "U_U55X_MY2022_Rx" SG_ 534 WhlDirFl_D_Actl 1;
BA_ "U_CD764_MY2022_Rx" SG_ 534 WhlDirFl_D_Actl 1;
BA_ "U_CDX706_MY2023_Rx" SG_ 534 WhlDirFl_D_Actl 1;
BA_ "U_CX727_MY2021_Tx" SG_ 534 WhlDirFl_D_Actl 1;
BA_ "U_P702_MY2021_Tx" SG_ 534 WhlDirFl_D_Actl 1;
BA_ "U_T6_MCA_MY2020_Tx" SG_ 534 WhlDirFl_D_Actl 1;
BA_ "U_CD542_MY2021_Tx" SG_ 534 WhlDirFl_D_Actl 1;
BA_ "U_U55X_MY2022_Tx" SG_ 534 WhlDirFl_D_Actl 1;
BA_ "U_CD764_MY2022_Tx" SG_ 534 WhlDirFl_D_Actl 1;
BA_ "U_CDX706_MY2023_Tx" SG_ 534 WhlDirFl_D_Actl 1;
BA_ "U_P702_MY2021_Rx" SG_ 534 WhlRotatRl_No_Cnt 1;
BA_ "U_T6_MCA_MY2020_Rx" SG_ 534 WhlRotatRl_No_Cnt 1;
BA_ "U_CD542_MY2021_Rx" SG_ 534 WhlRotatRl_No_Cnt 1;
BA_ "U_U55X_MY2022_Rx" SG_ 534 WhlRotatRl_No_Cnt 1;
BA_ "U_CD764_MY2022_Rx" SG_ 534 WhlRotatRl_No_Cnt 1;
BA_ "U_CDX706_MY2023_Rx" SG_ 534 WhlRotatRl_No_Cnt 1;
BA_ "U_CX727_MY2021_Tx" SG_ 534 WhlRotatRl_No_Cnt 1;
BA_ "U_P702_MY2021_Tx" SG_ 534 WhlRotatRl_No_Cnt 1;
BA_ "U_T6_MCA_MY2020_Tx" SG_ 534 WhlRotatRl_No_Cnt 1;
BA_ "U_CD542_MY2021_Tx" SG_ 534 WhlRotatRl_No_Cnt 1;
BA_ "U_U55X_MY2022_Tx" SG_ 534 WhlRotatRl_No_Cnt 1;
BA_ "U_CD764_MY2022_Tx" SG_ 534 WhlRotatRl_No_Cnt 1;
BA_ "U_CDX706_MY2023_Tx" SG_ 534 WhlRotatRl_No_Cnt 1;
BA_ "U_P702_MY2021_Rx" SG_ 534 WhlRotatFr_No_Cnt 1;
BA_ "U_T6_MCA_MY2020_Rx" SG_ 534 WhlRotatFr_No_Cnt 1;
BA_ "U_CD542_MY2021_Rx" SG_ 534 WhlRotatFr_No_Cnt 1;
BA_ "U_U55X_MY2022_Rx" SG_ 534 WhlRotatFr_No_Cnt 1;
BA_ "U_CD764_MY2022_Rx" SG_ 534 WhlRotatFr_No_Cnt 1;
BA_ "U_CDX706_MY2023_Rx" SG_ 534 WhlRotatFr_No_Cnt 1;
BA_ "U_CX727_MY2021_Tx" SG_ 534 WhlRotatFr_No_Cnt 1;
BA_ "U_P702_MY2021_Tx" SG_ 534 WhlRotatFr_No_Cnt 1;
BA_ "U_T6_MCA_MY2020_Tx" SG_ 534 WhlRotatFr_No_Cnt 1;
BA_ "U_CD542_MY2021_Tx" SG_ 534 WhlRotatFr_No_Cnt 1;
BA_ "U_U55X_MY2022_Tx" SG_ 534 WhlRotatFr_No_Cnt 1;
BA_ "U_CD764_MY2022_Tx" SG_ 534 WhlRotatFr_No_Cnt 1;
BA_ "U_CDX706_MY2023_Tx" SG_ 534 WhlRotatFr_No_Cnt 1;
BA_ "U_P702_MY2021_Rx" SG_ 534 WhlRotatFl_No_Cnt 1;
BA_ "U_T6_MCA_MY2020_Rx" SG_ 534 WhlRotatFl_No_Cnt 1;
BA_ "U_CD542_MY2021_Rx" SG_ 534 WhlRotatFl_No_Cnt 1;
BA_ "U_U55X_MY2022_Rx" SG_ 534 WhlRotatFl_No_Cnt 1;
BA_ "U_CD764_MY2022_Rx" SG_ 534 WhlRotatFl_No_Cnt 1;
BA_ "U_CDX706_MY2023_Rx" SG_ 534 WhlRotatFl_No_Cnt 1;
BA_ "U_CX727_MY2021_Tx" SG_ 534 WhlRotatFl_No_Cnt 1;
BA_ "U_P702_MY2021_Tx" SG_ 534 WhlRotatFl_No_Cnt 1;
BA_ "U_T6_MCA_MY2020_Tx" SG_ 534 WhlRotatFl_No_Cnt 1;
BA_ "U_CD542_MY2021_Tx" SG_ 534 WhlRotatFl_No_Cnt 1;
BA_ "U_U55X_MY2022_Tx" SG_ 534 WhlRotatFl_No_Cnt 1;
BA_ "U_CD764_MY2022_Tx" SG_ 534 WhlRotatFl_No_Cnt 1;
BA_ "U_CDX706_MY2023_Tx" SG_ 534 WhlRotatFl_No_Cnt 1;
BA_ "U_CX727_MY2021_Rx" SG_ 532 RgenTqFalt_B_Actl 1;
BA_ "U_P702_MY2021_Rx" SG_ 532 RgenTqFalt_B_Actl 1;
BA_ "U_CD542_MY2021_Rx" SG_ 532 RgenTqFalt_B_Actl 1;
BA_ "U_CDX706_MY2023_Rx" SG_ 532 RgenTqFalt_B_Actl 1;
BA_ "U_CX727_MY2021_Tx" SG_ 532 RgenTqFalt_B_Actl 1;
BA_ "U_P702_MY2021_Tx" SG_ 532 RgenTqFalt_B_Actl 1;
BA_ "U_T6_MCA_MY2020_Tx" SG_ 532 RgenTqFalt_B_Actl 1;
BA_ "U_CD542_MY2021_Tx" SG_ 532 RgenTqFalt_B_Actl 1;
BA_ "U_U55X_MY2022_Tx" SG_ 532 RgenTqFalt_B_Actl 1;
BA_ "U_CDX706_MY2023_Tx" SG_ 532 RgenTqFalt_B_Actl 1;
BA_ "U_CX727_MY2021_Rx" SG_ 532 RgenBrkDynoMde_B_Actl 1;
BA_ "U_P702_MY2021_Rx" SG_ 532 RgenBrkDynoMde_B_Actl 1;
BA_ "U_CD542_MY2021_Rx" SG_ 532 RgenBrkDynoMde_B_Actl 1;
BA_ "U_CDX706_MY2023_Rx" SG_ 532 RgenBrkDynoMde_B_Actl 1;
BA_ "U_CX727_MY2021_Tx" SG_ 532 RgenBrkDynoMde_B_Actl 1;
BA_ "U_P702_MY2021_Tx" SG_ 532 RgenBrkDynoMde_B_Actl 1;
BA_ "U_T6_MCA_MY2020_Tx" SG_ 532 RgenBrkDynoMde_B_Actl 1;
BA_ "U_CD542_MY2021_Tx" SG_ 532 RgenBrkDynoMde_B_Actl 1;
BA_ "U_U55X_MY2022_Tx" SG_ 532 RgenBrkDynoMde_B_Actl 1;
BA_ "U_CDX706_MY2023_Tx" SG_ 532 RgenBrkDynoMde_B_Actl 1;
BA_ "MetaData" SG_ 532 PrplWhlTqRqMn_No_Cs 1;
BA_ "U_CX727_MY2021_Rx" SG_ 532 PrplWhlTqRqMn_No_Cs 1;
BA_ "U_P702_MY2021_Rx" SG_ 532 PrplWhlTqRqMn_No_Cs 1;
BA_ "U_T6_MCA_MY2020_Rx" SG_ 532 PrplWhlTqRqMn_No_Cs 1;
BA_ "U_CD542_MY2021_Rx" SG_ 532 PrplWhlTqRqMn_No_Cs 1;
BA_ "U_U55X_MY2022_Rx" SG_ 532 PrplWhlTqRqMn_No_Cs 1;
BA_ "U_CD764_MY2022_Rx" SG_ 532 PrplWhlTqRqMn_No_Cs 1;
BA_ "U_CDX706_MY2023_Rx" SG_ 532 PrplWhlTqRqMn_No_Cs 1;
BA_ "U_CX727_MY2021_Tx" SG_ 532 PrplWhlTqRqMn_No_Cs 1;
BA_ "U_P702_MY2021_Tx" SG_ 532 PrplWhlTqRqMn_No_Cs 1;
BA_ "U_T6_MCA_MY2020_Tx" SG_ 532 PrplWhlTqRqMn_No_Cs 1;
BA_ "U_CD542_MY2021_Tx" SG_ 532 PrplWhlTqRqMn_No_Cs 1;
BA_ "U_U55X_MY2022_Tx" SG_ 532 PrplWhlTqRqMn_No_Cs 1;
BA_ "U_CX727_MY2021_Tx" SG_ 532 PrplWhlRear_Tq_RqMx 1;
BA_ "U_P702_MY2021_Tx" SG_ 532 PrplWhlRear_Tq_RqMx 1;
BA_ "U_T6_MCA_MY2020_Tx" SG_ 532 PrplWhlRear_Tq_RqMx 1;
BA_ "U_CD542_MY2021_Tx" SG_ 532 PrplWhlRear_Tq_RqMx 1;
BA_ "U_U55X_MY2022_Tx" SG_ 532 PrplWhlRear_Tq_RqMx 1;
BA_ "U_CX727_MY2021_Rx" SG_ 532 PrplWhlTot_Tq_RqMn 1;
BA_ "U_P702_MY2021_Rx" SG_ 532 PrplWhlTot_Tq_RqMn 1;
BA_ "U_T6_MCA_MY2020_Rx" SG_ 532 PrplWhlTot_Tq_RqMn 1;
BA_ "U_CD542_MY2021_Rx" SG_ 532 PrplWhlTot_Tq_RqMn 1;
BA_ "U_U55X_MY2022_Rx" SG_ 532 PrplWhlTot_Tq_RqMn 1;
BA_ "U_CD764_MY2022_Rx" SG_ 532 PrplWhlTot_Tq_RqMn 1;
BA_ "U_CDX706_MY2023_Rx" SG_ 532 PrplWhlTot_Tq_RqMn 1;
BA_ "U_CX727_MY2021_Tx" SG_ 532 PrplWhlTot_Tq_RqMn 1;
BA_ "U_P702_MY2021_Tx" SG_ 532 PrplWhlTot_Tq_RqMn 1;
BA_ "U_T6_MCA_MY2020_Tx" SG_ 532 PrplWhlTot_Tq_RqMn 1;
BA_ "U_CD542_MY2021_Tx" SG_ 532 PrplWhlTot_Tq_RqMn 1;
BA_ "U_U55X_MY2022_Tx" SG_ 532 PrplWhlTot_Tq_RqMn 1;
BA_ "U_CDX706_MY2023_Tx" SG_ 532 PrplWhlTot_Tq_RqMn 1;
BA_ "MetaData" SG_ 532 PrplWhlTqRqMn_No_Cnt 1;
BA_ "U_CX727_MY2021_Rx" SG_ 532 PrplWhlTqRqMn_No_Cnt 1;
BA_ "U_P702_MY2021_Rx" SG_ 532 PrplWhlTqRqMn_No_Cnt 1;
BA_ "U_T6_MCA_MY2020_Rx" SG_ 532 PrplWhlTqRqMn_No_Cnt 1;
BA_ "U_CD542_MY2021_Rx" SG_ 532 PrplWhlTqRqMn_No_Cnt 1;
BA_ "U_U55X_MY2022_Rx" SG_ 532 PrplWhlTqRqMn_No_Cnt 1;
BA_ "U_CD764_MY2022_Rx" SG_ 532 PrplWhlTqRqMn_No_Cnt 1;
BA_ "U_CDX706_MY2023_Rx" SG_ 532 PrplWhlTqRqMn_No_Cnt 1;
BA_ "U_CX727_MY2021_Tx" SG_ 532 PrplWhlTqRqMn_No_Cnt 1;
BA_ "U_P702_MY2021_Tx" SG_ 532 PrplWhlTqRqMn_No_Cnt 1;
BA_ "U_T6_MCA_MY2020_Tx" SG_ 532 PrplWhlTqRqMn_No_Cnt 1;
BA_ "U_CD542_MY2021_Tx" SG_ 532 PrplWhlTqRqMn_No_Cnt 1;
BA_ "U_U55X_MY2022_Tx" SG_ 532 PrplWhlTqRqMn_No_Cnt 1;
BA_ "U_CX727_MY2021_Rx" SG_ 532 PrplWhlRear_Tq_RqMn 1;
BA_ "U_CD542_MY2021_Rx" SG_ 532 PrplWhlRear_Tq_RqMn 1;
BA_ "U_CDX706_MY2023_Rx" SG_ 532 PrplWhlRear_Tq_RqMn 1;
BA_ "U_CX727_MY2021_Tx" SG_ 532 PrplWhlRear_Tq_RqMn 1;
BA_ "U_P702_MY2021_Tx" SG_ 532 PrplWhlRear_Tq_RqMn 1;
BA_ "U_T6_MCA_MY2020_Tx" SG_ 532 PrplWhlRear_Tq_RqMn 1;
BA_ "U_CD542_MY2021_Tx" SG_ 532 PrplWhlRear_Tq_RqMn 1;
BA_ "U_U55X_MY2022_Tx" SG_ 532 PrplWhlRear_Tq_RqMn 1;
BA_ "GenSigStartValueInteger" SG_ 1264 ElCmpr2Ain_U_Actl 88;
BA_ "WakeupSignal" SG_ 531 PrkBrkMsgTxt_D_Rq 1;
BA_ "U_CD764_MY2022_Tx" SG_ 531 PrkBrkMsgTxt_D_Rq 1;
BA_ "U_CDX706_MY2023_Tx" SG_ 531 PrkBrkMsgTxt_D_Rq 1;
BA_ "GenSigStartValueInteger" SG_ 531 VehStop_D_Stat 2;
BA_ "GenSigStartValue" SG_ 531 VehStop_D_Stat 2;
BA_ "U_T6_MCA_MY2020_Rx" SG_ 531 VehStop_D_Stat 1;
BA_ "U_CD542_MY2021_Rx" SG_ 531 VehStop_D_Stat 1;
BA_ "U_U55X_MY2022_Rx" SG_ 531 VehStop_D_Stat 1;
BA_ "U_CD764_MY2022_Rx" SG_ 531 VehStop_D_Stat 1;
BA_ "U_CDX706_MY2023_Rx" SG_ 531 VehStop_D_Stat 1;
BA_ "U_CX727_MY2021_Tx" SG_ 531 VehStop_D_Stat 1;
BA_ "U_P702_MY2021_Tx" SG_ 531 VehStop_D_Stat 1;
BA_ "U_T6_MCA_MY2020_Tx" SG_ 531 VehStop_D_Stat 1;
BA_ "U_CD542_MY2021_Tx" SG_ 531 VehStop_D_Stat 1;
BA_ "U_U55X_MY2022_Tx" SG_ 531 VehStop_D_Stat 1;
BA_ "U_CD764_MY2022_Tx" SG_ 531 VehStop_D_Stat 1;
BA_ "U_CDX706_MY2023_Tx" SG_ 531 VehStop_D_Stat 1;
BA_ "U_CX727_MY2021_Rx" SG_ 531 TracCtlPtActv_B_Actl 1;
BA_ "U_P702_MY2021_Rx" SG_ 531 TracCtlPtActv_B_Actl 1;
BA_ "U_T6_MCA_MY2020_Rx" SG_ 531 TracCtlPtActv_B_Actl 1;
BA_ "ECGUsedRxSignal" SG_ 531 TracCtlPtActv_B_Actl 1;
BA_ "U_CD542_MY2021_Rx" SG_ 531 TracCtlPtActv_B_Actl 1;
BA_ "U_U55X_MY2022_Rx" SG_ 531 TracCtlPtActv_B_Actl 1;
BA_ "U_CD764_MY2022_Rx" SG_ 531 TracCtlPtActv_B_Actl 1;
BA_ "U_CDX706_MY2023_Rx" SG_ 531 TracCtlPtActv_B_Actl 1;
BA_ "U_CX727_MY2021_Tx" SG_ 531 TracCtlPtActv_B_Actl 1;
BA_ "U_P702_MY2021_Tx" SG_ 531 TracCtlPtActv_B_Actl 1;
BA_ "U_T6_MCA_MY2020_Tx" SG_ 531 TracCtlPtActv_B_Actl 1;
BA_ "U_CD542_MY2021_Tx" SG_ 531 TracCtlPtActv_B_Actl 1;
BA_ "U_U55X_MY2022_Tx" SG_ 531 TracCtlPtActv_B_Actl 1;
BA_ "U_CD764_MY2022_Tx" SG_ 531 TracCtlPtActv_B_Actl 1;
BA_ "U_CDX706_MY2023_Tx" SG_ 531 TracCtlPtActv_B_Actl 1;
BA_ "U_P702_MY2021_Tx" SG_ 531 LscmbbMntr_B_Err 1;
BA_ "U_T6_MCA_MY2020_Tx" SG_ 531 LscmbbMntr_B_Err 1;
BA_ "U_U55X_MY2022_Tx" SG_ 531 LscmbbMntr_B_Err 1;
BA_ "U_P702_MY2021_Tx" SG_ 531 LscmbbBrkDis_B_Actl 1;
BA_ "U_T6_MCA_MY2020_Tx" SG_ 531 LscmbbBrkDis_B_Actl 1;
BA_ "U_U55X_MY2022_Tx" SG_ 531 LscmbbBrkDis_B_Actl 1;
BA_ "U_CDX706_MY2023_Rx" SG_ 531 LscmbbDeny_B_ActlBrk 1;
BA_ "U_P702_MY2021_Tx" SG_ 531 LscmbbDeny_B_ActlBrk 1;
BA_ "U_T6_MCA_MY2020_Tx" SG_ 531 LscmbbDeny_B_ActlBrk 1;
BA_ "U_U55X_MY2022_Tx" SG_ 531 LscmbbDeny_B_ActlBrk 1;
BA_ "U_T6_MCA_MY2020_Rx" SG_ 531 VehicleStationary 1;
BA_ "U_CX727_MY2021_Tx" SG_ 531 VehicleStationary 1;
BA_ "U_T6_MCA_MY2020_Tx" SG_ 531 VehicleStationary 1;
BA_ "U_CD542_MY2021_Tx" SG_ 531 VehicleStationary 1;
BA_ "U_CD764_MY2022_Tx" SG_ 531 VehicleStationary 1;
BA_ "U_CDX706_MY2023_Tx" SG_ 531 VehicleStationary 1;
BA_ "U_P702_MY2021_Tx" SG_ 531 LscmbbBrkDecel_B_Actl 1;
BA_ "U_T6_MCA_MY2020_Tx" SG_ 531 LscmbbBrkDecel_B_Actl 1;
BA_ "U_U55X_MY2022_Tx" SG_ 531 LscmbbBrkDecel_B_Actl 1;
BA_ "U_CX727_MY2021_Rx" SG_ 531 AbsActv_B_Actl 1;
BA_ "U_P702_MY2021_Rx" SG_ 531 AbsActv_B_Actl 1;
BA_ "U_T6_MCA_MY2020_Rx" SG_ 531 AbsActv_B_Actl 1;
BA_ "U_CD542_MY2021_Rx" SG_ 531 AbsActv_B_Actl 1;
BA_ "U_U55X_MY2022_Rx" SG_ 531 AbsActv_B_Actl 1;
BA_ "U_CD764_MY2022_Rx" SG_ 531 AbsActv_B_Actl 1;
BA_ "U_CDX706_MY2023_Rx" SG_ 531 AbsActv_B_Actl 1;
BA_ "U_CX727_MY2021_Tx" SG_ 531 AbsActv_B_Actl 1;
BA_ "U_P702_MY2021_Tx" SG_ 531 AbsActv_B_Actl 1;
BA_ "U_T6_MCA_MY2020_Tx" SG_ 531 AbsActv_B_Actl 1;
BA_ "U_CD542_MY2021_Tx" SG_ 531 AbsActv_B_Actl 1;
BA_ "U_U55X_MY2022_Tx" SG_ 531 AbsActv_B_Actl 1;
BA_ "U_CD764_MY2022_Tx" SG_ 531 AbsActv_B_Actl 1;
BA_ "U_CDX706_MY2023_Tx" SG_ 531 AbsActv_B_Actl 1;
BA_ "U_CX727_MY2021_Rx" SG_ 531 StabCtlBrkActv_B_Actl 1;
BA_ "U_P702_MY2021_Rx" SG_ 531 StabCtlBrkActv_B_Actl 1;
BA_ "U_T6_MCA_MY2020_Rx" SG_ 531 StabCtlBrkActv_B_Actl 1;
BA_ "ECGUsedRxSignal" SG_ 531 StabCtlBrkActv_B_Actl 1;
BA_ "U_CD542_MY2021_Rx" SG_ 531 StabCtlBrkActv_B_Actl 1;
BA_ "U_U55X_MY2022_Rx" SG_ 531 StabCtlBrkActv_B_Actl 1;
BA_ "U_CD764_MY2022_Rx" SG_ 531 StabCtlBrkActv_B_Actl 1;
BA_ "U_CDX706_MY2023_Rx" SG_ 531 StabCtlBrkActv_B_Actl 1;
BA_ "U_CX727_MY2021_Tx" SG_ 531 StabCtlBrkActv_B_Actl 1;
BA_ "U_P702_MY2021_Tx" SG_ 531 StabCtlBrkActv_B_Actl 1;
BA_ "U_T6_MCA_MY2020_Tx" SG_ 531 StabCtlBrkActv_B_Actl 1;
BA_ "U_CD542_MY2021_Tx" SG_ 531 StabCtlBrkActv_B_Actl 1;
BA_ "U_U55X_MY2022_Tx" SG_ 531 StabCtlBrkActv_B_Actl 1;
BA_ "U_CD764_MY2022_Tx" SG_ 531 StabCtlBrkActv_B_Actl 1;
BA_ "U_CDX706_MY2023_Tx" SG_ 531 StabCtlBrkActv_B_Actl 1;
BA_ "U_T6_MCA_MY2020_Rx" SG_ 531 CmbbBrkPrchg_B_Actl 1;
BA_ "U_CD542_MY2021_Rx" SG_ 531 CmbbBrkPrchg_B_Actl 1;
BA_ "U_U55X_MY2022_Rx" SG_ 531 CmbbBrkPrchg_B_Actl 1;
BA_ "U_CD764_MY2022_Rx" SG_ 531 CmbbBrkPrchg_B_Actl 1;
BA_ "U_CDX706_MY2023_Rx" SG_ 531 CmbbBrkPrchg_B_Actl 1;
BA_ "U_CX727_MY2021_Tx" SG_ 531 CmbbBrkPrchg_B_Actl 1;
BA_ "U_P702_MY2021_Tx" SG_ 531 CmbbBrkPrchg_B_Actl 1;
BA_ "U_T6_MCA_MY2020_Tx" SG_ 531 CmbbBrkPrchg_B_Actl 1;
BA_ "U_CD542_MY2021_Tx" SG_ 531 CmbbBrkPrchg_B_Actl 1;
BA_ "U_U55X_MY2022_Tx" SG_ 531 CmbbBrkPrchg_B_Actl 1;
BA_ "U_CD764_MY2022_Tx" SG_ 531 CmbbBrkPrchg_B_Actl 1;
BA_ "U_CDX706_MY2023_Tx" SG_ 531 CmbbBrkPrchg_B_Actl 1;
BA_ "U_T6_MCA_MY2020_Rx" SG_ 531 CmbbBrkDecel_B_Actl 1;
BA_ "U_CD542_MY2021_Rx" SG_ 531 CmbbBrkDecel_B_Actl 1;
BA_ "U_U55X_MY2022_Rx" SG_ 531 CmbbBrkDecel_B_Actl 1;
BA_ "U_CD764_MY2022_Rx" SG_ 531 CmbbBrkDecel_B_Actl 1;
BA_ "U_CDX706_MY2023_Rx" SG_ 531 CmbbBrkDecel_B_Actl 1;
BA_ "U_CX727_MY2021_Tx" SG_ 531 CmbbBrkDecel_B_Actl 1;
BA_ "U_P702_MY2021_Tx" SG_ 531 CmbbBrkDecel_B_Actl 1;
BA_ "U_T6_MCA_MY2020_Tx" SG_ 531 CmbbBrkDecel_B_Actl 1;
BA_ "U_CD542_MY2021_Tx" SG_ 531 CmbbBrkDecel_B_Actl 1;
BA_ "U_U55X_MY2022_Tx" SG_ 531 CmbbBrkDecel_B_Actl 1;
BA_ "U_CD764_MY2022_Tx" SG_ 531 CmbbBrkDecel_B_Actl 1;
BA_ "U_CDX706_MY2023_Tx" SG_ 531 CmbbBrkDecel_B_Actl 1;
BA_ "U_T6_MCA_MY2020_Rx" SG_ 531 CmbbBaSensInc_B_Actl 1;
BA_ "U_CD542_MY2021_Rx" SG_ 531 CmbbBaSensInc_B_Actl 1;
BA_ "U_U55X_MY2022_Rx" SG_ 531 CmbbBaSensInc_B_Actl 1;
BA_ "U_CD764_MY2022_Rx" SG_ 531 CmbbBaSensInc_B_Actl 1;
BA_ "U_CDX706_MY2023_Rx" SG_ 531 CmbbBaSensInc_B_Actl 1;
BA_ "U_CX727_MY2021_Tx" SG_ 531 CmbbBaSensInc_B_Actl 1;
BA_ "U_P702_MY2021_Tx" SG_ 531 CmbbBaSensInc_B_Actl 1;
BA_ "U_T6_MCA_MY2020_Tx" SG_ 531 CmbbBaSensInc_B_Actl 1;
BA_ "U_CD542_MY2021_Tx" SG_ 531 CmbbBaSensInc_B_Actl 1;
BA_ "U_U55X_MY2022_Tx" SG_ 531 CmbbBaSensInc_B_Actl 1;
BA_ "U_CD764_MY2022_Tx" SG_ 531 CmbbBaSensInc_B_Actl 1;
BA_ "U_CDX706_MY2023_Tx" SG_ 531 CmbbBaSensInc_B_Actl 1;
BA_ "U_T6_MCA_MY2020_Rx" SG_ 531 AccBrkWarm_B_Actl 1;
BA_ "U_CD542_MY2021_Rx" SG_ 531 AccBrkWarm_B_Actl 1;
BA_ "U_U55X_MY2022_Rx" SG_ 531 AccBrkWarm_B_Actl 1;
BA_ "U_CD764_MY2022_Rx" SG_ 531 AccBrkWarm_B_Actl 1;
BA_ "U_CDX706_MY2023_Rx" SG_ 531 AccBrkWarm_B_Actl 1;
BA_ "U_CX727_MY2021_Tx" SG_ 531 AccBrkWarm_B_Actl 1;
BA_ "U_P702_MY2021_Tx" SG_ 531 AccBrkWarm_B_Actl 1;
BA_ "U_T6_MCA_MY2020_Tx" SG_ 531 AccBrkWarm_B_Actl 1;
BA_ "U_CD542_MY2021_Tx" SG_ 531 AccBrkWarm_B_Actl 1;
BA_ "U_U55X_MY2022_Tx" SG_ 531 AccBrkWarm_B_Actl 1;
BA_ "U_CD764_MY2022_Tx" SG_ 531 AccBrkWarm_B_Actl 1;
BA_ "U_CDX706_MY2023_Tx" SG_ 531 AccBrkWarm_B_Actl 1;
BA_ "U_T6_MCA_MY2020_Rx" SG_ 531 AccBrkTotTqMn_B_Actl 1;
BA_ "U_CD542_MY2021_Rx" SG_ 531 AccBrkTotTqMn_B_Actl 1;
BA_ "U_U55X_MY2022_Rx" SG_ 531 AccBrkTotTqMn_B_Actl 1;
BA_ "U_CD764_MY2022_Rx" SG_ 531 AccBrkTotTqMn_B_Actl 1;
BA_ "U_CDX706_MY2023_Rx" SG_ 531 AccBrkTotTqMn_B_Actl 1;
BA_ "U_CX727_MY2021_Tx" SG_ 531 AccBrkTotTqMn_B_Actl 1;
BA_ "U_P702_MY2021_Tx" SG_ 531 AccBrkTotTqMn_B_Actl 1;
BA_ "U_T6_MCA_MY2020_Tx" SG_ 531 AccBrkTotTqMn_B_Actl 1;
BA_ "U_CD542_MY2021_Tx" SG_ 531 AccBrkTotTqMn_B_Actl 1;
BA_ "U_U55X_MY2022_Tx" SG_ 531 AccBrkTotTqMn_B_Actl 1;
BA_ "U_CD764_MY2022_Tx" SG_ 531 AccBrkTotTqMn_B_Actl 1;
BA_ "U_CDX706_MY2023_Tx" SG_ 531 AccBrkTotTqMn_B_Actl 1;
BA_ "U_T6_MCA_MY2020_Rx" SG_ 531 AccBrkPrchgActv_B_Actl 1;
BA_ "U_CD542_MY2021_Rx" SG_ 531 AccBrkPrchgActv_B_Actl 1;
BA_ "U_U55X_MY2022_Rx" SG_ 531 AccBrkPrchgActv_B_Actl 1;
BA_ "U_CD764_MY2022_Rx" SG_ 531 AccBrkPrchgActv_B_Actl 1;
BA_ "U_CDX706_MY2023_Rx" SG_ 531 AccBrkPrchgActv_B_Actl 1;
BA_ "U_CX727_MY2021_Tx" SG_ 531 AccBrkPrchgActv_B_Actl 1;
BA_ "U_P702_MY2021_Tx" SG_ 531 AccBrkPrchgActv_B_Actl 1;
BA_ "U_T6_MCA_MY2020_Tx" SG_ 531 AccBrkPrchgActv_B_Actl 1;
BA_ "U_CD542_MY2021_Tx" SG_ 531 AccBrkPrchgActv_B_Actl 1;
BA_ "U_U55X_MY2022_Tx" SG_ 531 AccBrkPrchgActv_B_Actl 1;
BA_ "U_CD764_MY2022_Tx" SG_ 531 AccBrkPrchgActv_B_Actl 1;
BA_ "U_CDX706_MY2023_Tx" SG_ 531 AccBrkPrchgActv_B_Actl 1;
BA_ "U_T6_MCA_MY2020_Rx" SG_ 531 AccBrkDis_B_Actl 1;
BA_ "U_CD542_MY2021_Rx" SG_ 531 AccBrkDis_B_Actl 1;
BA_ "U_U55X_MY2022_Rx" SG_ 531 AccBrkDis_B_Actl 1;
BA_ "U_CD764_MY2022_Rx" SG_ 531 AccBrkDis_B_Actl 1;
BA_ "U_CDX706_MY2023_Rx" SG_ 531 AccBrkDis_B_Actl 1;
BA_ "U_CX727_MY2021_Tx" SG_ 531 AccBrkDis_B_Actl 1;
BA_ "U_P702_MY2021_Tx" SG_ 531 AccBrkDis_B_Actl 1;
BA_ "U_T6_MCA_MY2020_Tx" SG_ 531 AccBrkDis_B_Actl 1;
BA_ "U_CD542_MY2021_Tx" SG_ 531 AccBrkDis_B_Actl 1;
BA_ "U_U55X_MY2022_Tx" SG_ 531 AccBrkDis_B_Actl 1;
BA_ "U_CD764_MY2022_Tx" SG_ 531 AccBrkDis_B_Actl 1;
BA_ "U_CDX706_MY2023_Tx" SG_ 531 AccBrkDis_B_Actl 1;
BA_ "U_CX727_MY2021_Rx" SG_ 531 AccBrkDeny_B_Actl 1;
BA_ "U_P702_MY2021_Rx" SG_ 531 AccBrkDeny_B_Actl 1;
BA_ "U_T6_MCA_MY2020_Rx" SG_ 531 AccBrkDeny_B_Actl 1;
BA_ "U_CD542_MY2021_Rx" SG_ 531 AccBrkDeny_B_Actl 1;
BA_ "U_U55X_MY2022_Rx" SG_ 531 AccBrkDeny_B_Actl 1;
BA_ "U_CD764_MY2022_Rx" SG_ 531 AccBrkDeny_B_Actl 1;
BA_ "U_CDX706_MY2023_Rx" SG_ 531 AccBrkDeny_B_Actl 1;
BA_ "U_CX727_MY2021_Tx" SG_ 531 AccBrkDeny_B_Actl 1;
BA_ "U_P702_MY2021_Tx" SG_ 531 AccBrkDeny_B_Actl 1;
BA_ "U_T6_MCA_MY2020_Tx" SG_ 531 AccBrkDeny_B_Actl 1;
BA_ "U_CD542_MY2021_Tx" SG_ 531 AccBrkDeny_B_Actl 1;
BA_ "U_U55X_MY2022_Tx" SG_ 531 AccBrkDeny_B_Actl 1;
BA_ "U_CD764_MY2022_Tx" SG_ 531 AccBrkDeny_B_Actl 1;
BA_ "U_CDX706_MY2023_Tx" SG_ 531 AccBrkDeny_B_Actl 1;
BA_ "U_P702_MY2021_Rx" SG_ 531 AccBrkActv_B_Actl 1;
BA_ "U_T6_MCA_MY2020_Rx" SG_ 531 AccBrkActv_B_Actl 1;
BA_ "U_CD542_MY2021_Rx" SG_ 531 AccBrkActv_B_Actl 1;
BA_ "U_U55X_MY2022_Rx" SG_ 531 AccBrkActv_B_Actl 1;
BA_ "U_CD764_MY2022_Rx" SG_ 531 AccBrkActv_B_Actl 1;
BA_ "U_CDX706_MY2023_Rx" SG_ 531 AccBrkActv_B_Actl 1;
BA_ "U_CX727_MY2021_Tx" SG_ 531 AccBrkActv_B_Actl 1;
BA_ "U_P702_MY2021_Tx" SG_ 531 AccBrkActv_B_Actl 1;
BA_ "U_T6_MCA_MY2020_Tx" SG_ 531 AccBrkActv_B_Actl 1;
BA_ "U_CD542_MY2021_Tx" SG_ 531 AccBrkActv_B_Actl 1;
BA_ "U_U55X_MY2022_Tx" SG_ 531 AccBrkActv_B_Actl 1;
BA_ "U_CD764_MY2022_Tx" SG_ 531 AccBrkActv_B_Actl 1;
BA_ "U_CDX706_MY2023_Tx" SG_ 531 AccBrkActv_B_Actl 1;
BA_ "U_CX727_MY2021_Rx" SG_ 531 PrplDrgCtlActv_B_Actl 1;
BA_ "U_P702_MY2021_Rx" SG_ 531 PrplDrgCtlActv_B_Actl 1;
BA_ "U_T6_MCA_MY2020_Rx" SG_ 531 PrplDrgCtlActv_B_Actl 1;
BA_ "U_CD542_MY2021_Rx" SG_ 531 PrplDrgCtlActv_B_Actl 1;
BA_ "U_U55X_MY2022_Rx" SG_ 531 PrplDrgCtlActv_B_Actl 1;
BA_ "U_CD764_MY2022_Rx" SG_ 531 PrplDrgCtlActv_B_Actl 1;
BA_ "U_CDX706_MY2023_Rx" SG_ 531 PrplDrgCtlActv_B_Actl 1;
BA_ "U_CX727_MY2021_Tx" SG_ 531 PrplDrgCtlActv_B_Actl 1;
BA_ "U_P702_MY2021_Tx" SG_ 531 PrplDrgCtlActv_B_Actl 1;
BA_ "U_T6_MCA_MY2020_Tx" SG_ 531 PrplDrgCtlActv_B_Actl 1;
BA_ "U_CD542_MY2021_Tx" SG_ 531 PrplDrgCtlActv_B_Actl 1;
BA_ "U_U55X_MY2022_Tx" SG_ 531 PrplDrgCtlActv_B_Actl 1;
BA_ "U_CD764_MY2022_Tx" SG_ 531 PrplDrgCtlActv_B_Actl 1;
BA_ "U_CDX706_MY2023_Tx" SG_ 531 PrplDrgCtlActv_B_Actl 1;
BA_ "U_CX727_MY2021_Rx" SG_ 531 PrplWhlTot_Tq_RqMx 1;
BA_ "U_P702_MY2021_Rx" SG_ 531 PrplWhlTot_Tq_RqMx 1;
BA_ "U_T6_MCA_MY2020_Rx" SG_ 531 PrplWhlTot_Tq_RqMx 1;
BA_ "U_CD542_MY2021_Rx" SG_ 531 PrplWhlTot_Tq_RqMx 1;
BA_ "U_U55X_MY2022_Rx" SG_ 531 PrplWhlTot_Tq_RqMx 1;
BA_ "U_CD764_MY2022_Rx" SG_ 531 PrplWhlTot_Tq_RqMx 1;
BA_ "U_CDX706_MY2023_Rx" SG_ 531 PrplWhlTot_Tq_RqMx 1;
BA_ "U_CX727_MY2021_Tx" SG_ 531 PrplWhlTot_Tq_RqMx 1;
BA_ "U_P702_MY2021_Tx" SG_ 531 PrplWhlTot_Tq_RqMx 1;
BA_ "U_T6_MCA_MY2020_Tx" SG_ 531 PrplWhlTot_Tq_RqMx 1;
BA_ "U_CD542_MY2021_Tx" SG_ 531 PrplWhlTot_Tq_RqMx 1;
BA_ "U_U55X_MY2022_Tx" SG_ 531 PrplWhlTot_Tq_RqMx 1;
BA_ "U_CD764_MY2022_Tx" SG_ 531 PrplWhlTot_Tq_RqMx 1;
BA_ "U_CDX706_MY2023_Tx" SG_ 531 PrplWhlTot_Tq_RqMx 1;
BA_ "U_P702_MY2021_Tx" SG_ 531 LscmbbBaSensInc_B_Actl 1;
BA_ "U_T6_MCA_MY2020_Tx" SG_ 531 LscmbbBaSensInc_B_Actl 1;
BA_ "U_U55X_MY2022_Tx" SG_ 531 LscmbbBaSensInc_B_Actl 1;
BA_ "U_CX727_MY2021_Rx" SG_ 531 CmbbBrkDis_B_Actl 1;
BA_ "U_P702_MY2021_Rx" SG_ 531 CmbbBrkDis_B_Actl 1;
BA_ "U_T6_MCA_MY2020_Rx" SG_ 531 CmbbBrkDis_B_Actl 1;
BA_ "U_CD542_MY2021_Rx" SG_ 531 CmbbBrkDis_B_Actl 1;
BA_ "U_U55X_MY2022_Rx" SG_ 531 CmbbBrkDis_B_Actl 1;
BA_ "U_CD764_MY2022_Rx" SG_ 531 CmbbBrkDis_B_Actl 1;
BA_ "U_CDX706_MY2023_Rx" SG_ 531 CmbbBrkDis_B_Actl 1;
BA_ "U_CX727_MY2021_Tx" SG_ 531 CmbbBrkDis_B_Actl 1;
BA_ "U_P702_MY2021_Tx" SG_ 531 CmbbBrkDis_B_Actl 1;
BA_ "U_T6_MCA_MY2020_Tx" SG_ 531 CmbbBrkDis_B_Actl 1;
BA_ "U_CD542_MY2021_Tx" SG_ 531 CmbbBrkDis_B_Actl 1;
BA_ "U_U55X_MY2022_Tx" SG_ 531 CmbbBrkDis_B_Actl 1;
BA_ "U_CD764_MY2022_Tx" SG_ 531 CmbbBrkDis_B_Actl 1;
BA_ "U_CDX706_MY2023_Tx" SG_ 531 CmbbBrkDis_B_Actl 1;
BA_ "U_CX727_MY2021_Rx" SG_ 531 CmbbDeny_B_ActlBrk 1;
BA_ "U_P702_MY2021_Rx" SG_ 531 CmbbDeny_B_ActlBrk 1;
BA_ "U_T6_MCA_MY2020_Rx" SG_ 531 CmbbDeny_B_ActlBrk 1;
BA_ "U_CD542_MY2021_Rx" SG_ 531 CmbbDeny_B_ActlBrk 1;
BA_ "U_U55X_MY2022_Rx" SG_ 531 CmbbDeny_B_ActlBrk 1;
BA_ "U_CD764_MY2022_Rx" SG_ 531 CmbbDeny_B_ActlBrk 1;
BA_ "U_CDX706_MY2023_Rx" SG_ 531 CmbbDeny_B_ActlBrk 1;
BA_ "U_CX727_MY2021_Tx" SG_ 531 CmbbDeny_B_ActlBrk 1;
BA_ "U_P702_MY2021_Tx" SG_ 531 CmbbDeny_B_ActlBrk 1;
BA_ "U_T6_MCA_MY2020_Tx" SG_ 531 CmbbDeny_B_ActlBrk 1;
BA_ "U_CD542_MY2021_Tx" SG_ 531 CmbbDeny_B_ActlBrk 1;
BA_ "U_U55X_MY2022_Tx" SG_ 531 CmbbDeny_B_ActlBrk 1;
BA_ "U_CD764_MY2022_Tx" SG_ 531 CmbbDeny_B_ActlBrk 1;
BA_ "U_CDX706_MY2023_Tx" SG_ 531 CmbbDeny_B_ActlBrk 1;
BA_ "U_CX727_MY2021_Rx" SG_ 531 CcDis_B_Cmd 1;
BA_ "U_P702_MY2021_Rx" SG_ 531 CcDis_B_Cmd 1;
BA_ "U_T6_MCA_MY2020_Rx" SG_ 531 CcDis_B_Cmd 1;
BA_ "U_CD542_MY2021_Rx" SG_ 531 CcDis_B_Cmd 1;
BA_ "U_U55X_MY2022_Rx" SG_ 531 CcDis_B_Cmd 1;
BA_ "U_CD764_MY2022_Rx" SG_ 531 CcDis_B_Cmd 1;
BA_ "U_CDX706_MY2023_Rx" SG_ 531 CcDis_B_Cmd 1;
BA_ "U_CX727_MY2021_Tx" SG_ 531 CcDis_B_Cmd 1;
BA_ "U_P702_MY2021_Tx" SG_ 531 CcDis_B_Cmd 1;
BA_ "U_T6_MCA_MY2020_Tx" SG_ 531 CcDis_B_Cmd 1;
BA_ "U_CD542_MY2021_Tx" SG_ 531 CcDis_B_Cmd 1;
BA_ "U_U55X_MY2022_Tx" SG_ 531 CcDis_B_Cmd 1;
BA_ "U_CD764_MY2022_Tx" SG_ 531 CcDis_B_Cmd 1;
BA_ "GenSigStartValueInteger" SG_ 531 VehLongOvrGnd_A_Est 511;
BA_ "U_P702_MY2021_Rx" SG_ 531 VehLongOvrGnd_A_Est 1;
BA_ "U_T6_MCA_MY2020_Rx" SG_ 531 VehLongOvrGnd_A_Est 1;
BA_ "U_CD542_MY2021_Rx" SG_ 531 VehLongOvrGnd_A_Est 1;
BA_ "U_U55X_MY2022_Rx" SG_ 531 VehLongOvrGnd_A_Est 1;
BA_ "U_CD764_MY2022_Rx" SG_ 531 VehLongOvrGnd_A_Est 1;
BA_ "U_CDX706_MY2023_Rx" SG_ 531 VehLongOvrGnd_A_Est 1;
BA_ "U_CX727_MY2021_Tx" SG_ 531 VehLongOvrGnd_A_Est 1;
BA_ "U_P702_MY2021_Tx" SG_ 531 VehLongOvrGnd_A_Est 1;
BA_ "U_T6_MCA_MY2020_Tx" SG_ 531 VehLongOvrGnd_A_Est 1;
BA_ "U_CD542_MY2021_Tx" SG_ 531 VehLongOvrGnd_A_Est 1;
BA_ "U_U55X_MY2022_Tx" SG_ 531 VehLongOvrGnd_A_Est 1;
BA_ "U_CD764_MY2022_Tx" SG_ 531 VehLongOvrGnd_A_Est 1;
BA_ "U_CDX706_MY2023_Tx" SG_ 531 VehLongOvrGnd_A_Est 1;
BA_ "U_P702_MY2021_Tx" SG_ 531 LscmbBrkPrchg_B_Actl 1;
BA_ "U_T6_MCA_MY2020_Tx" SG_ 531 LscmbBrkPrchg_B_Actl 1;
BA_ "U_U55X_MY2022_Tx" SG_ 531 LscmbBrkPrchg_B_Actl 1;
BA_ "U_CX727_MY2021_Rx" SG_ 531 AccStopActv_B_ActlBrk 1;
BA_ "U_P702_MY2021_Rx" SG_ 531 AccStopActv_B_ActlBrk 1;
BA_ "U_T6_MCA_MY2020_Rx" SG_ 531 AccStopActv_B_ActlBrk 1;
BA_ "U_CD542_MY2021_Rx" SG_ 531 AccStopActv_B_ActlBrk 1;
BA_ "U_U55X_MY2022_Rx" SG_ 531 AccStopActv_B_ActlBrk 1;
BA_ "U_CD764_MY2022_Rx" SG_ 531 AccStopActv_B_ActlBrk 1;
BA_ "U_CDX706_MY2023_Rx" SG_ 531 AccStopActv_B_ActlBrk 1;
BA_ "U_CX727_MY2021_Tx" SG_ 531 AccStopActv_B_ActlBrk 1;
BA_ "U_P702_MY2021_Tx" SG_ 531 AccStopActv_B_ActlBrk 1;
BA_ "U_T6_MCA_MY2020_Tx" SG_ 531 AccStopActv_B_ActlBrk 1;
BA_ "U_CD542_MY2021_Tx" SG_ 531 AccStopActv_B_ActlBrk 1;
BA_ "U_U55X_MY2022_Tx" SG_ 531 AccStopActv_B_ActlBrk 1;
BA_ "U_CD764_MY2022_Tx" SG_ 531 AccStopActv_B_ActlBrk 1;
BA_ "U_CDX706_MY2023_Tx" SG_ 531 AccStopActv_B_ActlBrk 1;
BA_ "U_T6_MCA_MY2020_Rx" SG_ 531 AccDis_B_ActlEpb 1;
BA_ "U_CD542_MY2021_Rx" SG_ 531 AccDis_B_ActlEpb 1;
BA_ "U_U55X_MY2022_Rx" SG_ 531 AccDis_B_ActlEpb 1;
BA_ "U_CD764_MY2022_Rx" SG_ 531 AccDis_B_ActlEpb 1;
BA_ "U_CDX706_MY2023_Rx" SG_ 531 AccDis_B_ActlEpb 1;
BA_ "U_CX727_MY2021_Tx" SG_ 531 AccDis_B_ActlEpb 1;
BA_ "U_P702_MY2021_Tx" SG_ 531 AccDis_B_ActlEpb 1;
BA_ "U_T6_MCA_MY2020_Tx" SG_ 531 AccDis_B_ActlEpb 1;
BA_ "U_CD542_MY2021_Tx" SG_ 531 AccDis_B_ActlEpb 1;
BA_ "U_U55X_MY2022_Tx" SG_ 531 AccDis_B_ActlEpb 1;
BA_ "U_CD764_MY2022_Tx" SG_ 531 AccDis_B_ActlEpb 1;
BA_ "U_CDX706_MY2023_Tx" SG_ 531 AccDis_B_ActlEpb 1;
BA_ "GenSigStartValueInteger" SG_ 531 PrkBrkStatus 7;
BA_ "GenSigStartValue" SG_ 531 PrkBrkStatus 7;
BA_ "U_CX727_MY2021_Rx" SG_ 531 PrkBrkStatus 1;
BA_ "U_P702_MY2021_Rx" SG_ 531 PrkBrkStatus 1;
BA_ "U_T6_MCA_MY2020_Rx" SG_ 531 PrkBrkStatus 1;
BA_ "ECGUsedRxSignal" SG_ 531 PrkBrkStatus 1;
BA_ "U_CD542_MY2021_Rx" SG_ 531 PrkBrkStatus 1;
BA_ "U_U55X_MY2022_Rx" SG_ 531 PrkBrkStatus 1;
BA_ "U_CD764_MY2022_Rx" SG_ 531 PrkBrkStatus 1;
BA_ "U_CDX706_MY2023_Rx" SG_ 531 PrkBrkStatus 1;
BA_ "U_CX727_MY2021_Tx" SG_ 531 PrkBrkStatus 1;
BA_ "U_P702_MY2021_Tx" SG_ 531 PrkBrkStatus 1;
BA_ "U_T6_MCA_MY2020_Tx" SG_ 531 PrkBrkStatus 1;
BA_ "U_CD542_MY2021_Tx" SG_ 531 PrkBrkStatus 1;
BA_ "U_U55X_MY2022_Tx" SG_ 531 PrkBrkStatus 1;
BA_ "U_CD764_MY2022_Tx" SG_ 531 PrkBrkStatus 1;
BA_ "U_CDX706_MY2023_Tx" SG_ 531 PrkBrkStatus 1;
BA_ "WakeupSignal" SG_ 531 PrkBrkYwLamp_D_Rq 1;
BA_ "U_CD764_MY2022_Tx" SG_ 531 PrkBrkYwLamp_D_Rq 1;
BA_ "U_CDX706_MY2023_Tx" SG_ 531 PrkBrkYwLamp_D_Rq 1;
BA_ "WakeupSignal" SG_ 531 PrkBrkRedLamp_D_Rq 1;
BA_ "U_CD764_MY2022_Tx" SG_ 531 PrkBrkRedLamp_D_Rq 1;
BA_ "U_CDX706_MY2023_Tx" SG_ 531 PrkBrkRedLamp_D_Rq 1;
BA_ "GenSigStartValueInteger" SG_ 136 SteWhlBrkOffst_An_Rq 32766;
BA_ "GenSigStartValue" SG_ 136 SteWhlBrkOffst_An_Rq 32765;
BA_ "U_P702_MY2021_Tx" SG_ 136 SteWhlBrkOffst_An_Rq 1;
BA_ "U_T6_MCA_MY2020_Tx" SG_ 136 SteWhlBrkOffst_An_Rq 1;
BA_ "U_CDX706_MY2023_Tx" SG_ 136 SteWhlBrkOffst_An_Rq 1;
BA_ "MetaData" SG_ 136 SteWhlBrkAnRq_No_Cs 1;
BA_ "U_P702_MY2021_Tx" SG_ 136 SteWhlBrkAnRq_No_Cs 1;
BA_ "U_T6_MCA_MY2020_Tx" SG_ 136 SteWhlBrkAnRq_No_Cs 1;
BA_ "U_CDX706_MY2023_Tx" SG_ 136 SteWhlBrkAnRq_No_Cs 1;
BA_ "MetaData" SG_ 136 SteWhlBrkAnRq_No_Cnt 1;
BA_ "U_P702_MY2021_Tx" SG_ 136 SteWhlBrkAnRq_No_Cnt 1;
BA_ "U_T6_MCA_MY2020_Tx" SG_ 136 SteWhlBrkAnRq_No_Cnt 1;
BA_ "U_CDX706_MY2023_Tx" SG_ 136 SteWhlBrkAnRq_No_Cnt 1;
VAL_ 611 AwdTerrMdeChng_D_Rdy 7 "Fault" 6 "Undefined_2" 5 "Undefined_1" 4 "ModeUnavailDrInputRqd" 3 "SpOpModes_NotSupported" 2 "ModeUnavailDynamicCond" 1 "Module_In_Initialization" 0 "Mode_Change_Available" ;
VAL_ 611 AwdTerrMde_D_Actl 7 "Fail_Safe_Default" 6 "Dynamic_Mode" 5 "Rock_Crawl_Mode" 4 "Mud_Ruts_Mode" 3 "Sand_Mode" 2 "Undefined" 1 "Low_Mu_Mode" 0 "Special_Operating_Mode_Off" ;
VAL_ 611 AwdSys_D_Stat 3 "Faulty" 2 "NotUsed" 1 "_4x4_L_H_Active" 0 "_4x4_L_H_Inactive" ;
VAL_ 611 SelDrvMdeAwd_D_Stat 0 "NotAvailable" 1 "Available" 2 "TemporarilyNotAvailable" 3 "Faulty" ;
VAL_ 611 AwdStat_D_RqDsply 31 "Rear_Diff_Lock_Not_Avail" 30 "_4wd_Lock_Required" 29 "Cfg_Perf_Redc_See_Manual" 28 "To_Engage_4x4_Release_Aped" 27 "To_Engage_4x4_Slow_To_3MPH" 26 "Shift_To_Neutral" 25 "Lkr_Mode_Unavail_TMS" 24 " _4x4_Mode_Unavail_TMS" 23 "Out_of_4Low_Crawl" 22 "AWD_PTU_Oil_Changed" 21 "Change_AWD_PTU_Oil" 20 "Neutral_Tow_Disabled" 19 "Neutral_Tow_Enabled" 18 "AWD_OFF" 17 "_4x4_Off_Road_Speed" 16 "_4x4_Extreme_Off_Road_Mode" 15 "_4x4_Exiting_Off_Road" 14 "_4x4_Off_Road_Mode" 10 "_4x4_Locked_Temporarily" 9 "Shift_In_Progress" 13 "Blocked_Shift_Assist" 12 "_4x4_Auto_Restored" 11 "_4x4_Disabled_Temporarily" 7 "Out_of_4Low__Neutral" 6 "Out_of_4Low__Brake" 5 "Out_of_4Low__Speed" 4 "Into_4Low__Clutch" 3 "Into_4Low__Neutral" 2 "Into_4Low__Brake" 1 "Into_4Low__Speed" 0 "Normal__No_Message" 8 "Out_of_4Low__Clutch" ;
VAL_ 611 AwdLck_D_Stat 9 "Undefined" 8 "Under_External_Torque_Ctrl" 7 "Torque_Limited_by_Cmd" 6 "Fully_Locked_by_Cmd" 5 "Disabled" 4 "Warning" 3 "Fault" 2 "Inactive" 1 "Completely_Opened_by_Cmd" 0 "OK" ;
VAL_ 611 AwdSrvcRqd_B_Rq 1 "On" 0 "Off" ;
VAL_ 611 AwdDrvMde_D_Stat 7 "Faulty" 6 "NotAvailable" 5 "RockCrawl" 4 "Baja" 3 "MudAndSand" 2 "Weather" 1 "Sport" 0 "Normal" ;
VAL_ 611 NtrlTowAvail_B_Stat 1 "Available" 0 "NotAvailable" ;
VAL_ 611 AwdLck_Tq_Rq 4095 "Fault" 4094 "Unknown" ;
VAL_ 611 AwdOffRoadMode_D_Stats 3 "Invalid" 2 "Extreme_Off_Road" 1 "Off_Road" 0 "Normal_Mode" ;
VAL_ 611 AwdLoLamp_D_RqDsply 3 "Not_Used" 2 "Flash" 1 "On" 0 "Off" ;
VAL_ 611 AwdHiLamp_D_RqDsply 3 "Not_Used" 2 "Flash" 1 "On" 0 "Off" ;
VAL_ 611 AwdAutoLamp_D_RqDsply 3 "Not_Used" 2 "Flash" 1 "On" 0 "Off" ;
VAL_ 611 Awd2wdLamp_D_RqDsply 3 "Not_Used" 2 "Flash" 1 "On" 0 "Off" ;
VAL_ 611 AwdRnge_D_Actl 7 "Unknown" 6 "High_Range_2wd" 5 "High_Range_Auto" 4 "High_Range_Locked" 3 "Neutral" 2 "Low_Range_2wd" 1 "Low_Range_Auto" 0 "Low_Range_Locked" ;
VAL_ 1047 TrlrAidSetup_D2_Stat 7 "NotUsed_2" 6 "NotUsed_1" 5 "SetupAcquisitionSuccess" 4 "TbaTadMonitor" 3 "SetupStartAcquisition" 2 "SetupPrepForAcquisition" 1 "TbaActive" 0 "Null" ;
VAL_ 1047 TrlrAidEnbl_D2_Stat 7 "NotUsed_1" 6 "TbaActiveExpertActive" 5 "TbaActiveExpertAvail" 4 "TbaOffTrgActive" 3 "TbaOffTrgSetup" 2 "TbaSetup" 1 "TbaActive" 0 "Inactive" ;
VAL_ 1047 TrlrAidMsgTxt_D2_Rq 63 "Message63" 62 "Message62" 61 "Message61" 60 "Message60" 55 "Message55" 50 "Message50" 45 "Message45" 40 "Message40" 35 "Message35" 31 "Message31" 30 "Message30" 29 "Message29" 28 "Message28" 27 "Message27" 26 "Message26" 25 "Message25" 24 "Message24" 23 "Message23" 22 "Message22" 21 "Message21" 20 "Message20" 19 "Message19" 18 "Message18" 17 "Message17" 16 "Message16" 15 "Message15" 14 "Message14" 13 "Message13" 12 "Message12" 11 "Message11" 10 "Message10" 9 "Message9" 8 "Message8" 7 "Message7" 6 "Message6" 5 "Message5" 4 "Message4" 3 "Message3" 2 "Message2" 1 "Message1" 0 "NoMessage" ;
VAL_ 1047 EsaOn_B_Stat 1 "On" 0 "Off" ;
VAL_ 1047 SelDrvMdeSte_D_Stat 0 "NotAvailable" 1 "Available" 2 "TemporarilyNotAvailable" 3 "Faulty" ;
VAL_ 972 LsmcBrkDecelEnbl_D_Rq 3 "NotUsed2" 2 "NotUsed1" 1 "On" 0 "Off" ;
VAL_ 972 TjaHandsOnCnfdnc_B_Est 1 "High_Confidence" 0 "Low_Confidence" ;
VAL_ 972 LaHandsOff_B_Actl 1 "Hands_Off" 0 "Hands_On" ;
VAL_ 972 LaActDeny_B_Actl 1 "LA_Denied" 0 "LA_Not_Denied" ;
VAL_ 972 LatCtlSte_D_Stat 7 "NotUsed3" 6 "NotUsed2" 5 "NotUsed1" 4 "Denied" 3 "RampOut" 2 "ContLatControlInProgress" 1 "Available" 0 "Unavailable" ;
VAL_ 972 LatCtlLim_D_Stat 3 "LimitWithDriverActive" 2 "LimitReached" 1 "LimitClose" 0 "LimitNotReached" ;
VAL_ 972 LatCtlCpblty_D_Stat 3 "Faulty" 2 "ExtendedModeAvailable" 1 "LimitedModeAvailable" 0 "NoModeAvailable" ;
VAL_ 972 LaActAvail_D2_Actl 3 "Intervention_Available" 2 "NoIntervention_Available" 1 "Intervention_NotAvailable" 0 "NoIntervention_NotAvailabl" ;
VAL_ 130 TrlrHitchLamp_D_Rqst 1 "On" 0 "Off" ;
VAL_ 130 VehVTrlrAid_B_Rq 1 "Request" 0 "NoRequest" ;
VAL_ 130 SteEffort_D_Stat 7 "NotUsed_3" 6 "NotUsed_2" 5 "NotUsed_1" 4 "SpecialMode_2" 3 "SpecialMode_1" 2 "Comfort" 1 "Sport" 0 "Normal" ;
VAL_ 130 DrvSteActv_B_Stat 1 "Active" 0 "Inactive" ;
VAL_ 130 DrvSte_Tq_Actl 255 "Invalid" 254 "Unknown" ;
VAL_ 130 SteMdule_D_Stat 7 "NotUsed" 6 "EPAS_Failure3" 5 "EPAS_Failure2" 4 "System_Failure" 3 "EPAS_Shutdown" 2 "Normal_Op_Full_Assist" 1 "Normal_Op_Limited_Assist" 0 "EPAS_Initialization" ;
VAL_ 130 SteMdule_U_Meas 255 "Invalid" ;
VAL_ 130 SteMdule_I_Est 4095 "Invalid" ;
VAL_ 130 EPAS_Failure 3 "SERVICE_POWER_STEERING_NOW" 2 "SERVICE_POWER_STEERING" 1 "POWER_STRG_ASSIST_FAULT" 0 "EPAS_OK_NO_MESSAGE" ;
VAL_ 130 SteeringColumnTorque 255 "Invalid" 254 "Unknown" ;
VAL_ 130 SAPPAngleControlStat6 1 "RequestedAngleNotReached" 0 "RequestedAngleCanBeReached" ;
VAL_ 130 SAPPAngleControlStat5 1 "StrgColTorqueExceed_EAROn" 0 "ExternalSigContentOKforEAC" ;
VAL_ 130 SAPPAngleControlStat4 1 "SpeedLimitExceededEAROn" 0 "ExternalSigContentOKforEAC" ;
VAL_ 130 SAPPAngleControlStat3 1 "EARactiveNoReverseEngage" 0 "ExternalSigContentOKforEAC" ;
VAL_ 130 SAPPAngleControlStat2 1 "Rel_ExtSteeringAngleReqx" 0 "NoRel_ExtSteeringAngleReqx" ;
VAL_ 130 SAPPAngleControlStat1 3 "Fault" 2 "Active" 1 "Open" 0 "Closed" ;
VAL_ 126 StePw_B_Rq 1 "Yes" 0 "No" ;
VAL_ 126 StePinRelInit_An_Sns 65535 "Faulty" 65534 "NoDataExists" ;
VAL_ 126 StePinCompAnEst_D_Qf 3 "OK" 2 "Degraded" 1 "No_Data_Exists" 0 "Faulty" ;
VAL_ 1200 BrkRearPCorrltn_B_Stat 1 "Yes" 0 "No" ;
VAL_ 1200 HsaTrnAout_Tq_Rq 65535 "Fault" 65534 "Unknown" ;
VAL_ 1200 BrkBstrVac_P_Actl 127 "Invalid" ;
VAL_ 1200 YawStabilityIndex 511 "Fault" 510 "NoDataExists" ;
VAL_ 1200 BrkTot_Tq_RqDrv 8191 "Fault" ;
VAL_ 1200 HsaStat_D_Dsply 7 "NotUsed3" 6 "NotUsed2" 5 "NotUsed1" 4 "NotAvailable" 3 "SlowReleaseWithChime" 2 "SlowReleaseWithoutChime" 1 "Active" 0 "Inactive" ;
VAL_ 1200 BrkHold_D_Stat 7 "NotUsed_3" 6 "NotUsed_2" 5 "NotUsed_1" 4 "HeldSecondary" 3 "HeldSecure" 2 "Held" 1 "Inactive" 0 "Off" ;
VAL_ 1102 SelDrvMdePos12_D_Stat 31 "Faulty" 30 "SelDrvMde31" 29 "SelDrvMde30" 28 "SelDrvMde29" 27 "SelDrvMde28" 26 "SelDrvMde27" 25 "SelDrvMde26" 24 "SelDrvMde25" 23 "SelDrvMde24" 22 "SelDrvMde23" 21 "SelDrvMde22" 20 "SelDrvMde21" 19 "SelDrvMde20" 18 "SelDrvMde19" 17 "SelDrvMde18" 16 "SelDrvMde17" 15 "SelDrvMde16" 14 "SelDrvMde15" 13 "SelDrvMde14" 12 "SelDrvMde13" 11 "SelDrvMde12" 10 "SelDrvMde11" 9 "SelDrvMde10" 8 "SelDrvMde09" 7 "SelDrvMde08" 6 "SelDrvMde07" 5 "SelDrvMde06" 4 "SelDrvMde05" 3 "SelDrvMde04" 2 "SelDrvMde03" 1 "SelDrvMde02" 0 "SelDrvMde01" ;
VAL_ 1102 SelDrvMdePos11_D_Stat 31 "Faulty" 30 "SelDrvMde31" 29 "SelDrvMde30" 28 "SelDrvMde29" 27 "SelDrvMde28" 26 "SelDrvMde27" 25 "SelDrvMde26" 24 "SelDrvMde25" 23 "SelDrvMde24" 22 "SelDrvMde23" 21 "SelDrvMde22" 20 "SelDrvMde21" 19 "SelDrvMde20" 18 "SelDrvMde19" 17 "SelDrvMde18" 16 "SelDrvMde17" 15 "SelDrvMde16" 14 "SelDrvMde15" 13 "SelDrvMde14" 12 "SelDrvMde13" 11 "SelDrvMde12" 10 "SelDrvMde11" 9 "SelDrvMde10" 8 "SelDrvMde09" 7 "SelDrvMde08" 6 "SelDrvMde07" 5 "SelDrvMde06" 4 "SelDrvMde05" 3 "SelDrvMde04" 2 "SelDrvMde03" 1 "SelDrvMde02" 0 "SelDrvMde01" ;
VAL_ 1102 SelDrvMdePos10_D_Stat 31 "Faulty" 30 "SelDrvMde31" 29 "SelDrvMde30" 28 "SelDrvMde29" 27 "SelDrvMde28" 26 "SelDrvMde27" 25 "SelDrvMde26" 24 "SelDrvMde25" 23 "SelDrvMde24" 22 "SelDrvMde23" 21 "SelDrvMde22" 20 "SelDrvMde21" 19 "SelDrvMde20" 18 "SelDrvMde19" 17 "SelDrvMde18" 16 "SelDrvMde17" 15 "SelDrvMde16" 14 "SelDrvMde15" 13 "SelDrvMde14" 12 "SelDrvMde13" 11 "SelDrvMde12" 10 "SelDrvMde11" 9 "SelDrvMde10" 8 "SelDrvMde09" 7 "SelDrvMde08" 6 "SelDrvMde07" 5 "SelDrvMde06" 4 "SelDrvMde05" 3 "SelDrvMde04" 2 "SelDrvMde03" 1 "SelDrvMde02" 0 "SelDrvMde01" ;
VAL_ 1102 SelDrvMdePos09_D_Stat 31 "Faulty" 30 "SelDrvMde31" 29 "SelDrvMde30" 28 "SelDrvMde29" 27 "SelDrvMde28" 26 "SelDrvMde27" 25 "SelDrvMde26" 24 "SelDrvMde25" 23 "SelDrvMde24" 22 "SelDrvMde23" 21 "SelDrvMde22" 20 "SelDrvMde21" 19 "SelDrvMde20" 18 "SelDrvMde19" 17 "SelDrvMde18" 16 "SelDrvMde17" 15 "SelDrvMde16" 14 "SelDrvMde15" 13 "SelDrvMde14" 12 "SelDrvMde13" 11 "SelDrvMde12" 10 "SelDrvMde11" 9 "SelDrvMde10" 8 "SelDrvMde09" 7 "SelDrvMde08" 6 "SelDrvMde07" 5 "SelDrvMde06" 4 "SelDrvMde05" 3 "SelDrvMde04" 2 "SelDrvMde03" 1 "SelDrvMde02" 0 "SelDrvMde01" ;
VAL_ 1102 SelDrvMdePos08_D_Stat 31 "Faulty" 30 "SelDrvMde31" 29 "SelDrvMde30" 28 "SelDrvMde29" 27 "SelDrvMde28" 26 "SelDrvMde27" 25 "SelDrvMde26" 24 "SelDrvMde25" 23 "SelDrvMde24" 22 "SelDrvMde23" 21 "SelDrvMde22" 20 "SelDrvMde21" 19 "SelDrvMde20" 18 "SelDrvMde19" 17 "SelDrvMde18" 16 "SelDrvMde17" 15 "SelDrvMde16" 14 "SelDrvMde15" 13 "SelDrvMde14" 12 "SelDrvMde13" 11 "SelDrvMde12" 10 "SelDrvMde11" 9 "SelDrvMde10" 8 "SelDrvMde09" 7 "SelDrvMde08" 6 "SelDrvMde07" 5 "SelDrvMde06" 4 "SelDrvMde05" 3 "SelDrvMde04" 2 "SelDrvMde03" 1 "SelDrvMde02" 0 "SelDrvMde01" ;
VAL_ 1102 SelDrvMdePos07_D_Stat 31 "Faulty" 30 "SelDrvMde31" 29 "SelDrvMde30" 28 "SelDrvMde29" 27 "SelDrvMde28" 26 "SelDrvMde27" 25 "SelDrvMde26" 24 "SelDrvMde25" 23 "SelDrvMde24" 22 "SelDrvMde23" 21 "SelDrvMde22" 20 "SelDrvMde21" 19 "SelDrvMde20" 18 "SelDrvMde19" 17 "SelDrvMde18" 16 "SelDrvMde17" 15 "SelDrvMde16" 14 "SelDrvMde15" 13 "SelDrvMde14" 12 "SelDrvMde13" 11 "SelDrvMde12" 10 "SelDrvMde11" 9 "SelDrvMde10" 8 "SelDrvMde09" 7 "SelDrvMde08" 6 "SelDrvMde07" 5 "SelDrvMde06" 4 "SelDrvMde05" 3 "SelDrvMde04" 2 "SelDrvMde03" 1 "SelDrvMde02" 0 "SelDrvMde01" ;
VAL_ 1102 SelDrvMdePos06_D_Stat 31 "Faulty" 30 "SelDrvMde31" 29 "SelDrvMde30" 28 "SelDrvMde29" 27 "SelDrvMde28" 26 "SelDrvMde27" 25 "SelDrvMde26" 24 "SelDrvMde25" 23 "SelDrvMde24" 22 "SelDrvMde23" 21 "SelDrvMde22" 20 "SelDrvMde21" 19 "SelDrvMde20" 18 "SelDrvMde19" 17 "SelDrvMde18" 16 "SelDrvMde17" 15 "SelDrvMde16" 14 "SelDrvMde15" 13 "SelDrvMde14" 12 "SelDrvMde13" 11 "SelDrvMde12" 10 "SelDrvMde11" 9 "SelDrvMde10" 8 "SelDrvMde09" 7 "SelDrvMde08" 6 "SelDrvMde07" 5 "SelDrvMde06" 4 "SelDrvMde05" 3 "SelDrvMde04" 2 "SelDrvMde03" 1 "SelDrvMde02" 0 "SelDrvMde01" ;
VAL_ 1102 SelDrvMdePos05_D_Stat 31 "Faulty" 30 "SelDrvMde31" 29 "SelDrvMde30" 28 "SelDrvMde29" 27 "SelDrvMde28" 26 "SelDrvMde27" 25 "SelDrvMde26" 24 "SelDrvMde25" 23 "SelDrvMde24" 22 "SelDrvMde23" 21 "SelDrvMde22" 20 "SelDrvMde21" 19 "SelDrvMde20" 18 "SelDrvMde19" 17 "SelDrvMde18" 16 "SelDrvMde17" 15 "SelDrvMde16" 14 "SelDrvMde15" 13 "SelDrvMde14" 12 "SelDrvMde13" 11 "SelDrvMde12" 10 "SelDrvMde11" 9 "SelDrvMde10" 8 "SelDrvMde09" 7 "SelDrvMde08" 6 "SelDrvMde07" 5 "SelDrvMde06" 4 "SelDrvMde05" 3 "SelDrvMde04" 2 "SelDrvMde03" 1 "SelDrvMde02" 0 "SelDrvMde01" ;
VAL_ 1102 SelDrvMdePos04_D_Stat 31 "Faulty" 30 "SelDrvMde31" 29 "SelDrvMde30" 28 "SelDrvMde29" 27 "SelDrvMde28" 26 "SelDrvMde27" 25 "SelDrvMde26" 24 "SelDrvMde25" 23 "SelDrvMde24" 22 "SelDrvMde23" 21 "SelDrvMde22" 20 "SelDrvMde21" 19 "SelDrvMde20" 18 "SelDrvMde19" 17 "SelDrvMde18" 16 "SelDrvMde17" 15 "SelDrvMde16" 14 "SelDrvMde15" 13 "SelDrvMde14" 12 "SelDrvMde13" 11 "SelDrvMde12" 10 "SelDrvMde11" 9 "SelDrvMde10" 8 "SelDrvMde09" 7 "SelDrvMde08" 6 "SelDrvMde07" 5 "SelDrvMde06" 4 "SelDrvMde05" 3 "SelDrvMde04" 2 "SelDrvMde03" 1 "SelDrvMde02" 0 "SelDrvMde01" ;
VAL_ 1102 SelDrvMdePos03_D_Stat 31 "Faulty" 30 "SelDrvMde31" 29 "SelDrvMde30" 28 "SelDrvMde29" 27 "SelDrvMde28" 26 "SelDrvMde27" 25 "SelDrvMde26" 24 "SelDrvMde25" 23 "SelDrvMde24" 22 "SelDrvMde23" 21 "SelDrvMde22" 20 "SelDrvMde21" 19 "SelDrvMde20" 18 "SelDrvMde19" 17 "SelDrvMde18" 16 "SelDrvMde17" 15 "SelDrvMde16" 14 "SelDrvMde15" 13 "SelDrvMde14" 12 "SelDrvMde13" 11 "SelDrvMde12" 10 "SelDrvMde11" 9 "SelDrvMde10" 8 "SelDrvMde09" 7 "SelDrvMde08" 6 "SelDrvMde07" 5 "SelDrvMde06" 4 "SelDrvMde05" 3 "SelDrvMde04" 2 "SelDrvMde03" 1 "SelDrvMde02" 0 "SelDrvMde01" ;
VAL_ 1102 SelDrvMdePos02_D_Stat 31 "Faulty" 30 "SelDrvMde31" 29 "SelDrvMde30" 28 "SelDrvMde29" 27 "SelDrvMde28" 26 "SelDrvMde27" 25 "SelDrvMde26" 24 "SelDrvMde25" 23 "SelDrvMde24" 22 "SelDrvMde23" 21 "SelDrvMde22" 20 "SelDrvMde21" 19 "SelDrvMde20" 18 "SelDrvMde19" 17 "SelDrvMde18" 16 "SelDrvMde17" 15 "SelDrvMde16" 14 "SelDrvMde15" 13 "SelDrvMde14" 12 "SelDrvMde13" 11 "SelDrvMde12" 10 "SelDrvMde11" 9 "SelDrvMde10" 8 "SelDrvMde09" 7 "SelDrvMde08" 6 "SelDrvMde07" 5 "SelDrvMde06" 4 "SelDrvMde05" 3 "SelDrvMde04" 2 "SelDrvMde03" 1 "SelDrvMde02" 0 "SelDrvMde01" ;
VAL_ 1102 SelDrvMdePos01_D_Stat 31 "Faulty" 30 "SelDrvMde31" 29 "SelDrvMde30" 28 "SelDrvMde29" 27 "SelDrvMde28" 26 "SelDrvMde27" 25 "SelDrvMde26" 24 "SelDrvMde25" 23 "SelDrvMde24" 22 "SelDrvMde23" 21 "SelDrvMde22" 20 "SelDrvMde21" 19 "SelDrvMde20" 18 "SelDrvMde19" 17 "SelDrvMde18" 16 "SelDrvMde17" 15 "SelDrvMde16" 14 "SelDrvMde15" 13 "SelDrvMde14" 12 "SelDrvMde13" 11 "SelDrvMde12" 10 "SelDrvMde11" 9 "SelDrvMde10" 8 "SelDrvMde09" 7 "SelDrvMde08" 6 "SelDrvMde07" 5 "SelDrvMde06" 4 "SelDrvMde05" 3 "SelDrvMde04" 2 "SelDrvMde03" 1 "SelDrvMde02" 0 "SelDrvMde01" ;
VAL_ 1056 AutoEpbButtnOn_B_Stat 1 "On" 0 "Off" ;
VAL_ 1056 VehVActlBrk_No_Corr 255 "Faulty" 254 "NoDataExists" ;
VAL_ 1056 AutoEpbMsgTxt_D_Rq 7 "Message7" 6 "Message6" 5 "Message5" 4 "Message4" 3 "Message3" 2 "Message2" 1 "Message1" 0 "NoMessage" ;
VAL_ 1056 SelDrvMdePos12_B_Avail 1 "Available" 0 "NotAvailable" ;
VAL_ 1056 SelDrvMdePos11_B_Avail 1 "Available" 0 "NotAvailable" ;
VAL_ 1056 SelDrvMdePos10_B_Avail 1 "Available" 0 "NotAvailable" ;
VAL_ 1056 SelDrvMdePos09_B_Avail 1 "Available" 0 "NotAvailable" ;
VAL_ 1056 SelDrvMdePos08_B_Avail 1 "Available" 0 "NotAvailable" ;
VAL_ 1056 SelDrvMdePos07_B_Avail 1 "Available" 0 "NotAvailable" ;
VAL_ 1056 SelDrvMdePos06_B_Avail 1 "Available" 0 "NotAvailable" ;
VAL_ 1056 SelDrvMdePos05_B_Avail 1 "Available" 0 "NotAvailable" ;
VAL_ 1056 SelDrvMdePos04_B_Avail 1 "Available" 0 "NotAvailable" ;
VAL_ 1056 SelDrvMdePos03_B_Avail 1 "Available" 0 "NotAvailable" ;
VAL_ 1056 SelDrvMdePos02_B_Avail 1 "Available" 0 "NotAvailable" ;
VAL_ 1056 SelDrvMdePos01_B_Avail 1 "Available" 0 "NotAvailable" ;
VAL_ 1056 ActvDrvMde_D2_Stat 31 "Faulty" 30 "SelDrvMde31" 29 "SelDrvMde30" 28 "SelDrvMde29" 27 "SelDrvMde28" 26 "SelDrvMde27" 25 "SelDrvMde26" 24 "SelDrvMde25" 23 "SelDrvMde24" 22 "SelDrvMde23" 21 "SelDrvMde22" 20 "SelDrvMde21" 19 "SelDrvMde20" 18 "SelDrvMde19" 17 "SelDrvMde18" 16 "SelDrvMde17" 15 "SelDrvMde16" 14 "SelDrvMde15" 13 "SelDrvMde14" 12 "SelDrvMde13" 11 "SelDrvMde12" 10 "SelDrvMde11" 9 "SelDrvMde10" 8 "SelDrvMde09" 7 "SelDrvMde08" 6 "SelDrvMde07" 5 "SelDrvMde06" 4 "SelDrvMde05" 3 "SelDrvMde04" 2 "SelDrvMde03" 1 "SelDrvMde02" 0 "SelDrvMde01" ;
VAL_ 1056 SelDrvMde_D2_Rq 31 "Faulty" 30 "SelDrvMde31" 29 "SelDrvMde30" 28 "SelDrvMde29" 27 "SelDrvMde28" 26 "SelDrvMde27" 25 "SelDrvMde26" 24 "SelDrvMde25" 23 "SelDrvMde24" 22 "SelDrvMde23" 21 "SelDrvMde22" 20 "SelDrvMde21" 19 "SelDrvMde20" 18 "SelDrvMde19" 17 "SelDrvMde18" 16 "SelDrvMde17" 15 "SelDrvMde16" 14 "SelDrvMde15" 13 "SelDrvMde14" 12 "SelDrvMde13" 11 "SelDrvMde12" 10 "SelDrvMde11" 9 "SelDrvMde10" 8 "SelDrvMde09" 7 "SelDrvMde08" 6 "SelDrvMde07" 5 "SelDrvMde06" 4 "SelDrvMde05" 3 "SelDrvMde04" 2 "SelDrvMde03" 1 "SelDrvMde02" 0 "SelDrvMde01" ;
VAL_ 1056 SelDrvMdePt_D_Rq 31 "Faulty" 30 "NotUsed15" 29 "NotUsed14" 28 "NotUsed13" 27 "NotUsed12" 26 "NotUsed11" 25 "NotUsed10" 24 "NotUsed9" 23 "NotUsed8" 22 "NotUsed7" 21 "CustomMode" 20 "TrackMode" 19 "OnePedalDrive" 18 "EvLaterChargerMode" 17 "EvNowMode" 16 "DragMode" 15 "HighSpeedDesertMode_Baja" 14 "SportAdaptiveMode" 13 "NotAvailable_13" 12 "NotAvailable_12" 11 "NotAvailable_11" 10 "NotAvailable_10" 9 "RockCrawlMode" 8 "MudRutsMode" 7 "SandMode" 6 "EconomyMode" 5 "GrassGravelSnow" 4 "NotAvailable_04" 3 "TowHaulMode" 2 "NotAvailable_02" 1 "SportMode" 0 "NormalMode" ;
VAL_ 1056 SelDrvMdeMsgTxt_D_Rq 15 "Message15" 14 "Message14" 13 "Message13" 12 "Message12" 11 "Message11" 10 "Message10" 9 "Message9" 8 "Message8" 7 "Message7" 6 "Message6" 5 "Message5" 4 "Message4" 3 "Message3" 2 "Message2" 1 "Message1" 0 "NoMessage" ;
VAL_ 1056 SelDrvMde_D_Stat 3 "NotUsed" 2 "DriveModeChangeRequest" 1 "DriveModeChangeSelection" 0 "NoDriveModeChangeRequest" ;
VAL_ 1056 AwdMde_D_RqBrk 7 "Faulty" 6 "NotUsed2" 5 "NoRequest" 4 "Neutral" 3 "FourByFourLow" 2 "FourByFourHigh" 1 "FourByFourAuto" 0 "FourByTwo" ;
VAL_ 1056 AutoEpbDsply_D_Stat 3 "NotUsed" 2 "GreyedOut" 1 "Available" 0 "NotAvailable" ;
VAL_ 1056 SelDrvMdeMsgTxt2_D_Rq 15 "Message15" 14 "Message14" 13 "Message13" 12 "Message12" 11 "Message11" 10 "Message10" 9 "Message9" 8 "Message8" 7 "Message7" 6 "Message6" 5 "Message5" 4 "Message4" 3 "Message3" 2 "Message2" 1 "Message1" 0 "NoMessage" ;
VAL_ 1056 SelDrvMdeHmi03_D_Rq 31 "Faulty" 30 "SelDrvMde31" 29 "SelDrvMde30" 28 "SelDrvMde29" 27 "SelDrvMde28" 26 "SelDrvMde27" 25 "SelDrvMde26" 24 "SelDrvMde25" 23 "SelDrvMde24" 22 "SelDrvMde23" 21 "SelDrvMde22" 20 "SelDrvMde21" 19 "SelDrvMde20" 18 "SelDrvMde19" 17 "SelDrvMde18" 16 "SelDrvMde17" 15 "SelDrvMde16" 14 "SelDrvMde15" 13 "SelDrvMde14" 12 "SelDrvMde13" 11 "SelDrvMde12" 10 "SelDrvMde11" 9 "SelDrvMde10" 8 "SelDrvMde09" 7 "SelDrvMde08" 6 "SelDrvMde07" 5 "SelDrvMde06" 4 "SelDrvMde05" 3 "SelDrvMde04" 2 "SelDrvMde03" 1 "SelDrvMde02" 0 "SelDrvMde01" ;
VAL_ 1054 RbaBrk_D_Stat 3 "Denied" 2 "Active" 1 "Open" 0 "Closed" ;
VAL_ 1054 SelDrvMdeChassis2_D_Rq 31 "Faulty" 30 "NotUsed17" 29 "NotUsed16" 28 "NotUsed15" 27 "NotUsed14" 26 "NotUsed13" 25 "NotUsed12" 24 "NotUsed11" 23 "NotUsed10" 22 "NotUsed9" 21 "NotUsed8" 20 "NotUsed7" 19 "NotUsed6" 18 "NotUsed5" 17 "NotUsed4" 16 "OnePedalDrive" 15 "DragMode" 14 "RoughRoadMode" 13 "TrackMode" 12 "HighSpeedDesertMode" 11 "TowHaulMode" 10 "RockCrawlMode" 9 "SandMode" 8 "MudAndRutsMode" 7 "LowMuMode" 6 "ComfortAdaptiveMode" 5 "ComfortMode" 4 "SportAdaptiveMode" 3 "SportMode" 2 "EconomyMode" 1 "NormalAdaptiveMode" 0 "NormalMode" ;
VAL_ 1054 BrkBstrLoLampOn_B_Rq 1 "On" 0 "Off" ;
VAL_ 1054 TrailCtl_D_Stat 7 "Faulty" 6 "DescentOnly" 5 "EnabledDeny" 4 "StandbyOverThreshold" 3 "StandbyOverride" 2 "Active" 1 "EnabledDescent" 0 "Off" ;
VAL_ 1054 TrailCtlMsgTxt_D_Rq 15 "Message15" 14 "Message14" 13 "Message13" 12 "Message12" 11 "Message11" 10 "Message10" 9 "Message9" 8 "Message8" 7 "Message7" 6 "Message6" 5 "Message5" 4 "Message4" 3 "Message3" 2 "Message2" 1 "Message1" 0 "NoMessage" ;
VAL_ 1054 BrkPadMsgTxt_D_Rq 3 "Faulty" 2 "PadsOk" 1 "ReplacePads" 0 "Null" ;
VAL_ 1054 BrkBstrVac_D_Stat 3 "NotUsed" 2 "BoosterVacEstimator" 1 "BoosterVacSensor" 0 "NoBoosterVacuumMonitor" ;
VAL_ 1054 DrvSlipCtlOffLamp_D_Rq 3 "Fast_Flash" 2 "Slow_Flash" 1 "On" 0 "Off" ;
VAL_ 1054 DrvSlipCtlMdeMsg_D_Rq 31 "Message31" 30 "Message30" 29 "Message29" 28 "Message28" 27 "Message27" 26 "Message26" 25 "Message25" 24 "Message24" 23 "Message23" 22 "Message22" 21 "Message21" 20 "Message20" 19 "Message19" 18 "Message18" 17 "Message17" 16 "Message16" 15 "Message15" 14 "Message14" 13 "Message13" 12 "Message12" 11 "Message11" 10 "Message10" 9 "Message9" 8 "Message8" 7 "Message7" 6 "Message6" 5 "Message5" 4 "Message4" 3 "Message3" 2 "Message2" 1 "Message1" 0 "NoMessage" ;
VAL_ 1054 HdcOn_B_Ind 1 "On" 0 "Off" ;
VAL_ 1054 AutoHoldMsgTxt_D_Rq 15 "Message15" 14 "Message14" 13 "Message13" 12 "Message12" 11 "Message11" 10 "Message10" 9 "Message9" 8 "Message8" 7 "Message7" 6 "Message6" 5 "Message5" 4 "Message4" 3 "Message3" 2 "Message2" 1 "Message1" 0 "NoMessage" ;
VAL_ 1054 CtaBrk_D_Stat 3 "Denied" 2 "Active" 1 "Open" 0 "Closed" ;
VAL_ 1054 SelDrvMdeAwd_D_Rq 31 "Faulty" 30 "NotUsed_17" 29 "NotUsed_16" 28 "NotUsed_15" 27 "NotUsed_14" 26 "NotUsed_13" 25 "NotUsed_12" 24 "NotUsed_11" 23 "NotUsed_10" 22 "NotUsed_9" 21 "NotUsed_8" 20 "CustomMode" 19 "OnePedalDrive" 18 "DragMode" 17 "EvLaterChargeMode" 16 "EvNowMode" 15 "TrackMode" 14 "RoughRoadMode" 13 "NotAvailable" 12 "HighSpeedDesertMode_Baja" 11 "SportAdaptiveMode" 10 "RockCrawlMode" 9 "MudRutsMode" 8 "SandMode" 7 "EconomyMode" 6 "GrassGravelSnow" 5 "TowHaulMode" 4 "SportMode" 3 "Normal_4L" 2 "Normal_4A" 1 "Normal_2H" 0 "NormalMode" ;
VAL_ 1054 AutoHoldSwMde_B_Ind 1 "On" 0 "Off" ;
VAL_ 1054 AutoHoldMde_D_Ind 3 "Indication_3" 2 "Indication_2" 1 "Indication_1" 0 "Off" ;
VAL_ 1054 BrkMdeInhbt_B_RqDsply 1 "Yes" 0 "No" ;
VAL_ 1054 BrkLineLck_D_Stat 7 "NotUsed_3" 6 "NotUsed_2" 5 "NotUsed_1" 4 "NotAvailable" 3 "Off" 2 "Engaged" 1 "Initiated" 0 "Available" ;
VAL_ 1054 SelDrvMdeChassis_D_Rq 31 "Faulty" 30 "NotUsed17" 29 "NotUsed16" 28 "NotUsed15" 27 "NotUsed14" 26 "NotUsed13" 25 "NotUsed12" 24 "NotUsed11" 23 "NotUsed10" 22 "NotUsed9" 21 "NotUsed8" 20 "NotUsed7" 19 "NotUsed6" 18 "NotUsed5" 17 "NotUsed4" 16 "OnePedalDrive" 15 "DragMode" 14 "RoughRoadMode" 13 "TrackMode" 12 "HighSpeedDesertMode" 11 "TowHaulMode" 10 "RockCrawlMode" 9 "SandMode" 8 "MudAndRutsMode" 7 "LowMuMode" 6 "ComfortAdaptiveMode" 5 "ComfortMode" 4 "SportAdaptiveMode" 3 "SportMode" 2 "EconomyMode" 1 "NormalAdaptiveMode" 0 "NormalMode" ;
VAL_ 1054 ApaBrk_D_Stat 3 "Denied" 2 "Active" 1 "Open" 0 "Closed" ;
VAL_ 1054 SelDrvMdeChassis3_D_Rq 31 "Faulty" 30 "NotUsed17" 29 "NotUsed16" 28 "NotUsed15" 27 "NotUsed14" 26 "NotUsed13" 25 "NotUsed12" 24 "NotUsed11" 23 "NotUsed10" 22 "NotUsed9" 21 "NotUsed8" 20 "NotUsed7" 19 "NotUsed6" 18 "NotUsed5" 17 "NotUsed4" 16 "OnePedalDrive" 15 "DragMode" 14 "RoughRoadMode" 13 "TrackMode" 12 "HighSpeedDesertMode" 11 "TowHaulMode" 10 "RockCrawlMode" 9 "SandMode" 8 "MudAndRutsMode" 7 "LowMuMode" 6 "ComfortAdaptiveMode" 5 "ComfortMode" 4 "SportAdaptiveMode" 3 "SportMode" 2 "EconomyMode" 1 "NormalAdaptiveMode" 0 "NormalMode" ;
VAL_ 1054 TrailOnePdlTqLm_B_Actl 1 "Yes" 0 "No" ;
VAL_ 1054 OnePdlDrvDeny_B_Stat 1 "Yes" 0 "No" ;
VAL_ 1054 BrkDrvMde_D_Stat 7 "Faulty" 6 "RockCrawl" 5 "Baja" 4 "DragOrMudAndSand" 3 "Track" 2 "Snow_Wet" 1 "Sport" 0 "Normal" ;
VAL_ 1054 AirDamUp_B_RqBrk 1 "Up" 0 "NoRequest" ;
VAL_ 1054 FrontDiffElckrOpen_B_Rq 1 "Yes" 0 "No" ;
VAL_ 1046 PrkBrkDynmc_D_Allw 3 "NotUsed" 2 "EPB_ECD_NotPossible" 1 "EPB_ECD_Possible" 0 "Used_at_Start_Up" ;
VAL_ 1046 BrkPrkBrkDynmc_B_Actl 1 "Active" 0 "Inactive" ;
VAL_ 1046 HsaMde_D_Mem 3 "Undefined" 2 "Manual" 1 "Automatic" 0 "Off" ;
VAL_ 1046 BrkBstrVac_B_Rq 1 "Yes" 0 "No" ;
VAL_ 1046 HdcMde_D_Actl 7 "Fault" 6 "Temporarily_Unavailable" 5 "NotEnabled_WrongGearSel" 4 "NotEnabled_SpdLimitExceed" 3 "Active_Braking" 2 "Not_Active_Braking" 1 "Off" 0 "Undefined" ;
VAL_ 1046 RearDiffLck_Tq2_RqMx 4095 "Faulty" ;
VAL_ 1046 TRLR_SWAY_EVNT_IN_PROG 1 "Yes" 0 "No" ;
VAL_ 1046 TRLR_SWAY_CONFIG_STAT 1 "On" 0 "Off" ;
VAL_ 1046 TCMode 1 "Active" 0 "Inactive" ;
VAL_ 1046 DrvSlipCtlLamp_D_Rq 3 "Fast_Flash" 2 "Slow_Flash" 1 "On" 0 "Off" ;
VAL_ 1046 Abs_B_Falt 1 "Yes" 0 "No" ;
VAL_ 1046 DrvSlipCtlMde_D_Ind 3 "App_Specific_Off_Mode_3" 2 "App_Specific_Off_Mode_2" 1 "App_Specific_Off_Mode_1" 0 "Default_Mode" ;
VAL_ 1046 DrvAntiLckLamp_D_Rq 3 "Fast_Flash" 2 "Slow_Flash" 1 "On" 0 "Off" ;
VAL_ 1046 StabCtlBrk_B_Avail 1 "Yes" 0 "No" ;
VAL_ 1046 DrvHdcWarnInfo_D_Rq 3 "Undefined" 2 "Lamp_On_Continuously" 1 "Lamp_Flashing" 0 "Lamp_Off_Continuously" ;
VAL_ 1046 DrvHdcMsg_D_Rq 7 "Undefined" 6 "Speed_too_High" 5 "Temporarily_Unavailable" 4 "System_Fault" 3 "Select_Gear" 2 "Off" 1 "On" 0 "No_Message" ;
VAL_ 1046 DrvHdcLampInfo_D_Rq 3 "Fast_Flash" 2 "Slow_Flash" 1 "On" 0 "Off" ;
VAL_ 1046 BpedMove_D_Actl 3 "Unknown" 2 "DriverApplyingBrakePedal" 1 "NoAutonomousBrkPdlMovement" 0 "AutonomousBrkPedalMove" ;
VAL_ 1046 ChimeBrk_B_Rq 1 "Yes" 0 "No" ;
VAL_ 1046 BrkLamp_B_Rq 1 "Yes" 0 "No" ;
VAL_ 1046 HILL_DESC_MC 7 "Fault_Detected" 6 "Cooling_Down" 5 "Abort_Apply_Brakes" 4 "Active" 3 "Disabled" 2 "Enabled" 1 "Off_Road" 0 "Normal" ;
VAL_ 1046 RearDiffElckrOpen_B_Rq 1 "Yes" 0 "No" ;
VAL_ 1045 VehStab_D_Stat 15 "Faulty" 14 "No_Data_Exists" 13 "NotUsed6" 12 "NotUsed5" 11 "NotUsed4" 10 "NotUsed3" 9 "NotUsed2" 8 "Combined_OS_and_US" 7 "High_SSRA_no_OS" 6 "Straight" 5 "Post_Oversteer" 4 "Post_Transition" 3 "Countersteer" 2 "Understeer" 1 "Oversteer" 0 "Linear" ;
VAL_ 1045 BrkFluidLvl_D_Stat 3 "Invalid" 2 "Unknown" 1 "Low" 0 "OK" ;
VAL_ 1045 LsmcBrkDecel_D_Stat 7 "NotUsed_3" 6 "NotUsed_2" 5 "NotUsed_1" 4 "Denied" 3 "FaultDegraded" 2 "FaultExt" 1 "On" 0 "Off" ;
VAL_ 1045 VehYawNonLin_W_Rq 4095 "Fault" 4094 "Unknown" ;
VAL_ 1045 VehYawLin_W_Rq 4095 "Fault" 4094 "Unknown" ;
VAL_ 1045 VehVActlBrk_D_Qf 3 "OK" 2 "Not_Within_Specifications" 1 "No_Data_Exists" 0 "Faulty" ;
VAL_ 1044 ApaBrkErr_D_Stat 3 "Faulty" 2 "NoDataExists" 1 "Yes" 0 "No" ;
VAL_ 1044 StePinOffst_An_Est 65535 "Faulty" 65534 "NoDataExists" ;
VAL_ 1044 StePinOffst_D_Stat 3 "FineOffset" 2 "CoarseOffset" 1 "StoredOffset" 0 "OffsetNotCalculated" ;
VAL_ 1042 VehRol_An_Dsply 127 "Faulty" 126 "NoDataExists" ;
VAL_ 1042 RearDiffLck_Tq_RqMn 4095 "Faulty" ;
VAL_ 1042 VehPtch_An_Dsply 127 "Faulty" 126 "NoDataExists" ;
VAL_ 535 WhlRr_W_Meas 32767 "Fault" 32766 "Unknown" ;
VAL_ 535 WhlRl_W_Meas 32767 "Fault" 32766 "Unknown" ;
VAL_ 535 WhlFr_W_Meas 32767 "Fault" 32766 "Unknown" ;
VAL_ 535 WhlFl_W_Meas 32767 "Fault" 32766 "Unknown" ;
VAL_ 534 WhlDirRr_D_Actl 3 "Faulty" 2 "NoDataExists" 1 "Backward" 0 "Forward" ;
VAL_ 534 WhlDirRl_D_Actl 3 "Faulty" 2 "NoDataExists" 1 "Backward" 0 "Forward" ;
VAL_ 534 WhlDirFr_D_Actl 3 "Faulty" 2 "NoDataExists" 1 "Backward" 0 "Forward" ;
VAL_ 534 WhlDirFl_D_Actl 3 "Faulty" 2 "NoDataExists" 1 "Backward" 0 "Forward" ;
VAL_ 532 RgenTqFalt_B_Actl 1 "Fault" 0 "No_Fault" ;
VAL_ 532 RgenBrkDynoMde_B_Actl 1 "TwoWheelDyno" 0 "NormalOperation" ;
VAL_ 1264 ElCmpr2ULo_D_Falt 3 "NotUsed" 2 "Pass" 1 "Fail" 0 "Not_Diagnose_Yet" ;
VAL_ 1264 ElCmpr2Te_D_Stat 3 "OverTempStop" 2 "OverTempWarning" 1 "Normal" 0 "Undefined" ;
VAL_ 1264 ElCmpr2Te_D_Falt 3 "NotUsed" 2 "Pass" 1 "Fail" 0 "Not_Diagnose_Yet" ;
VAL_ 1264 ElCmpr2Perf_D_Falt 3 "NotUsed" 2 "Pass" 1 "Fail" 0 "Not_Diagnose_Yet" ;
VAL_ 1264 ElCmpr2Load_D_Falt 3 "NotUsed" 2 "Pass" 1 "Fail" 0 "Not_Diagnose_Yet" ;
VAL_ 1264 ElCmpr2Err_D_Falt 3 "NotUsed" 2 "Pass" 1 "Fail" 0 "Not_Diagnose_Yet" ;
VAL_ 1264 ElCmpr2Comm_D_Falt 3 "NotUsed" 2 "Pass" 1 "Fail" 0 "Not_Diagnose_Yet" ;
VAL_ 1264 ElCmpr2AinURng_D_Falt 3 "NotUsed" 2 "Pass" 1 "Fail" 0 "Not_Diagnose_Yet" ;
VAL_ 1264 ElCmpr2AinU_D_Stat 3 "Overvoltage" 2 "Undervoltage" 1 "InRange" 0 "Undetermined" ;
VAL_ 1264 ElCmpr2AinU_D_Falt 3 "NotUsed" 2 "Pass" 1 "Fail" 0 "Not_Diagnose_Yet" ;
VAL_ 1264 ElCmpr2_Pw_Actl 255 "Faulty" ;
VAL_ 1264 ElCmpr2_N_Actl 255 "Faulty" ;
VAL_ 1264 ElCmpr2_D_Stat 7 "Signal_Invalid" 6 "Comp_Off_ActlSpd_Abnormal" 5 "Comp_Off_TrgtSpd_OutRange" 4 "Comp_Shutdown" 3 "Comp_Stopped_Self_Protect" 2 "Comp_Degraded" 1 "Comp_On" 0 "Comp_Off" ;
VAL_ 531 PrkBrkMsgTxt_D_Rq 15 "Message15" 14 "Message14" 13 "Message13" 12 "Message12" 11 "Message11" 10 "Message10" 9 "Message9" 8 "Message8" 7 "Message7" 6 "Message6" 5 "Message5" 4 "Message4" 3 "Message3" 2 "Message2" 1 "Message1" 0 "No_Message" ;
VAL_ 531 VehStop_D_Stat 3 "Faulty" 2 "NoDataExists" 1 "Yes" 0 "No" ;
VAL_ 531 TracCtlPtActv_B_Actl 1 "Active" 0 "Inactive" ;
VAL_ 531 LscmbbMntr_B_Err 1 "DisplayMessage" 0 "NoMessage" ;
VAL_ 531 LscmbbBrkDis_B_Actl 1 "Yes" 0 "No" ;
VAL_ 531 LscmbbDeny_B_ActlBrk 1 "Yes" 0 "No" ;
VAL_ 531 VehicleStationary 1 "Yes" 0 "No" ;
VAL_ 531 LscmbbBrkDecel_B_Actl 1 "Yes" 0 "No" ;
VAL_ 531 AbsActv_B_Actl 1 "Yes" 0 "No" ;
VAL_ 531 StabCtlBrkActv_B_Actl 1 "Yes" 0 "No" ;
VAL_ 531 CmbbBrkPrchg_B_Actl 1 "Yes" 0 "No" ;
VAL_ 531 CmbbBrkDecel_B_Actl 1 "Yes" 0 "No" ;
VAL_ 531 CmbbBaSensInc_B_Actl 1 "Yes" 0 "No" ;
VAL_ 531 AccBrkWarm_B_Actl 1 "Yes" 0 "No" ;
VAL_ 531 AccBrkTotTqMn_B_Actl 1 "Yes" 0 "No" ;
VAL_ 531 AccBrkPrchgActv_B_Actl 1 "Yes" 0 "No" ;
VAL_ 531 AccBrkDis_B_Actl 1 "Yes" 0 "No" ;
VAL_ 531 AccBrkDeny_B_Actl 1 "Yes" 0 "No" ;
VAL_ 531 AccBrkActv_B_Actl 1 "Yes" 0 "No" ;
VAL_ 531 PrplDrgCtlActv_B_Actl 1 "Active" 0 "Inactive" ;
VAL_ 531 LscmbbBaSensInc_B_Actl 1 "Yes" 0 "No" ;
VAL_ 531 CmbbBrkDis_B_Actl 1 "Yes" 0 "No" ;
VAL_ 531 CmbbDeny_B_ActlBrk 1 "Yes" 0 "No" ;
VAL_ 531 CcDis_B_Cmd 1 "Yes" 0 "No" ;
VAL_ 531 VehLongOvrGnd_A_Est 1023 "Fault" 1022 "Unknown" ;
VAL_ 531 LscmbBrkPrchg_B_Actl 1 "Active" 0 "Inactive" ;
VAL_ 531 AccStopActv_B_ActlBrk 1 "Yes" 0 "No" ;
VAL_ 531 AccDis_B_ActlEpb 1 "Yes" 0 "No" ;
VAL_ 531 PrkBrkStatus 7 "GeneralFault_MaintenceMode" 6 "ECD_by_Brake_ECU_Active" 5 "EPB_Limphome_Active" 4 "Rear_Caliper_Open" 3 "RWU_By_EPB_Active" 2 "Rear_Caliper_Transition" 1 "Rear_Caliper_Closed" 0 "Not_Supported" ;
VAL_ 531 PrkBrkYwLamp_D_Rq 3 "Fast_Flash" 2 "Slow_Flash" 1 "On" 0 "Off" ;
VAL_ 531 PrkBrkRedLamp_D_Rq 3 "Fast_Flash" 2 "Slow_Flash" 1 "On" 0 "Off" ;
VAL_ 136 SteWhlBrkOffst_An_Rq 32767 "Faulty" 32766 "NoDataExists" ;
